VERSION "HNNBNNNYNNNNNNNNNNNNNNNNNNNNNNNNNNNNNNNNNN/4/%%%/4/'%**4NNN///"

NS_ :

BS_:

BU_: AEM BAP_Tester E_Sound FBK FLA Gateway Gateway_PAG ISE MRR_HL MRR_HR NightVision RDK SAK SAK2 SCR STH_MLBevo TopView

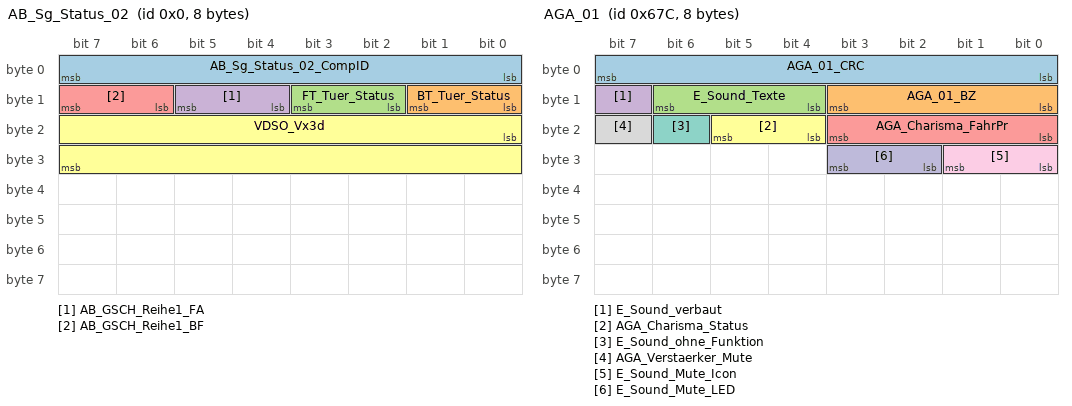
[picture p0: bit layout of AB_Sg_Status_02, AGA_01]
BO_ 0 AB_Sg_Status_02: 8 Gateway
 SG_ AB_Sg_Status_02_CompID : 0|8@1+ (1.0,0.0) [0.0|255] ""  Vector__XXX
 SG_ BT_Tuer_Status : 8|2@1+ (1.0,0.0) [0.0|3] ""  Vector__XXX
 SG_ FT_Tuer_Status : 10|2@1+ (1.0,0.0) [0.0|3] ""  Vector__XXX
 SG_ AB_GSCH_Reihe1_FA : 12|2@1+ (1.0,0.0) [0.0|3] ""  Vector__XXX
 SG_ AB_GSCH_Reihe1_BF : 14|2@1+ (1.0,0.0) [0.0|3] ""  Vector__XXX
 SG_ VDSO_Vx3d : 16|16@1+ (0.0039,-127.7874) [-127.7874|127.7913] "Unit_MeterPerSecon"  FBK

BO_ 1469 AEM_01: 8 AEM
 SG_ AEM_Temp_Abschaltung : 58|2@1+ (1.0,0.0) [0.0|3] ""  Gateway,Gateway_PAG
 SG_ AEM_Status_Regelung : 60|3@1+ (1.0,0.0) [0.0|7] ""  Gateway,Gateway_PAG

BO_ 1660 AGA_01: 8 E_Sound
 SG_ AGA_01_CRC : 0|8@1+ (1,0) [0|255] ""  Gateway,Gateway_PAG
 SG_ AGA_01_BZ : 8|4@1+ (1,0) [0|15] ""  Gateway,Gateway_PAG
 SG_ E_Sound_Texte : 12|3@1+ (1.0,0.0) [0.0|7] ""  Gateway,Gateway_PAG,ISE
 SG_ E_Sound_verbaut : 15|1@1+ (1.0,0.0) [0.0|1] ""  Gateway,Gateway_PAG
 SG_ AGA_Charisma_FahrPr : 16|4@1+ (1.0,0.0) [0.0|15] ""  Gateway,Gateway_PAG
 SG_ AGA_Charisma_Status : 20|2@1+ (1.0,0.0) [0.0|3] ""  Gateway,Gateway_PAG
 SG_ E_Sound_ohne_Funktion : 22|1@1+ (1.0,0.0) [0.0|1] ""  Gateway,Gateway_PAG
 SG_ AGA_Verstaerker_Mute : 23|1@1+ (1.0,0.0) [0.0|1] ""  Gateway,Gateway_PAG
 SG_ E_Sound_Mute_Icon : 24|2@1+ (1.0,0.0) [0.0|3] ""  Gateway,Gateway_PAG
 SG_ E_Sound_Mute_LED : 26|2@1+ (1.0,0.0) [0.0|3] ""  Gateway,Gateway_PAG

BO_ 64 Airbag_01: 8 Gateway
 SG_ Airbag_01_CRC : 0|8@1+ (1,0) [0|255] ""  Vector__XXX
 SG_ Airbag_01_BZ : 8|4@1+ (1,0) [0|15] ""  Vector__XXX
 SG_ AB_RGS_Anst : 12|4@1+ (1.0,0.0) [0.0|15] ""  Vector__XXX
 SG_ AB_Front_Crash : 16|1@1+ (1.0,0.0) [0.0|1] ""  Vector__XXX
 SG_ AB_Heck_Crash : 17|1@1+ (1.0,0.0) [0.0|1] ""  Vector__XXX
 SG_ AB_SF_Crash : 18|1@1+ (1.0,0.0) [0.0|1] ""  Vector__XXX
 SG_ AB_SB_Crash : 19|1@1+ (1.0,0.0) [0.0|1] ""  Vector__XXX
 SG_ AB_Rollover_Crash : 20|1@1+ (1.0,0.0) [0.0|1] ""  Vector__XXX
 SG_ AB_Crash_Int : 21|3@1+ (1.0,0.0) [0.0|7] ""  E_Sound,ISE,STH_MLBevo
 SG_ AB_Lampe : 24|1@1+ (1.0,0.0) [0.0|1] ""  Vector__XXX
 SG_ AB_Deaktiviert : 25|1@1+ (1.0,0.0) [0.0|1] ""  Vector__XXX
 SG_ AB_VB_deaktiviert : 26|1@1+ (1.0,0.0) [0.0|1] ""  Vector__XXX
 SG_ AB_Systemfehler : 27|1@1+ (1.0,0.0) [0.0|1] ""  Vector__XXX
 SG_ AB_Diagnose : 28|1@1+ (1.0,0.0) [0.0|1] ""  Vector__XXX
 SG_ AB_Stellgliedtest : 29|1@1+ (1.0,0.0) [0.0|1] ""  STH_MLBevo
 SG_ AB_Erh_Auf_VB : 30|2@1+ (1.0,0.0) [0.0|3] ""  Vector__XXX
 SG_ AB_Gurtwarn_VF : 32|1@1+ (1.0,0.0) [0.0|1] ""  Vector__XXX
 SG_ AB_Gurtwarn_VB : 33|1@1+ (1.0,0.0) [0.0|1] ""  Vector__XXX
 SG_ AB_Anzeige_Fussg : 34|2@1+ (1.0,0.0) [0.0|3] ""  Vector__XXX
 SG_ AB_Texte_AKS : 36|2@1+ (1.0,0.0) [0.0|3] ""  Vector__XXX
 SG_ AB_MKB_gueltig : 39|1@1+ (1.0,0.0) [0.0|1] ""  Vector__XXX
 SG_ AB_MKB_Anforderung : 40|1@1+ (1.0,0.0) [0.0|1] ""  Vector__XXX
 SG_ AB_Versorgungsspannung : 41|1@1+ (1.0,0.0) [0.0|1] ""  Vector__XXX
 SG_ AB_Deaktivierung_HV : 42|3@1+ (1.0,0.0) [0.0|7] ""  Vector__XXX
 SG_ AB_EDR_Trigger : 45|2@1+ (1.0,0.0) [0.0|3] ""  Vector__XXX
 SG_ AB_Belegung_VF : 47|2@1+ (1.0,0.0) [0.0|3] ""  FBK
 SG_ SC_Masterzeit_Offset : 53|2@1+ (5.08,0) [0.00|15.24] "Unit_Secon"  Vector__XXX
 SG_ SC_LowSpeedCrashErkannt : 55|2@1+ (1.0,0.0) [0.0|3] ""  Vector__XXX
 SG_ SC_Masterzeit : 57|7@1+ (0.04,0) [0.00|5.04] "Unit_Secon"  NightVision

BO_ 1312 Airbag_02: 8 Gateway
 SG_ Airbag_02_CRC : 0|8@1+ (1,0) [0|255] ""  Vector__XXX
 SG_ Airbag_02_BZ : 8|4@1+ (1,0) [0|15] ""  Vector__XXX
 SG_ LoGeWa_Event_Kombiwarnung : 12|4@1+ (1.0,0.0) [0.0|15] ""  Vector__XXX
 SG_ AB_Anforderung_eCall : 16|1@1+ (1.0,0.0) [0.0|1] ""  Vector__XXX
 SG_ AB_Anprall_Seite_Beifahrer : 17|1@1+ (1.0,0.0) [0.0|1] ""  Vector__XXX
 SG_ AB_Anprall_Rollover : 18|1@1+ (1.0,0.0) [0.0|1] ""  Vector__XXX
 SG_ AB_Anprall_FGS : 19|1@1+ (1.0,0.0) [0.0|1] ""  Vector__XXX
 SG_ AB_Anprall_Front_Beifahrer : 20|1@1+ (1.0,0.0) [0.0|1] ""  Vector__XXX
 SG_ AB_Anprall_Front_Fahrer : 21|1@1+ (1.0,0.0) [0.0|1] ""  Vector__XXX
 SG_ AB_Anprall_Heck_Beifahrer : 22|1@1+ (1.0,0.0) [0.0|1] ""  Vector__XXX
 SG_ AB_Anprall_Heck_Fahrer : 23|1@1+ (1.0,0.0) [0.0|1] ""  Vector__XXX
 SG_ AB_Wickelklappung_Reihe2_MI : 24|2@1+ (1.0,0.0) [0.0|3] ""  Vector__XXX
 SG_ AB_Belegung_VB : 26|2@1+ (1.0,0.0) [0.0|3] ""  FBK
 SG_ AB_Abschaltanf_SIH_BF : 28|1@1+ (1.0,0.0) [0.0|1] ""  Vector__XXX
 SG_ AB_Anprall_Seite_Fahrer : 29|1@1+ (1.0,0.0) [0.0|1] ""  Vector__XXX
 SG_ SC_PAO_Schriftzug_Anf : 30|2@1+ (1.0,0.0) [0.0|3] ""  Vector__XXX
 SG_ SC_PAO_ON_Anf : 32|2@1+ (1.0,0.0) [0.0|3] ""  Vector__XXX
 SG_ SC_PAO_OFF_Anf : 34|2@1+ (1.0,0.0) [0.0|3] ""  Vector__XXX
 SG_ AB_Crashschwere : 36|3@1+ (1.0,0.0) [0.0|7] ""  Vector__XXX
 SG_ AB_Anforderung_USM : 39|1@1+ (1.0,0.0) [0.0|1] ""  Vector__XXX
 SG_ AB_Gurtschloss_FA : 40|2@1+ (1.0,0.0) [0.0|3] ""  FBK
 SG_ AB_Gurtschloss_BF : 42|2@1+ (1.0,0.0) [0.0|3] ""  FBK
 SG_ AB_Gurtschloss_Reihe2_FA : 44|2@1+ (1.0,0.0) [0.0|3] ""  FBK
 SG_ AB_Gurtschloss_Reihe2_MI : 46|2@1+ (1.0,0.0) [0.0|3] ""  FBK
 SG_ AB_Gurtschloss_Reihe2_BF : 48|2@1+ (1.0,0.0) [0.0|3] ""  FBK
 SG_ AB_Gurtschloss_Reihe3_FA : 50|2@1+ (1.0,0.0) [0.0|3] ""  FBK
 SG_ AB_Gurtschloss_Reihe3_MI : 52|2@1+ (1.0,0.0) [0.0|3] ""  FBK
 SG_ AB_Gurtschloss_Reihe3_BF : 54|2@1+ (1.0,0.0) [0.0|3] ""  FBK
 SG_ AB_Sitzpos_Sens_FA : 56|2@1+ (1.0,0.0) [0.0|3] ""  Vector__XXX
 SG_ AB_Sitzpos_Sens_BF : 58|2@1+ (1.0,0.0) [0.0|3] ""  Vector__XXX
 SG_ AB_Wickelklappung_Reihe2_BF : 60|2@1+ (1.0,0.0) [0.0|3] ""  Vector__XXX
 SG_ AB_Wickelklappung_Reihe2_FA : 62|2@1+ (1.0,0.0) [0.0|3] ""  Vector__XXX

BO_ 1349 Airbag_04: 8 Gateway
 SG_ AB_Gurtwarn_Reihe2_FA : 20|2@1+ (1.0,0.0) [0.0|3] ""  Vector__XXX
 SG_ AB_Gurtwarn_Reihe2_BF : 22|2@1+ (1.0,0.0) [0.0|3] ""  Vector__XXX
 SG_ AbstWarn_MV_FAS_Fkt_Status : 24|2@1+ (1.0,0.0) [0.0|3] ""  Vector__XXX
 SG_ WarnBrems_Charisma_Status : 26|2@1+ (1.0,0.0) [0.0|3] ""  Vector__XXX
 SG_ WarnBrems_Charisma_FahrPr : 28|4@1+ (1.0,0.0) [0.0|15] ""  Vector__XXX
 SG_ AB_Gurtwarn_Reihe2_MI : 32|2@1+ (1.0,0.0) [0.0|3] ""  Vector__XXX
 SG_ AB_Gurtwarn_Reihe3_FA : 34|2@1+ (1.0,0.0) [0.0|3] ""  Vector__XXX
 SG_ AB_Gurtwarn_Reihe3_MI : 36|2@1+ (1.0,0.0) [0.0|3] ""  Vector__XXX
 SG_ AB_Gurtwarn_Reihe3_BF : 38|2@1+ (1.0,0.0) [0.0|3] ""  Vector__XXX
 SG_ LGI_FAS_Fkt_Status : 40|2@1+ (1.0,0.0) [0.0|3] ""  Vector__XXX
 SG_ PreCrash_FAS_Fkt_Status : 42|3@1+ (1.0,0.0) [0.0|7] ""  Vector__XXX
 SG_ AB_SBR_hinten_verbau : 48|2@1+ (1.0,0.0) [0.0|3] ""  Vector__XXX
 SG_ AWV_Einstellung_System_ASG : 51|1@1+ (1.0,0.0) [0.0|1] ""  Vector__XXX
 SG_ AWV_Einstellung_Warnung_ASG : 52|3@1+ (1.0,0.0) [0.0|7] ""  Vector__XXX
 SG_ SC_PreSense_Modus_Warnung_NV : 55|3@1+ (1.0,0.0) [0.0|7] ""  NightVision
 SG_ SC_PreSense_Modus_Warnung_MV : 58|3@1+ (1.0,0.0) [0.0|7] ""  Vector__XXX
 SG_ SC_PreSense_Modus_System_MV : 61|1@1+ (1.0,0.0) [0.0|1] ""  Vector__XXX
 SG_ SC_PreSense_Modus_System_NV : 62|1@1+ (1.0,0.0) [0.0|1] ""  NightVision
 SG_ SC_PreSense_Modus_System_KAS : 63|1@1+ (1.0,0.0) [0.0|1] ""  Vector__XXX

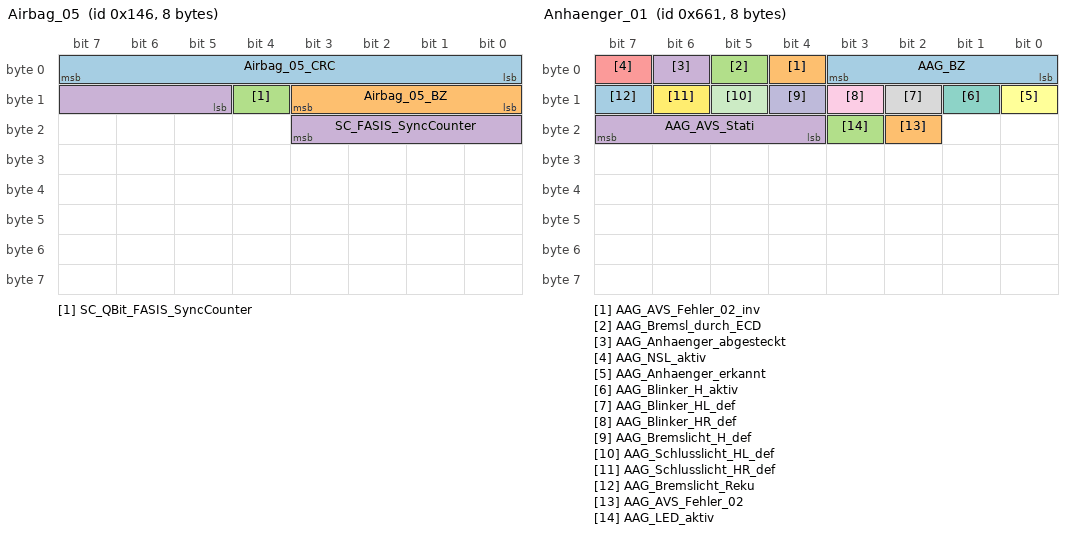
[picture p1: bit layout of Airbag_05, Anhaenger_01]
BO_ 326 Airbag_05: 8 Gateway
 SG_ Airbag_05_CRC : 0|8@1+ (1,0) [0|255] ""  NightVision
 SG_ Airbag_05_BZ : 8|4@1+ (1,0) [0|15] ""  NightVision
 SG_ SC_QBit_FASIS_SyncCounter : 12|1@1+ (1.0,0.0) [0.0|1] ""  NightVision
 SG_ SC_FASIS_SyncCounter : 13|7@1+ (1,0) [0|127] "Unit_None"  NightVision

BO_ 1633 Anhaenger_01: 8 Gateway
 SG_ AAG_BZ : 0|4@1+ (1,0) [0|15] ""  Vector__XXX
 SG_ AAG_AVS_Fehler_02_inv : 4|1@1+ (1.0,0.0) [0.0|1] ""  Vector__XXX
 SG_ AAG_Bremsl_durch_ECD : 5|1@1+ (1.0,0.0) [0.0|1] ""  Vector__XXX
 SG_ AAG_Anhaenger_abgesteckt : 6|1@1+ (1.0,0.0) [0.0|1] ""  Vector__XXX
 SG_ AAG_NSL_aktiv : 7|1@1+ (1.0,0.0) [0.0|1] ""  Vector__XXX
 SG_ AAG_Anhaenger_erkannt : 8|1@1+ (1.0,0.0) [0.0|1] ""  MRR_HL,MRR_HR,TopView
 SG_ AAG_Blinker_H_aktiv : 9|1@1+ (1.0,0.0) [0.0|1] ""  Vector__XXX
 SG_ AAG_Blinker_HL_def : 10|1@1+ (1.0,0.0) [0.0|1] ""  Vector__XXX
 SG_ AAG_Blinker_HR_def : 11|1@1+ (1.0,0.0) [0.0|1] ""  Vector__XXX
 SG_ AAG_Bremslicht_H_def : 12|1@1+ (1.0,0.0) [0.0|1] ""  Vector__XXX
 SG_ AAG_Schlusslicht_HL_def : 13|1@1+ (1.0,0.0) [0.0|1] ""  Vector__XXX
 SG_ AAG_Schlusslicht_HR_def : 14|1@1+ (1.0,0.0) [0.0|1] ""  Vector__XXX
 SG_ AAG_Bremslicht_Reku : 15|1@1+ (1.0,0.0) [0.0|1] ""  Vector__XXX
 SG_ AAG_AVS_Fehler_02 : 18|1@1+ (1.0,0.0) [0.0|1] ""  Vector__XXX
 SG_ AAG_LED_aktiv : 19|1@1+ (1.0,0.0) [0.0|1] ""  Vector__XXX
 SG_ AAG_AVS_Stati : 20|4@1+ (1.0,0.0) [0.0|15] ""  Vector__XXX

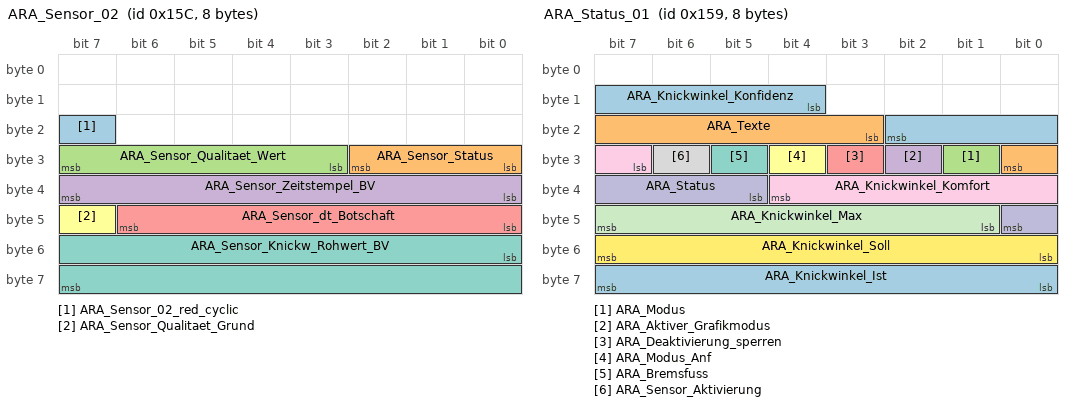
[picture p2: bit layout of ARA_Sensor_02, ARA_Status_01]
BO_ 348 ARA_Sensor_02: 8 TopView
 SG_ ARA_Sensor_02_red_cyclic : 23|1@1+ (1.0,0.0) [0.0|1] ""  Gateway,Gateway_PAG
 SG_ ARA_Sensor_Status : 24|3@1+ (1.0,0.0) [0.0|7] ""  Gateway,Gateway_PAG
 SG_ ARA_Sensor_Qualitaet_Wert : 27|5@1+ (0.04,0) [0.00|1.24] "Unit_None"  Gateway,Gateway_PAG
 SG_ ARA_Sensor_Zeitstempel_BV : 32|8@1+ (0.01,0) [0.00|2.55] "Unit_Secon"  Gateway,Gateway_PAG
 SG_ ARA_Sensor_dt_Botschaft : 40|7@1+ (0.01,0) [0.00|1.27] "Unit_Secon"  Gateway,Gateway_PAG
 SG_ ARA_Sensor_Qualitaet_Grund : 47|1@1+ (1.0,0.0) [0.0|1] ""  Gateway,Gateway_PAG
 SG_ ARA_Sensor_Knickw_Rohwert_BV : 48|16@1+ (0.0055,-180) [-180.0000|179.9970] "Unit_DegreOfArc"  Gateway,Gateway_PAG

BO_ 345 ARA_Status_01: 8 Gateway
 SG_ ARA_Knickwinkel_Konfidenz : 12|7@1+ (1,0) [0|120] "Unit_DegreOfArc"  TopView
 SG_ ARA_Texte : 19|6@1+ (1.0,0.0) [0.0|63] ""  Vector__XXX
 SG_ ARA_Modus : 25|1@1+ (1.0,0.0) [0.0|1] ""  Vector__XXX
 SG_ ARA_Aktiver_Grafikmodus : 26|1@1+ (1.0,0.0) [0.0|1] ""  Vector__XXX
 SG_ ARA_Deaktivierung_sperren : 27|1@1+ (1.0,0.0) [0.0|1] ""  TopView
 SG_ ARA_Modus_Anf : 28|1@1+ (1.0,0.0) [0.0|1] ""  Vector__XXX
 SG_ ARA_Bremsfuss : 29|1@1+ (1.0,0.0) [0.0|1] ""  Vector__XXX
 SG_ ARA_Sensor_Aktivierung : 30|1@1+ (1.0,0.0) [0.0|1] ""  TopView
 SG_ ARA_Knickwinkel_Komfort : 31|6@1+ (1,0) [0|60] "Unit_DegreOfArc"  TopView
 SG_ ARA_Status : 37|4@1+ (1.0,0.0) [0.0|15] ""  TopView
 SG_ ARA_Knickwinkel_Max : 41|7@1+ (1,0) [0|120] "Unit_DegreOfArc"  TopView
 SG_ ARA_Knickwinkel_Soll : 48|8@1+ (1,-125) [-125|126] "Unit_DegreOfArc"  TopView
 SG_ ARA_Knickwinkel_Ist : 56|8@1+ (1,-125) [-125|126] "Unit_DegreOfArc"  TopView

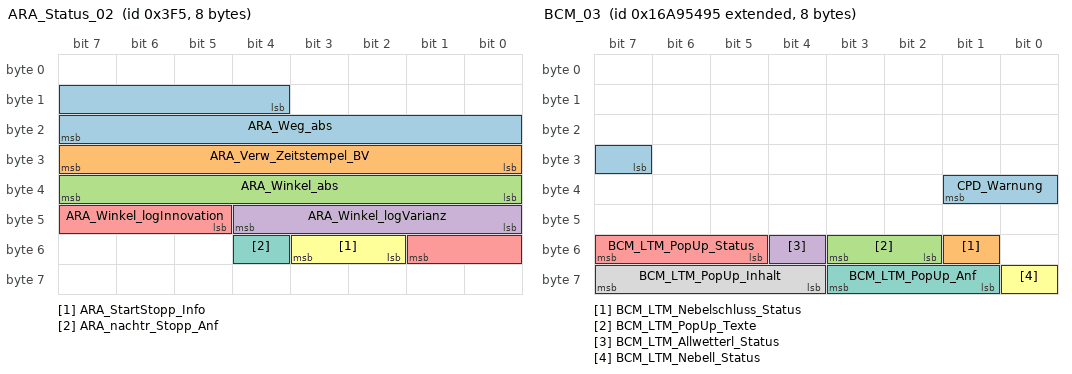
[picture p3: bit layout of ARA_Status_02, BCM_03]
BO_ 1013 ARA_Status_02: 8 Gateway
 SG_ ARA_Weg_abs : 12|12@1+ (1,0) [0|4095] "Unit_MilliMeter"  TopView
 SG_ ARA_Verw_Zeitstempel_BV : 24|8@1+ (0.01,0) [0.00|2.55] "Unit_Secon"  TopView
 SG_ ARA_Winkel_abs : 32|8@1+ (0.01,-1.2) [-1.20|1.20] "Unit_Radia"  TopView
 SG_ ARA_Winkel_logVarianz : 40|5@1+ (1,0) [0|31] "Unit_SquarRadia"  TopView
 SG_ ARA_Winkel_logInnovation : 45|5@1+ (1,0) [0|31] "Unit_SquarRadia"  TopView
 SG_ ARA_StartStopp_Info : 50|2@1+ (1.0,0.0) [0.0|3] ""  Vector__XXX
 SG_ ARA_nachtr_Stopp_Anf : 52|1@1+ (1.0,0.0) [0.0|1] ""  Vector__XXX

BO_ 2536767264 BAP_Debug_Cmd: 8 BAP_Tester
 SG_ BAP_Debug_Cmd : 0|16@1+ (1.0,0.0) [0.0|65535] ""  E_Sound,Gateway,Gateway_PAG,MRR_HR,NightVision,RDK,TopView

BO_ 2536767280 BAP_Debug_Data: 8 E_Sound
 SG_ BAP_Debug_Data : 0|64@1+ (1.0,0.0) [0.0|18446744073709551615] ""  BAP_Tester

BO_ 2536708096 BAP_Nightvision_ASG_01: 8 Gateway
 SG_ BAP_Nightvision_ASG_01_Header : 0|8@1+ (1.0,0.0) [0.0|255] ""  NightVision

BO_ 2536708097 BAP_Nightvision_ASG_02: 8 Gateway
 SG_ BAP_Nightvision_ASG_02_Header : 0|8@1+ (1.0,0.0) [0.0|255] ""  NightVision

BO_ 2536708112 BAP_Nightvision_FSG_01: 8 NightVision
 SG_ BAP_Nightvision_FSG_01_Header : 0|8@1+ (1.0,0.0) [0.0|255] ""  Gateway,Gateway_PAG

BO_ 2536704513 BAP_OPS_ASG_02: 8 TopView
 SG_ BAP_OPS_ASG_02_Header : 0|8@1+ (1.0,0.0) [0.0|255] ""  Gateway,Gateway_PAG

BO_ 2536704528 BAP_OPS_FSG_01: 8 Gateway
 SG_ BAP_OPS_FSG_01_Header : 0|8@1+ (1.0,0.0) [0.0|255] ""  TopView

BO_ 2536704529 BAP_OPS_FSG_02: 8 Gateway
 SG_ BAP_OPS_FSG_02_Header : 0|8@1+ (1.0,0.0) [0.0|255] ""  TopView

BO_ 2536703744 BAP_RDK_ASG_01: 8 Gateway
 SG_ BAP_RDK_ASG_01_Header : 0|8@1+ (1.0,0.0) [0.0|255] ""  RDK

BO_ 2536703745 BAP_RDK_ASG_02: 8 Gateway
 SG_ BAP_RDK_ASG_02_Header : 0|8@1+ (1.0,0.0) [0.0|255] ""  RDK

BO_ 2536703746 BAP_RDK_ASG_03: 8 Gateway
 SG_ BAP_RDK_ASG_03_Header : 0|8@1+ (1.0,0.0) [0.0|255] ""  RDK

BO_ 2536703760 BAP_RDK_FSG_01: 8 RDK
 SG_ BAP_RDK_FSG_01_Header : 0|8@1+ (1.0,0.0) [0.0|255] ""  Gateway,Gateway_PAG

BO_ 2536704768 BAP_RVC_ASG_01: 8 Gateway
 SG_ BAP_RVC_ASG_01_Header : 0|64@1+ (1.0,0.0) [0.0|18446744073709551615] ""  TopView

BO_ 2536704784 BAP_RVC_FSG_01: 8 TopView
 SG_ BAP_RVC_FSG_01_Header : 0|8@1+ (1.0,0.0) [0.0|255] ""  Gateway,Gateway_PAG

BO_ 2536728064 BAP_SoundControl2_ASG_01: 8 Gateway
 SG_ BAP_SoundControl2_ASG_01_Header : 0|64@1+ (1.0,0.0) [0.0|18446744073709551615] ""  ISE

BO_ 2536728080 BAP_SoundControl2_FSG_01: 8 ISE
 SG_ BAP_SoundControl2_FSG_01_Header : 0|64@1+ (1.0,0.0) [0.0|18446744073709551615] ""  Gateway,Gateway_PAG

BO_ 2536719360 BAP_SoundControl_ASG_01: 8 Gateway
 SG_ BAP_SoundControl_ASG_01_Header : 0|8@1+ (1,0) [0|255] "Unit_None"  E_Sound

BO_ 2536719376 BAP_SoundControl_FSG_01: 8 E_Sound
 SG_ BAP_SoundControl_FSG_01_Header : 0|8@1+ (1,0) [0|255] "Unit_None"  Gateway,Gateway_PAG

BO_ 2536708608 BAP_SWA_ASG_01: 8 Gateway
 SG_ BAP_SWA_ASG_01_Header : 0|8@1+ (1.0,0.0) [0.0|255] ""  MRR_HR

BO_ 2536708609 BAP_SWA_ASG_02: 8 Gateway
 SG_ BAP_SWA_ASG_02_Header : 0|8@1+ (1.0,0.0) [0.0|255] ""  MRR_HR

BO_ 2536708624 BAP_SWA_FSG_01: 8 MRR_HR
 SG_ BAP_SWA_FSG_01_Header : 0|8@1+ (1.0,0.0) [0.0|255] ""  Gateway,Gateway_PAG

BO_ 1626 BCM_01: 8 Gateway
 SG_ BCM_Bremsbelag_Sensor : 12|1@1+ (1.0,0.0) [0.0|1] ""  Vector__XXX
 SG_ BCM_Bremsfluessigkeit_Sensor : 13|1@1+ (1.0,0.0) [0.0|1] ""  Vector__XXX
 SG_ BCM1_Licht_Warn : 14|1@1+ (1.0,0.0) [0.0|1] ""  Vector__XXX
 SG_ BCM_Waschwasser_Sensor : 15|1@1+ (1.0,0.0) [0.0|1] ""  TopView
 SG_ BCM_Kuehlmittel_Sensor : 16|1@1+ (1.0,0.0) [0.0|1] ""  Vector__XXX
 SG_ BCM1_Kl_15_HW_erkannt : 17|1@1+ (1.0,0.0) [0.0|1] ""  Vector__XXX
 SG_ BCM1_Kl_15_Sig_HW_erkannt : 18|1@1+ (1.0,0.0) [0.0|1] ""  Vector__XXX
 SG_ BCM_Kuehlmittel_Sensor_02 : 19|1@1+ (1.0,0.0) [0.0|1] ""  Vector__XXX
 SG_ BCM1_Hinweis_Lichtnachlauf : 20|1@1+ (1.0,0.0) [0.0|1] ""  Vector__XXX
 SG_ BCM_Offroad_Taste : 21|1@1+ (1.0,0.0) [0.0|1] ""  Vector__XXX
 SG_ BCM_Hybrid_StSt_Taste_Fehler : 23|1@1+ (1.0,0.0) [0.0|1] ""  Vector__XXX
 SG_ BCM_Hybrid_StartStopp_Taste : 24|1@1+ (1.0,0.0) [0.0|1] ""  Vector__XXX
 SG_ BCM1_Warnblink_Taster : 25|1@1+ (1.0,0.0) [0.0|1] ""  Vector__XXX
 SG_ BCM1_Valet_Parking_Taster : 26|1@1+ (1.0,0.0) [0.0|1] ""  Vector__XXX
 SG_ BCM1_LDS_Stellung : 27|3@1+ (1.0,0.0) [0.0|7] ""  NightVision
 SG_ BCM1_Rueckfahrlicht_Schalter : 30|1@1+ (1.0,0.0) [0.0|1] ""  Vector__XXX
 SG_ BCM1_MH_Schalter : 31|1@1+ (1.0,0.0) [0.0|1] ""  TopView
 SG_ BCM1_MH_WIV_Schalter : 32|1@1+ (1.0,0.0) [0.0|1] ""  Vector__XXX
 SG_ BCM_Eco_Charisma_Taste : 33|1@1+ (1.0,0.0) [0.0|1] ""  Vector__XXX
 SG_ BCM1_NV_Taster : 34|1@1+ (1.0,0.0) [0.0|1] ""  NightVision
 SG_ BCM1_AFS_Lampe : 35|1@1+ (1.0,0.0) [0.0|1] ""  Vector__XXX
 SG_ BCM1_Reisemodus_Texte : 36|2@1+ (1.0,0.0) [0.0|3] ""  Vector__XXX
 SG_ BCM1_Lichtwarn_Texte : 38|2@1+ (1.0,0.0) [0.0|3] ""  Vector__XXX
 SG_ Gong_TFL_Umschaltung : 40|1@1+ (1.0,0.0) [0.0|1] ""  Vector__XXX
 SG_ UGDO_Function_01 : 41|3@1+ (1.0,0.0) [0.0|7] ""  Vector__XXX
 SG_ APS_Tongeber_defekt : 44|1@1+ (1.0,0.0) [0.0|1] ""  Vector__XXX
 SG_ BCM1_EasyEntry_Status : 45|1@1+ (1.0,0.0) [0.0|1] ""  Vector__XXX
 SG_ BCM1_Lenksaeule_aktiv : 46|1@1+ (1.0,0.0) [0.0|1] ""  FBK
 SG_ BCM1_St_SW_Diebstahl_links : 47|1@1+ (1.0,0.0) [0.0|1] ""  Vector__XXX
 SG_ BCM1_St_SW_Diebstahl_rechts : 48|1@1+ (1.0,0.0) [0.0|1] ""  Vector__XXX
 SG_ ISP_Dimmung_ASP_02 : 49|6@1+ (0.0226,0) [0.0000|1.4012] "Unit_Volt"  Vector__XXX
 SG_ BCM1_Schluesselsuche_Anf : 55|1@1+ (1.0,0.0) [0.0|1] ""  Vector__XXX
 SG_ BCM1_Fahrlicht_Hinweis : 62|1@1+ (1.0,0.0) [0.0|1] ""  Vector__XXX
 SG_ BCM_HDF_betaetigt : 63|1@1+ (1.0,0.0) [0.0|1] ""  Vector__XXX

BO_ 2527679637 BCM_03: 8 Gateway
 SG_ CPD_Warnung : 31|3@1+ (1.0,0.0) [0.0|7] ""  Vector__XXX
 SG_ BCM_LTM_Nebelschluss_Status : 49|1@1+ (1.0,0.0) [0.0|1] ""  Vector__XXX
 SG_ BCM_LTM_PopUp_Texte : 50|2@1+ (1.0,0.0) [0.0|3] ""  Vector__XXX
 SG_ BCM_LTM_Allwetterl_Status : 52|1@1+ (1.0,0.0) [0.0|1] ""  Vector__XXX
 SG_ BCM_LTM_PopUp_Status : 53|3@1+ (1.0,0.0) [0.0|7] ""  NightVision
 SG_ BCM_LTM_Nebell_Status : 56|1@1+ (1.0,0.0) [0.0|1] ""  Vector__XXX
 SG_ BCM_LTM_PopUp_Anf : 57|3@1+ (1.0,0.0) [0.0|7] ""  NightVision
 SG_ BCM_LTM_PopUp_Inhalt : 60|4@1+ (1.0,0.0) [0.0|15] ""  Vector__XXX

BO_ 961 BCM_Taster_01: 8 Gateway
 SG_ Heckrollo_2_Taster : 10|2@1+ (1.0,0.0) [0.0|3] ""  Vector__XXX
 SG_ APS_Taster : 12|2@1+ (1.0,0.0) [0.0|3] ""  Vector__XXX
 SG_ PLA_Taster : 14|2@1+ (1.0,0.0) [0.0|3] ""  Vector__XXX
 SG_ ESP_Off_Taster : 16|2@1+ (1.0,0.0) [0.0|3] ""  Vector__XXX
 SG_ HDC_Taster : 18|2@1+ (1.0,0.0) [0.0|3] ""  Vector__XXX
 SG_ AVH_Taster : 20|2@1+ (1.0,0.0) [0.0|3] ""  Vector__XXX
 SG_ Display_Taster : 22|2@1+ (1.0,0.0) [0.0|3] ""  Vector__XXX
 SG_ Heckrollo_Taster : 24|2@1+ (1.0,0.0) [0.0|3] ""  Vector__XXX
 SG_ Spoiler_Taster : 26|2@1+ (1.0,0.0) [0.0|3] ""  Vector__XXX
 SG_ Drivesel_1_Taster : 28|2@1+ (1.0,0.0) [0.0|3] ""  Vector__XXX
 SG_ Drivesel_2_Taster : 30|2@1+ (1.0,0.0) [0.0|3] ""  Vector__XXX
 SG_ Sideview_Taster : 32|2@1+ (1.0,0.0) [0.0|3] ""  TopView
 SG_ LIM_PAO_Alivesignal : 34|4@1+ (1,0) [0|15] ""  Vector__XXX
 SG_ LKS_Taster : 38|2@1+ (1.0,0.0) [0.0|3] ""  Vector__XXX
 SG_ SWA_Taster : 40|2@1+ (1.0,0.0) [0.0|3] ""  MRR_HR
 SG_ LIM_bCall_Taster : 42|1@1+ (1.0,0.0) [0.0|1] ""  Vector__XXX
 SG_ eCall_Taste : 43|2@1+ (1.0,0.0) [0.0|3] ""  Vector__XXX
 SG_ PLA_Taster_Fehler_Roh : 45|1@1+ (1.0,0.0) [0.0|1] ""  Vector__XXX
 SG_ LIM_PAO_ON_Status : 46|2@1+ (1.0,0.0) [0.0|3] ""  Vector__XXX
 SG_ LIM_PAO_OFF_Status : 48|2@1+ (1.0,0.0) [0.0|3] ""  Vector__XXX
 SG_ LIM_PAO_Schriftzug_Status : 50|2@1+ (1.0,0.0) [0.0|3] ""  Vector__XXX
 SG_ Spoiler_LED_Status : 52|2@1+ (1.0,0.0) [0.0|3] ""  Vector__XXX
 SG_ AVH_LED_Status : 54|2@1+ (1.0,0.0) [0.0|3] ""  Vector__XXX
 SG_ HDC_LED_Status : 56|2@1+ (1.0,0.0) [0.0|3] ""  Vector__XXX
 SG_ PLA_LED_Status : 60|2@1+ (1.0,0.0) [0.0|3] ""  Vector__XXX
 SG_ APS_LED_Status : 62|2@1+ (1.0,0.0) [0.0|3] ""  Vector__XXX

BO_ 1432 BCM_Taster_02: 8 Gateway
 SG_ BCM_BFS_Fernsteuerung_aktiv : 28|1@1+ (1.0,0.0) [0.0|1] ""  Vector__XXX
 SG_ BCM_Soundklappe_Taster : 29|1@1+ (1.0,0.0) [0.0|1] ""  ISE
 SG_ E_Sound_LED_Status : 30|2@1+ (1.0,0.0) [0.0|3] ""  E_Sound,ISE
 SG_ Pilot_Taster : 32|2@1+ (1.0,0.0) [0.0|3] ""  Vector__XXX
 SG_ BCM1_eSound_Taster : 34|2@1+ (1.0,0.0) [0.0|3] ""  E_Sound,ISE
 SG_ BCM_FS_Programmwippe : 37|1@1+ (1.0,0.0) [0.0|1] ""  Vector__XXX
 SG_ BCM_BFS_Programmwippe : 38|1@1+ (1.0,0.0) [0.0|1] ""  Vector__XXX
 SG_ BCM_FS_Multif_Taster : 39|1@1+ (1.0,0.0) [0.0|1] ""  Vector__XXX
 SG_ BCM_BFS_Multif_Taster : 40|1@1+ (1.0,0.0) [0.0|1] ""  Vector__XXX
 SG_ BCM_FS_Massage_Taster : 41|1@1+ (1.0,0.0) [0.0|1] ""  Vector__XXX
 SG_ BCM_BFS_Massage_Taster : 42|1@1+ (1.0,0.0) [0.0|1] ""  Vector__XXX
 SG_ BCM_FS_Pneumatik_Verstellung : 43|1@1+ (1.0,0.0) [0.0|1] ""  Vector__XXX
 SG_ BCM_BFS_Pneumatik_Verstellung : 44|1@1+ (1.0,0.0) [0.0|1] ""  Vector__XXX
 SG_ LIM_Rear_Mode : 45|1@1+ (1.0,0.0) [0.0|1] ""  Vector__XXX
 SG_ BCM1_NR_Ride_Height_Up_Taster : 46|2@1+ (1.0,0.0) [0.0|3] ""  Vector__XXX
 SG_ BCM1_NR_Ride_Height_Down_Taster : 48|2@1+ (1.0,0.0) [0.0|3] ""  Vector__XXX
 SG_ LIM_S_Rollo_vo : 50|3@1+ (1.0,0.0) [0.0|7] ""  Vector__XXX
 SG_ LIM_S_Rollo_hi : 53|3@1+ (1.0,0.0) [0.0|7] ""  Vector__XXX
 SG_ LIM_S_SAD_Vo : 56|4@1+ (1.0,0.0) [0.0|15] ""  Vector__XXX
 SG_ LIM_S_SAD_hi : 60|4@1+ (1.0,0.0) [0.0|15] ""  Vector__XXX

BO_ 2617189888 CCP_AGA_CRO_01: 8 Vector__XXX
 SG_ CCP_AGA_CRO_01_Data : 0|64@1+ (1,0) [0|1] ""  E_Sound,SAK2

BO_ 2617189889 CCP_AGA_DTO_01: 8 E_Sound
 SG_ CCP_AGA_DTO_01_Data : 0|64@1+ (1,0) [0|1] ""  Vector__XXX

BO_ 2617042432 CCP_Soundaktor_CRO_01: 8 Vector__XXX
 SG_ CCP_Soundaktor_CRO_01_Data : 0|64@1+ (1.0,0.0) [0.0|18446744073709551615] ""  ISE,SAK

BO_ 2617042433 CCP_Soundaktor_DTO_01: 8 ISE
 SG_ CCP_Soundaktor_DTO_01_Data : 0|64@1+ (1.0,0.0) [0.0|18446744073709551615] ""  Vector__XXX

BO_ 901 Charisma_01: 8 Gateway
 SG_ CHA_Ziel_FahrPr_AGA : 0|4@1+ (1.0,0.0) [0.0|15] ""  E_Sound,ISE,SAK2
 SG_ CHA_Ziel_FahrPr_ESP : 4|4@1+ (1.0,0.0) [0.0|15] ""  Vector__XXX
 SG_ CHA_Ziel_FahrPr_Freilauf : 8|4@1+ (1.0,0.0) [0.0|15] ""  Vector__XXX
 SG_ CHA_Fahrer_Umschaltung : 14|1@1+ (1.0,0.0) [0.0|1] ""  E_Sound,ISE,SAK,SAK2
 SG_ CHA_Fahrer_Umschaltung_BMA : 15|1@1+ (1.0,0.0) [0.0|1] ""  Vector__XXX
 SG_ CHA_Ziel_FahrPr_MO : 16|4@1+ (1.0,0.0) [0.0|15] ""  Vector__XXX
 SG_ CHA_Ziel_FahrPr_GE : 20|4@1+ (1.0,0.0) [0.0|15] ""  Vector__XXX
 SG_ CHA_Ziel_FahrPr_ALR : 24|4@1+ (1.0,0.0) [0.0|15] ""  Vector__XXX
 SG_ CHA_Ziel_FahrPr_MO_BZS : 28|4@1+ (1.0,0.0) [0.0|15] ""  Vector__XXX
 SG_ CHA_Ziel_FahrPr_DR : 32|4@1+ (1.0,0.0) [0.0|15] ""  Vector__XXX
 SG_ CHA_Ziel_FahrPr_VAQ : 36|4@1+ (1.0,0.0) [0.0|15] ""  Vector__XXX
 SG_ CHA_Ziel_FahrPr_AFS : 40|4@1+ (1.0,0.0) [0.0|15] ""  Vector__XXX
 SG_ CHA_Ziel_FahrPr_PreCrash : 44|4@1+ (1.0,0.0) [0.0|15] ""  Vector__XXX
 SG_ CHA_Ziel_FahrPr_EPS : 48|4@1+ (1.0,0.0) [0.0|15] ""  Vector__XXX
 SG_ CHA_Ziel_FahrPr_ACC : 52|4@1+ (1.0,0.0) [0.0|15] ""  Vector__XXX
 SG_ CHA_Ziel_FahrPr_SAK : 56|4@1+ (1.0,0.0) [0.0|15] ""  ISE,SAK
 SG_ CHA_Ziel_FahrPr_MO_StSt : 60|4@1+ (1.0,0.0) [0.0|15] ""  Vector__XXX

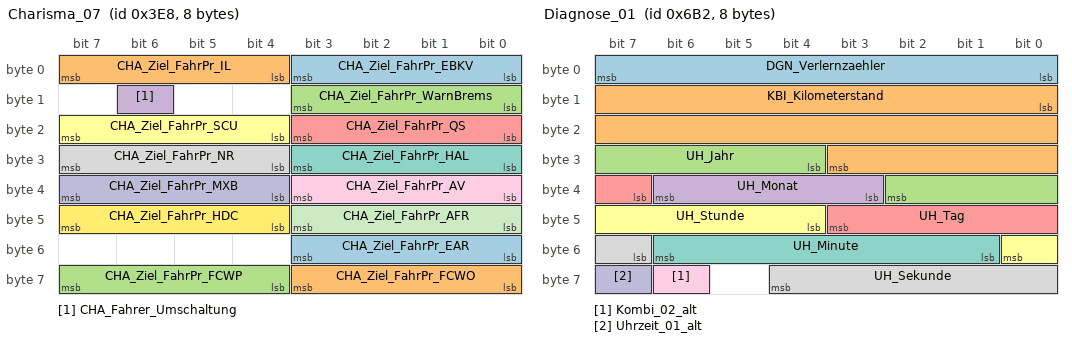
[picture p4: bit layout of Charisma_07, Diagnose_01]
BO_ 1000 Charisma_07: 8 Gateway
 SG_ CHA_Ziel_FahrPr_EBKV : 0|4@1+ (1.0,0.0) [0.0|15] ""  Vector__XXX
 SG_ CHA_Ziel_FahrPr_IL : 4|4@1+ (1.0,0.0) [0.0|15] ""  Vector__XXX
 SG_ CHA_Ziel_FahrPr_WarnBrems : 8|4@1+ (1.0,0.0) [0.0|15] ""  Vector__XXX
 SG_ CHA_Fahrer_Umschaltung : 14|1@1+ (1.0,0.0) [0.0|1] ""  Vector__XXX
 SG_ CHA_Ziel_FahrPr_QS : 16|4@1+ (1.0,0.0) [0.0|15] ""  Vector__XXX
 SG_ CHA_Ziel_FahrPr_SCU : 20|4@1+ (1.0,0.0) [0.0|15] ""  Vector__XXX
 SG_ CHA_Ziel_FahrPr_HAL : 24|4@1+ (1.0,0.0) [0.0|15] ""  Vector__XXX
 SG_ CHA_Ziel_FahrPr_NR : 28|4@1+ (1.0,0.0) [0.0|15] ""  Vector__XXX
 SG_ CHA_Ziel_FahrPr_AV : 32|4@1+ (1.0,0.0) [0.0|15] ""  TopView
 SG_ CHA_Ziel_FahrPr_MXB : 36|4@1+ (1.0,0.0) [0.0|15] ""  Vector__XXX
 SG_ CHA_Ziel_FahrPr_AFR : 40|4@1+ (1.0,0.0) [0.0|15] ""  Vector__XXX
 SG_ CHA_Ziel_FahrPr_HDC : 44|4@1+ (1.0,0.0) [0.0|15] ""  Vector__XXX
 SG_ CHA_Ziel_FahrPr_EAR : 48|4@1+ (1.0,0.0) [0.0|15] ""  Vector__XXX
 SG_ CHA_Ziel_FahrPr_FCWO : 56|4@1+ (1.0,0.0) [0.0|15] ""  Vector__XXX
 SG_ CHA_Ziel_FahrPr_FCWP : 60|4@1+ (1.0,0.0) [0.0|15] ""  Vector__XXX

BO_ 2617078272 DEV_AEM_Resp_00: 8 AEM
 SG_ DEV_AEM_Resp_00_Data : 0|64@1+ (1.0,0.0) [0.0|18446744073709551615] ""  Vector__XXX

BO_ 2617078527 DEV_AEM_Resp_FF: 8 AEM
 SG_ DEV_AEM_Resp_FF_Data : 0|64@1+ (1.0,0.0) [0.0|18446744073709551615] ""  Vector__XXX

BO_ 2617188864 DEV_AGA_Resp_00: 8 E_Sound
 SG_ DEV_AGA_Resp_00_Data : 0|64@1+ (1.0,0.0) [0.0|18446744073709551615] ""  Vector__XXX

BO_ 2617189119 DEV_AGA_Resp_FF: 8 E_Sound
 SG_ DEV_AGA_Resp_FF_Data : 0|64@1+ (1.0,0.0) [0.0|18446744073709551615] ""  Vector__XXX

BO_ 2617082368 DEV_FLA_Resp_00: 8 FLA
 SG_ DEV_FLA_Resp_00_Data : 0|64@1+ (1.0,0.0) [0.0|18446744073709551615] ""  Vector__XXX

BO_ 2617082623 DEV_FLA_Resp_FF: 8 FLA
 SG_ DEV_FLA_Resp_FF_Data : 0|64@1+ (1.0,0.0) [0.0|18446744073709551615] ""  Vector__XXX

BO_ 2617063936 DEV_Nightvision_Resp_00: 8 NightVision
 SG_ DEV_Nightvision_Resp_00_Data : 0|64@1+ (1.0,0.0) [0.0|18446744073709551615] ""  Vector__XXX

BO_ 2617064191 DEV_Nightvision_Resp_FF: 8 NightVision
 SG_ DEV_Nightvision_Resp_FF_Data : 0|64@1+ (1.0,0.0) [0.0|18446744073709551615] ""  Vector__XXX

BO_ 2617006592 DEV_RDK_Resp_00: 8 RDK
 SG_ DEV_RDK_Resp_00_Data : 0|64@1+ (1.0,0.0) [0.0|18446744073709551615] ""  Vector__XXX

BO_ 2617006847 DEV_RDK_Resp_FF: 8 RDK
 SG_ DEV_RDK_Resp_FF_Data : 0|64@1+ (1.0,0.0) [0.0|18446744073709551615] ""  Vector__XXX

BO_ 2617199104 DEV_RearView_Resp_00: 8 TopView
 SG_ DEV_RearView_Resp_00_Data : 0|64@1+ (1.0,0.0) [0.0|18446744073709551615] ""  Vector__XXX

BO_ 2617199359 DEV_RearView_Resp_FF: 8 TopView
 SG_ DEV_RearView_Resp_FF_Data : 0|64@1+ (1.0,0.0) [0.0|18446744073709551615] ""  Vector__XXX

BO_ 2617070080 DEV_SCR_Resp_00: 8 SCR
 SG_ DEV_SCR_Resp_00_Data : 0|64@1+ (1.0,0.0) [0.0|18446744073709551615] ""  Vector__XXX

BO_ 2617070335 DEV_SCR_Resp_FF: 8 SCR
 SG_ DEV_SCR_Resp_FF_Data : 0|64@1+ (1.0,0.0) [0.0|18446744073709551615] ""  Vector__XXX

BO_ 2617041408 DEV_Soundaktor_Resp_00: 8 ISE
 SG_ DEV_Soundaktor_Resp_00_Data : 0|64@1+ (1.0,0.0) [0.0|18446744073709551615] ""  Vector__XXX

BO_ 2617041663 DEV_Soundaktor_Resp_FF: 8 ISE
 SG_ DEV_Soundaktor_Resp_FF_Data : 0|64@1+ (1.0,0.0) [0.0|18446744073709551615] ""  Vector__XXX

BO_ 2617201152 DEV_STH_Resp_00: 8 STH_MLBevo
 SG_ DEV_STH_Resp_00_Data : 0|64@1+ (1.0,0.0) [0.0|18446744073709551615] ""  Vector__XXX

BO_ 2617201407 DEV_STH_Resp_FF: 8 STH_MLBevo
 SG_ DEV_STH_Resp_FF_Data : 0|64@1+ (1.0,0.0) [0.0|18446744073709551615] ""  Vector__XXX

BO_ 2617004800 DEV_SWA_2_Resp_00: 8 MRR_HL
 SG_ DEV_SWA_2_Resp_00_Data : 0|64@1+ (1.0,0.0) [0.0|18446744073709551615] ""  Vector__XXX

BO_ 2617005055 DEV_SWA_2_Resp_FF: 8 MRR_HL
 SG_ DEV_SWA_2_Resp_FF_Data : 0|64@1+ (1.0,0.0) [0.0|18446744073709551615] ""  Vector__XXX

BO_ 2617143808 DEV_SWA_Resp_00: 8 MRR_HR
 SG_ DEV_SWA_Resp_00_Data : 0|64@1+ (1.0,0.0) [0.0|18446744073709551615] ""  Vector__XXX

BO_ 2617144063 DEV_SWA_Resp_FF: 8 MRR_HR
 SG_ DEV_SWA_Resp_FF_Data : 0|64@1+ (1.0,0.0) [0.0|18446744073709551615] ""  Vector__XXX

BO_ 1714 Diagnose_01: 8 Gateway
 SG_ DGN_Verlernzaehler : 0|8@1+ (1,0) [0|254] ""  AEM,E_Sound,FLA,ISE,MRR_HL,MRR_HR,NightVision,RDK,SAK,SAK2,SCR,STH_MLBevo,TopView
 SG_ KBI_Kilometerstand : 8|20@1+ (1,0) [0|1048573] "Unit_KiloMeter"  AEM,E_Sound,FBK,FLA,ISE,MRR_HL,MRR_HR,NightVision,RDK,SAK,SAK2,SCR,STH_MLBevo,TopView
 SG_ UH_Jahr : 28|7@1+ (1,2000) [2000|2127] "Unit_Year"  AEM,E_Sound,FBK,FLA,ISE,MRR_HL,MRR_HR,NightVision,RDK,SAK,SAK2,SCR,STH_MLBevo,TopView
 SG_ UH_Monat : 35|4@1+ (1,0) [1|12] "Unit_Month"  AEM,E_Sound,FBK,FLA,ISE,MRR_HL,MRR_HR,NightVision,RDK,SAK,SAK2,SCR,STH_MLBevo,TopView
 SG_ UH_Tag : 39|5@1+ (1,0) [1|31] "Unit_Day"  AEM,E_Sound,FBK,FLA,ISE,MRR_HL,MRR_HR,NightVision,RDK,SAK,SAK2,SCR,STH_MLBevo,TopView
 SG_ UH_Stunde : 44|5@1+ (1,0) [0|23] "Unit_Hours"  AEM,E_Sound,FBK,FLA,ISE,MRR_HL,MRR_HR,NightVision,RDK,SAK,SAK2,SCR,STH_MLBevo,TopView
 SG_ UH_Minute : 49|6@1+ (1,0) [0|59] "Unit_Minut"  AEM,E_Sound,FBK,FLA,ISE,MRR_HL,MRR_HR,NightVision,RDK,SAK,SAK2,SCR,STH_MLBevo,TopView
 SG_ UH_Sekunde : 55|6@1+ (1,0) [0|59] "Unit_Secon"  AEM,E_Sound,FBK,FLA,ISE,MRR_HL,MRR_HR,NightVision,RDK,SAK,SAK2,SCR,STH_MLBevo,TopView
 SG_ Kombi_02_alt : 62|1@1+ (1.0,0.0) [0.0|1] ""  Vector__XXX
 SG_ Uhrzeit_01_alt : 63|1@1+ (1.0,0.0) [0.0|1] ""  Vector__XXX

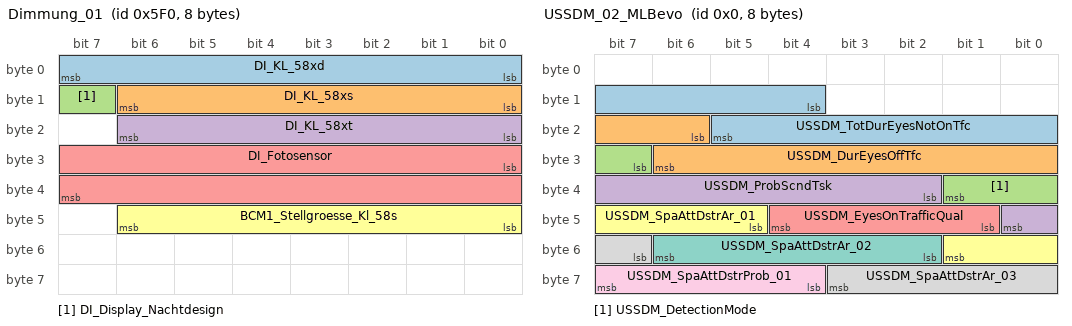
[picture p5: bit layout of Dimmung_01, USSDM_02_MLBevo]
BO_ 1520 Dimmung_01: 8 Gateway
 SG_ DI_KL_58xd : 0|8@1+ (1,0) [0|253] ""  FLA,TopView
 SG_ DI_KL_58xs : 8|7@1+ (1,0) [0|100] "Unit_PerCent"  Vector__XXX
 SG_ DI_Display_Nachtdesign : 15|1@1+ (1.0,0.0) [0.0|1] ""  Vector__XXX
 SG_ DI_KL_58xt : 16|7@1+ (1,0) [0|100] "Unit_PerCent"  Vector__XXX
 SG_ DI_Fotosensor : 24|16@1+ (1,0) [0|65535] ""  Vector__XXX
 SG_ BCM1_Stellgroesse_Kl_58s : 40|7@1+ (1,0) [0|100] ""  Vector__XXX

BO_ 0 USSDM_01_MLBevo: 8 FBK
 SG_ USSDM_FakeDetected : 12|1@1+ (1.0,0.0) [0.0|1] ""  Vector__XXX
 SG_ USSDM_EyesClosed : 13|2@1+ (1.0,0.0) [0.0|3] ""  Vector__XXX
 SG_ USSDM_EyesFound : 15|1@1+ (1.0,0.0) [0.0|1] ""  Vector__XXX
 SG_ USSDM_EyesOnRoad : 16|3@1+ (1.0,0.0) [0.0|7] ""  Vector__XXX
 SG_ USSDM_Microsleep : 19|3@1+ (1.0,0.0) [0.0|7] ""  Vector__XXX
 SG_ USSDM_MicrosleepQual : 22|4@1+ (10,0) [0|100] "Unit_PerCent"  Vector__XXX
 SG_ USSDM_HeadFound : 26|1@1+ (1.0,0.0) [0.0|1] ""  Vector__XXX
 SG_ USSDM_HeadBasedMirrorSelection : 27|2@1+ (1.0,0.0) [0.0|3] ""  Vector__XXX
 SG_ USSDM_EyesOffRoadTime : 29|9@1+ (0.1,0) [0.0|50.8] "Unit_Secon"  Vector__XXX
 SG_ USSDM_EyesOnRoadQual : 38|4@1+ (10,0) [0|100] "Unit_PerCent"  Vector__XXX
 SG_ USSDM_CalibrationStatus : 42|3@1+ (1.0,0.0) [0.0|7] ""  Vector__XXX
 SG_ USSDM_DriverPresence : 45|3@1+ (1.0,0.0) [0.0|7] ""  Vector__XXX
 SG_ USSDM_Status : 48|3@1+ (1.0,0.0) [0.0|7] ""  Vector__XXX
 SG_ USSDM_EyesOpen : 51|2@1+ (1.0,0.0) [0.0|3] ""  Vector__XXX
 SG_ USSDM_VisualDistractionQual : 53|4@1+ (10,0) [0|100] "Unit_PerCent"  Vector__XXX
 SG_ USSDM_VisualDistractionLevel : 57|3@1+ (1.0,0.0) [0.0|7] ""  Vector__XXX
 SG_ USSDM_Blindness : 60|3@1+ (1.0,0.0) [0.0|7] ""  Vector__XXX

BO_ 0 USSDM_02_MLBevo: 8 FBK
 SG_ USSDM_TotDurEyesNotOnTfc : 12|10@1+ (0.1,0) [0.0|102.0] "Unit_Secon"  Vector__XXX
 SG_ USSDM_DurEyesOffTfc : 22|9@1+ (0.1,0) [0.0|50.7] "Unit_Secon"  Vector__XXX
 SG_ USSDM_DetectionMode : 31|3@1+ (1.0,0.0) [0.0|7] ""  Vector__XXX
 SG_ USSDM_ProbScndTsk : 34|7@1+ (1,0) [0|100] "Unit_PerCent"  Vector__XXX
 SG_ USSDM_EyesOnTrafficQual : 41|4@1+ (10,0) [0|100] "Unit_PerCent"  Vector__XXX
 SG_ USSDM_SpaAttDstrAr_01 : 45|5@1+ (1.0,0.0) [0.0|31] ""  Vector__XXX
 SG_ USSDM_SpaAttDstrAr_02 : 50|5@1+ (1.0,0.0) [0.0|31] ""  Vector__XXX
 SG_ USSDM_SpaAttDstrAr_03 : 55|5@1+ (1.0,0.0) [0.0|31] ""  Vector__XXX
 SG_ USSDM_SpaAttDstrProb_01 : 60|4@1+ (10,0) [0|100] "Unit_PerCent"  Vector__XXX

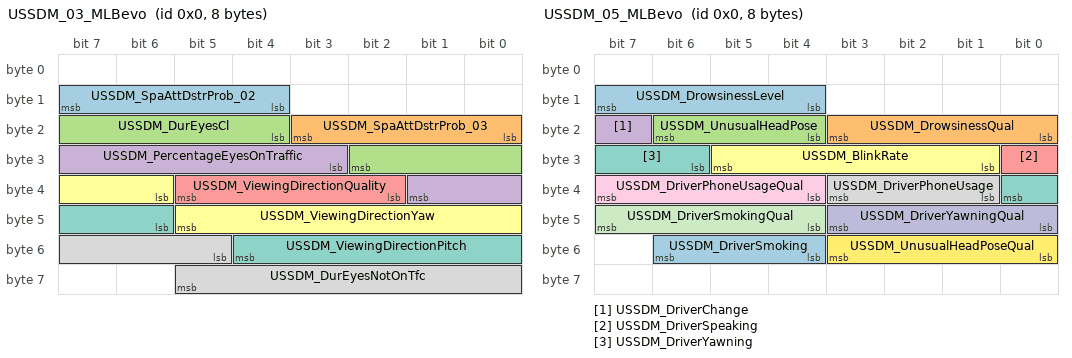
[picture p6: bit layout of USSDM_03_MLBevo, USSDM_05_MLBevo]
BO_ 0 USSDM_03_MLBevo: 8 FBK
 SG_ USSDM_SpaAttDstrProb_02 : 12|4@1+ (10,0) [0|100] "Unit_PerCent"  Vector__XXX
 SG_ USSDM_SpaAttDstrProb_03 : 16|4@1+ (10,0) [0|100] "Unit_PerCent"  Vector__XXX
 SG_ USSDM_DurEyesCl : 20|7@1+ (0.1,0) [0.0|12.3] "Unit_Secon"  Vector__XXX
 SG_ USSDM_PercentageEyesOnTraffic : 27|7@1+ (1,0) [0|100] "Unit_PerCent"  Vector__XXX
 SG_ USSDM_ViewingDirectionQuality : 34|4@1+ (10,0) [0|100] "Unit_PerCent"  Vector__XXX
 SG_ USSDM_ViewingDirectionYaw : 38|8@1+ (1,-120) [-120|120] "Unit_DegreOfArc"  Vector__XXX
 SG_ USSDM_ViewingDirectionPitch : 46|7@1+ (1,-60) [-60|60] "Unit_DegreOfArc"  Vector__XXX
 SG_ USSDM_DurEyesNotOnTfc : 53|9@1+ (0.1,0) [0.0|50.7] "Unit_Secon"  Vector__XXX

BO_ 0 USSDM_05_MLBevo: 8 FBK
 SG_ USSDM_DrowsinessLevel : 12|4@1+ (1.0,0.0) [0.0|15] ""  Vector__XXX
 SG_ USSDM_DrowsinessQual : 16|4@1+ (10,0) [0|100] "Unit_PerCent"  Vector__XXX
 SG_ USSDM_UnusualHeadPose : 20|3@1+ (1.0,0.0) [0.0|7] ""  Vector__XXX
 SG_ USSDM_DriverChange : 23|1@1+ (1.0,0.0) [0.0|1] ""  Vector__XXX
 SG_ USSDM_DriverSpeaking : 24|1@1+ (1.0,0.0) [0.0|1] ""  Vector__XXX
 SG_ USSDM_BlinkRate : 25|5@1+ (1,0) [0|27] "Unit_None"  Vector__XXX
 SG_ USSDM_DriverYawning : 30|3@1+ (1.0,0.0) [0.0|7] ""  Vector__XXX
 SG_ USSDM_DriverPhoneUsage : 33|3@1+ (1.0,0.0) [0.0|7] ""  Vector__XXX
 SG_ USSDM_DriverPhoneUsageQual : 36|4@1+ (10,0) [0|100] "Unit_PerCent"  Vector__XXX
 SG_ USSDM_DriverYawningQual : 40|4@1+ (10,0) [0|100] "Unit_PerCent"  Vector__XXX
 SG_ USSDM_DriverSmokingQual : 44|4@1+ (10,0) [0|100] "Unit_PerCent"  Vector__XXX
 SG_ USSDM_UnusualHeadPoseQual : 48|4@1+ (10,0) [0|100] "Unit_PerCent"  Vector__XXX
 SG_ USSDM_DriverSmoking : 52|3@1+ (1.0,0.0) [0.0|7] ""  Vector__XXX

BO_TX_BU_ 0 :Gateway,Gateway_PAG;
BO_TX_BU_ 1660 :E_Sound,SAK2;
BO_TX_BU_ 64 :Gateway,Gateway_PAG;
BO_TX_BU_ 1312 :Gateway,Gateway_PAG;
BO_TX_BU_ 1349 :Gateway,Gateway_PAG;
BO_TX_BU_ 326 :Gateway,Gateway_PAG;
BO_TX_BU_ 1633 :Gateway,Gateway_PAG;
BO_TX_BU_ 345 :Gateway,Gateway_PAG;
BO_TX_BU_ 1013 :Gateway,Gateway_PAG;
BO_TX_BU_ 2536767280 :E_Sound,Gateway,Gateway_PAG,MRR_HR,NightVision,RDK,TopView;
BO_TX_BU_ 2536708096 :Gateway,Gateway_PAG;
BO_TX_BU_ 2536708097 :Gateway,Gateway_PAG;
BO_TX_BU_ 2536704528 :Gateway,Gateway_PAG;
BO_TX_BU_ 2536704529 :Gateway,Gateway_PAG;
BO_TX_BU_ 2536703744 :Gateway,Gateway_PAG;
BO_TX_BU_ 2536703745 :Gateway,Gateway_PAG;
BO_TX_BU_ 2536703746 :Gateway,Gateway_PAG;
BO_TX_BU_ 2536704768 :Gateway,Gateway_PAG;
BO_TX_BU_ 2536728064 :Gateway,Gateway_PAG;
BO_TX_BU_ 2536719360 :Gateway,Gateway_PAG;
BO_TX_BU_ 2536708608 :Gateway,Gateway_PAG;
BO_TX_BU_ 2536708609 :Gateway,Gateway_PAG;
BO_TX_BU_ 1626 :Gateway,Gateway_PAG;
BO_TX_BU_ 2527679637 :Gateway,Gateway_PAG;
BO_TX_BU_ 961 :Gateway,Gateway_PAG;
BO_TX_BU_ 1432 :Gateway,Gateway_PAG;
BO_TX_BU_ 2617189889 :E_Sound,SAK2;
BO_TX_BU_ 2617042433 :ISE,SAK;
BO_TX_BU_ 901 :Gateway,Gateway_PAG;
BO_TX_BU_ 1000 :Gateway,Gateway_PAG;
BO_TX_BU_ 2617188864 :E_Sound,SAK2;
BO_TX_BU_ 2617189119 :E_Sound,SAK2;
BO_TX_BU_ 2617041408 :ISE,SAK;
BO_TX_BU_ 2617041663 :ISE,SAK;
BO_TX_BU_ 1714 :Gateway,Gateway_PAG;
BO_TX_BU_ 1520 :Gateway,Gateway_PAG;

CM_ "MLBevo_ECAN_V8.24.00F Generated by BusNet_NG_Produktiv 9.24.4";
CM_ BU_ AEM "Activ Engine Mount (aktive Motorenlagerung) im MLBevo

Lietz, Thomas (I/AEV-1, extern)	+49-8458-39730071";
CM_ BU_ E_Sound "AktiveSoundAbgasanlage";
CM_ BU_ FLA "MLBEvo";
CM_ BU_ Gateway "MLBevo Diagnoseinterface für Datenbus

connected Gateway Version 2.0, Zulieferer Conti Markdorf
- e & e4

connected Gateway Version 3.1, Zulieferer ESR/Lear
- e, e2, e5, e6";
CM_ BU_ Gateway_PAG "Gateway-Variante für PAG - Absprungbasis Gateway 3.x";
CM_ BU_ ISE "ISE - Innen Sound Elektrisch";
CM_ BU_ MRR_HL "Mid Range Radar hinten links Slave";
CM_ BU_ MRR_HR "Mid Range Radar hinten rechts Master";
CM_ BU_ NightVision "MLBevo
Rosenow, Andrej (I/EE-32) +49-841-89-42281";
CM_ BU_ RDK "MLBevo";
CM_ BU_ SAK "Soundaktor (Innensound)";
CM_ BU_ SAK2 "AktiveSoundAbgasanlage (Aussensound)";
CM_ BU_ SCR "Reduktionsmittel Dosiersystem (Harnstoff) MLBevo
SelectivCatalyticReduction

Bock Dietrich I/EF-61 40838 ";
CM_ BU_ STH_MLBevo "Standheizung im MLBevo";
CM_ BU_ TopView "MLBevo";

CM_ BO_ 1660 "MLBevo";
CM_ BO_ 1633 "ab MQB 7.2";
CM_ BO_ 901 "ab MQB ohne CHK und mit geänderter Sendeart";
CM_ BO_ 1520 "ab MQB nach abgestimmten FLH Dimmung";

CM_ SG_ null AB_GSCH_Reihe1_BF "Gurtschlossstatus Reihe 1 Beifahrer";
CM_ SG_ null AB_GSCH_Reihe1_FA "Gurtschlossstatus Reihe 1 Fahrer";
CM_ SG_ null AB_Sg_Status_02_CompID "Komplement-ID";
CM_ SG_ null BT_Tuer_Status "Türstatus mit Fehler und Initwert";
CM_ SG_ null FT_Tuer_Status "Tür geöffnet oder Tür geschlossen";
CM_ SG_ null VDSO_Vx3d "Geschwindigkeitssignal vom ABS/ASR oder ESP. Mittelwert der angetriebenen Räder.
Bei MSR oder ABS Eingriffen wird die ABS-Referenzgeschwindigkeit für >= 200ms eingespiegelt (Zeit wird mit Aktiv-Flanke der Funktionsbits getriggert)

MQB: Bei Frontantrie";

CM_ SG_ 1469 AEM_Status_Regelung "Betriebsstatus des Regler";

CM_ SG_ 1660 AGA_01_CRC "Für MLB:
'Berechnung siehe Lastenheft 'Kommunikationsabsicherung für FlexRay und CAN''

Ab MQB und MLBevo:
'Berechnung siehe Lastenheft 'End-to-End Kommunikationsabsicherung''

Endwerte siehe Begleitdokument 'S-PDU Kennungsfolgen'";
CM_ SG_ 1660 AGA_Charisma_FahrPr "MLBevo: Aktuelles Fahrprogramm des Charisma-Teilnehmers (siehe Systemlastenheft Drive Select)
MQB: Istwert der Kennlinie (siehe Systemlastenheft MQB FPA)";
CM_ SG_ 1660 AGA_Charisma_Status "Rückmeldung an den Charisma-Master

Wert 0x3 ist nur für Fahrzeuge ab MQB relevant";
CM_ SG_ 1660 AGA_Verstaerker_Mute "Freischaltung Verstaerkerkanal";
CM_ SG_ 1660 E_Sound_Mute_Icon "Abbildung der E-Sound Mute Funktion im Kombi als Icon";
CM_ SG_ 1660 E_Sound_Mute_LED "LED zur Anzeige, ob E-Sound stumm geschaltet ist.";
CM_ SG_ 1660 E_Sound_ohne_Funktion "Zeigt den Ausfall e_sound SG an";
CM_ SG_ 1660 E_Sound_Texte "Auswahl der Fehleranzeigetexte in Kombi";
CM_ SG_ 1660 E_Sound_verbaut "Signal dient zur Unterscheidung der beiden SGs 'aktive AGA' und 'e-sound' durch das Kombii. Beide SGs nutzen identische Signale und gleiche Diagnoseadresse.";

CM_ SG_ 64 AB_Anzeige_Fussg "Anzeige für ausgelöste Fussgängerschutz-Aktuatorik";
CM_ SG_ 64 AB_Belegung_VF "Belegungserkennung vorne Fahrer.";
CM_ SG_ 64 AB_Crash_Int "Crash_Intensität_1 = fahrzeugabhängige Reaktionen im Crash
Crash_Intensität_2 = fahrzeugabhängige Reaktionen im Crash
Crash_Intensität_3 = fahrzeugabhängige Reaktionen im Crash

Die jeweiligen fahrzeugabhängigen Reaktionen im Crash sind in einem separ";
CM_ SG_ 64 AB_Deaktiviert "Airbag oder Gurtstraffer wurden per Anpassung deaktiviert: Aktualisierung erst nach Selbsttest";
CM_ SG_ 64 AB_Deaktivierung_HV "Deaktivierung des HV-Systems und der HV-Teilnehmer im Crash (u.a. Hybrid- und Elektrofahrzeuge)";
CM_ SG_ 64 AB_Diagnose "Airbag in Diagnose";
CM_ SG_ 64 AB_EDR_Trigger "Triggerbedingung zur dezentralen Aufzeichnung unfallrelevanter Daten im Event Data Recorder";
CM_ SG_ 64 AB_Erh_Auf_VB "Der Fahrer soll bei einem Statuswechsel des Beifahrerairbags (ausgelöst durch die Beifahrerinsassenerkennung oder den Schlüsselschloßschalter) aufmerksam gemacht werden durch eine Anzeige im Kombi. Nur Audi: gültig für: AB2 (4-Türer AU352), B7, C6, D3";
CM_ SG_ 64 AB_Front_Crash "Bit wird bei Überschreitung der Gurtstraffer-, US- und RdW-Schwelle gesetzt";
CM_ SG_ 64 AB_Gurtwarn_VB "Beifahrer hat Gurt nicht gesteckt, Anzeige im Kombi";
CM_ SG_ 64 AB_Gurtwarn_VF "Fahrer hat Gurt nicht gesteckt, Anzeige im Kombi";
CM_ SG_ 64 AB_Heck_Crash "Wird für alle neu anlaufenden Projekte umgesetzt: AB8.4, Audi8/VW8";
CM_ SG_ 64 AB_Lampe "Sicherheitswarnlampe im Kombi wird vom Airbag-SG angesteuert; Zustand der Lampe wird auf dem CAN-Bus ausgegeben (auch Blinkinformation).";
CM_ SG_ 64 AB_MKB_Anforderung "Anforderung Multi-Kollisions-Bremsung";
CM_ SG_ 64 AB_MKB_gueltig "Multi-Kollisions-Bremsung im Airbag freigeschaltet";
CM_ SG_ 64 AB_RGS_Anst "PreCrash-Ansteuerung reversibler Gurtstraffer (Aktivierung und Kraftniveau)

10xx = deaktiviert";
CM_ SG_ 64 AB_Rollover_Crash "Wird im B6/B7 Cabrio und New Beetle Cabrio bedient. ";
CM_ SG_ 64 AB_SB_Crash "Z.Zt. nur in Verbindung mit Crash-Intensität >= 100b (Kraftstoffpumpenabschaltung) verwendet.
";
CM_ SG_ 64 AB_SF_Crash "Z.Zt. nur in Verbindung mit Crash-Intensität >= 100b (Kraftstoffpumpenabschaltung) verwendet.";
CM_ SG_ 64 AB_Stellgliedtest "Information, ob Airbag im Stellgliedtest ist, um eine Notrufauflösung beim Stellgliedtest zu verhindern";
CM_ SG_ 64 AB_Systemfehler "Systemfehler Ggf. wird Warnlampe dauernd eingeschaltet.";
CM_ SG_ 64 AB_Texte_AKS "Textanzeige für pyrotechnische Auslösung der aktiven Kopfstütze (AKS)";
CM_ SG_ 64 AB_VB_deaktiviert "Als Option vorgehalten, Beifahrerairbag wurden per Schlüsselschalter oder Insassenerkennung deaktiviert";
CM_ SG_ 64 AB_Versorgungsspannung "Übertragung der Plausibilitätsinformation Kl.15-Last vs. Kl.15-CAN.
Bedienung im Fall Kl.15-Last 'EIN' und Kl.15-CAN 'AUS' mit Ausgabe Warnung/Akustik im Kombi.";
CM_ SG_ 64 Airbag_01_CRC "Für MLB:
'Berechnung siehe Lastenheft 'Kommunikationsabsicherung für FlexRay und CAN''

Ab MQB und MLBevo:
'Berechnung siehe Lastenheft 'End-to-End Kommunikationsabsicherung''

Endwerte siehe Begleitdokument 'S-PDU Kennungsfolgen'";
CM_ SG_ 64 SC_LowSpeedCrashErkannt "Crash erkannt bei niedriger Geschwindigkeit";
CM_ SG_ 64 SC_Masterzeit "Masterzeit für alle Objektlisten";
CM_ SG_ 64 SC_Masterzeit_Offset "Erweiterung des Signals SC_Masterzeit um zwei höherwertige Bits, so dass ein Zeitbereich von ~20s (statt 5s) abgedeckt werden kann. Der aus SC_Masterzeit_Offset und SC_Masterzeit zu bildende Zeitstempel wird für die Synchronisation von Ereignissen der Fun";

CM_ SG_ 1312 AB_Abschaltanf_SIH_BF "Die Insassenerkennung auf der Beifahrerseite fordert bei Übertemperatur eine Abschaltung der Sitzheizung an. Die Übertemperatur kann bei niederohmigen Nebenschlüssen der Sitzheizungsmatte als Folge von zu hohem resultierenden Strom auftreten.";
CM_ SG_ 1312 AB_Anforderung_eCall "Trigger für Car2X Steuergerät das ein eCall Ereignis erkannt wurde.";
CM_ SG_ 1312 AB_Anforderung_USM "Trigger für Gateway (OBDC) und MIB/MMI, dass ein USM-Ereignis erkannt wurde.";
CM_ SG_ 1312 AB_Anprall_FGS "Uebermittlung der Lage einer Kollision, Fussgaengerschutz-Aktorik";
CM_ SG_ 1312 AB_Anprall_Front_Beifahrer "Uebermittlung der Lage einer Kollision, Anprallzone Front Beifahrerseite";
CM_ SG_ 1312 AB_Anprall_Front_Fahrer "Uebermittlung der Lage einer Kollision, Anprallzone Front Fahrerseite";
CM_ SG_ 1312 AB_Anprall_Heck_Beifahrer "Uebermittlung der Lage einer Kollision, Anprallzone Beifahrerseite hinten";
CM_ SG_ 1312 AB_Anprall_Heck_Fahrer "Uebermittlung der Lage einer Kollision, Anprallzone Fahrerseite hinten";
CM_ SG_ 1312 AB_Anprall_Rollover "Uebermittlung der Lage einer Kollision, Rollover erkannt";
CM_ SG_ 1312 AB_Anprall_Seite_Beifahrer "Uebermittlung der Lage einer Kollision, Anprallzone Beifahrerseite Seite";
CM_ SG_ 1312 AB_Anprall_Seite_Fahrer "Uebermittlung der Lage einer Kollision, Anprallzone Fahrerseite Seite";
CM_ SG_ 1312 AB_Belegung_VB "Belegungserkennung vorne Beifahrer. Wird in US-Steuergeräten über Bladder-Matte bedient, optional bei RdW, falls SBE_EuroNCAP entschieden wird.";
CM_ SG_ 1312 AB_Crashschwere "Übermittlung der Crashschwere an das Gateway (OBDC)";
CM_ SG_ 1312 AB_Gurtschloss_BF "Gurtschlossstatus Beifahrerseite";
CM_ SG_ 1312 AB_Gurtschloss_FA "Gurtschlosstatatus Fahrerseite";
CM_ SG_ 1312 AB_Gurtschloss_Reihe2_BF "Gurtschlossstatus 2. Reihe Beifahrerseite,  Mehrausstattung";
CM_ SG_ 1312 AB_Gurtschloss_Reihe2_FA "Gurtschlossstatus 2. Reihe Fahrerseite, Mehrausstattung";
CM_ SG_ 1312 AB_Gurtschloss_Reihe2_MI "Gurtschlossstatus 2. Reihe Mitte,  Mehrausstattung";
CM_ SG_ 1312 AB_Gurtschloss_Reihe3_BF "Gurtschlossstatus 3. Reihe Beifahrerseite,  Mehrausstattung";
CM_ SG_ 1312 AB_Gurtschloss_Reihe3_FA "Gurtschlossstatus 3. Reihe Fahrerseite,  Mehrausstattung";
CM_ SG_ 1312 AB_Gurtschloss_Reihe3_MI "Gurtschlossstatus 3. Reihe Mitte,  Mehrausstattung";
CM_ SG_ 1312 AB_Sitzpos_Sens_BF "Ausgabe Sitzposition Beifahrer";
CM_ SG_ 1312 AB_Sitzpos_Sens_FA "Ausgabe Sitzposition Fahrer";
CM_ SG_ 1312 AB_Wickelklappung_Reihe2_BF "Status Wickelklappung 2. Reihe Beifahrerseite, Mehrausstattung";
CM_ SG_ 1312 AB_Wickelklappung_Reihe2_FA "Status Wickelklappung 2. Reihe Fahrerseite, Mehrausstattung";
CM_ SG_ 1312 AB_Wickelklappung_Reihe2_MI "Status Wickelklappung 2. Reihe Mitte, Mehrausstattung";
CM_ SG_ 1312 Airbag_02_CRC "Für MLB:
'Berechnung siehe Lastenheft 'Kommunikationsabsicherung für FlexRay und CAN''

Ab MQB und MLBevo:
'Berechnung siehe Lastenheft 'End-to-End Kommunikationsabsicherung''

Endwerte siehe Begleitdokument 'S-PDU Kennungsfolgen'";
CM_ SG_ 1312 LoGeWa_Event_Kombiwarnung "Event für Kombiwarnung";
CM_ SG_ 1312 SC_PAO_OFF_Anf "Sollwert für LED 'OFF' in Anzeige Passenger Airbag On/Off";
CM_ SG_ 1312 SC_PAO_ON_Anf "Sollwert für LED 'ON' in Anzeige Passenger Airbag On/Off";
CM_ SG_ 1312 SC_PAO_Schriftzug_Anf "Sollwert für LED 'PASSENGER AIRBAG' in Anzeige Passenger Airbag On/Off";

CM_ SG_ 1349 AB_Gurtwarn_Reihe2_BF "Status Gurtwarnung 2. Sitzreihe Beifahrerseite";
CM_ SG_ 1349 AB_Gurtwarn_Reihe2_FA "Status Gurtwarnung 2. Sitzreihe Fahrerseite";
CM_ SG_ 1349 AB_Gurtwarn_Reihe2_MI "Status Gurtwarnung 2. Sitzreihe Mitte";
CM_ SG_ 1349 AB_Gurtwarn_Reihe3_BF "Status Gurtwarnung 3. Sitzreihe Beifahrerseite";
CM_ SG_ 1349 AB_Gurtwarn_Reihe3_FA "Status Gurtwarnung 3. Sitzreihe Fahrerseite";
CM_ SG_ 1349 AB_Gurtwarn_Reihe3_MI "Status Gurtwarnung 3. Sitzreihe Mitte";
CM_ SG_ 1349 AB_SBR_hinten_verbau "Verbauinformation Sitzbelegungssensor hinten (2. und 3. Sitzreihe)";
CM_ SG_ 1349 AbstWarn_MV_FAS_Fkt_Status "FAS-ProfileMaster Iststatus der Kundenfunktion";
CM_ SG_ 1349 AWV_Einstellung_System_ASG "Signal zur Realisierung des BAP-Koordinators";
CM_ SG_ 1349 AWV_Einstellung_Warnung_ASG "Signal zur Realisierung des BAP-Koordinators";
CM_ SG_ 1349 LGI_FAS_Fkt_Status "FAS-ProfileMaster Iststatus der Kundenfunktion (LGI: Lokale Gefahreninformation)";
CM_ SG_ 1349 PreCrash_FAS_Fkt_Status "FAS-ProfileMaster Iststatus der Kundenfunktion";
CM_ SG_ 1349 SC_PreSense_Modus_System_KAS "BAP-Kommunikation zum Kreuzungsassistent";
CM_ SG_ 1349 SC_PreSense_Modus_System_MV "Signal zur Realisierung der BAP-Kommunikation für PreSense";
CM_ SG_ 1349 SC_PreSense_Modus_System_NV "Signal zur Realisierung der BAP-Kommunikation für PreSense";
CM_ SG_ 1349 SC_PreSense_Modus_Warnung_MV "Signal zur Realisierung der BAP-Kommunikation für PreSense";
CM_ SG_ 1349 SC_PreSense_Modus_Warnung_NV "Signal zur Realisierung der BAP-Kommunikation für PreSense";
CM_ SG_ 1349 WarnBrems_Charisma_FahrPr "Aktuell eingestelltes Fahrprogramm der Funktion Warn- und/oder Notbremsfunktion";
CM_ SG_ 1349 WarnBrems_Charisma_Status "Verfügbarkeit der Funktion Warn- und/oder Notbremsfunktion für die Ansteuerung durch den Charisma-Koordinator.";

CM_ SG_ 326 Airbag_05_BZ "4bit Botschaftszähler, wird mit jeder Sendebotschaft inkrementiert";
CM_ SG_ 326 Airbag_05_CRC "Für MLB:
Berechnung siehe Lastenheft 'Kommunikationsabsicherung für FlexRay und CAN'
Ab MQB und MLBevo:
Berechnung siehe Lastenheft 'End-to-End Kommunikationsabsicherung'

Endwerte siehe Begleitdokument 'S-PDU Kennungsfolgen'";
CM_ SG_ 326 SC_FASIS_SyncCounter "Masterzeit für alle Objektlisten";
CM_ SG_ 326 SC_QBit_FASIS_SyncCounter "QBit für SC_FASIS_SyncCounter";

CM_ SG_ 1633 AAG_Anhaenger_abgesteckt "Anhaenger wurde bei Kl. 15 aus abgesteckt";
CM_ SG_ 1633 AAG_Anhaenger_erkannt "Erkennung Anhaenger ";
CM_ SG_ 1633 AAG_AVS_Fehler_02 "Fehler AVS";
CM_ SG_ 1633 AAG_AVS_Fehler_02_inv "Fehler AVS (inverses Signal)";
CM_ SG_ 1633 AAG_AVS_Stati "Status AVS (bei abnehmbarer oder mech.schwenkbarer Anhängerkupplung ist der Status immer 0)";
CM_ SG_ 1633 AAG_Blinker_H_aktiv "Status: Anhaenger Blinker aktiv";
CM_ SG_ 1633 AAG_Blinker_HL_def "Anhaenger Blinker links defekt";
CM_ SG_ 1633 AAG_Blinker_HR_def "Anhaenger Blinker rechts defekt";
CM_ SG_ 1633 AAG_Bremsl_durch_ECD "Bremslicht durch ECD aktiv";
CM_ SG_ 1633 AAG_Bremslicht_H_def "Anhaenger Bremslicht defekt";
CM_ SG_ 1633 AAG_Bremslicht_Reku "AAG_Bremslicht_Reku meldet zyklisch den empfangenen Zustand des CAN-Signals MO_Bremslicht_Reku zurück.";
CM_ SG_ 1633 AAG_BZ "4bit-Botschaftszaehler, wird in jeder Sendebotschaft inkrementiert

";
CM_ SG_ 1633 AAG_LED_aktiv "Dieses Signal sendet der Beleuchtungsart des Anhängers (LED oder Lampe)
Bei LED aktiv erfolgt kein Kaltüberwachung";
CM_ SG_ 1633 AAG_NSL_aktiv "Anhaenger Nebelschlusslicht aktiv";
CM_ SG_ 1633 AAG_Schlusslicht_HL_def "Anhaenger Schlußlicht links defekt";
CM_ SG_ 1633 AAG_Schlusslicht_HR_def "Anhaenger Schlußlicht rechts defekt";

CM_ SG_ 348 ARA_Sensor_02_red_cyclic "Zeigt die reduzierte Zykluszeit der CAN-Botschaft 'ARA_Sensor_02' von 100ms gegenüber 20ms an.";
CM_ SG_ 348 ARA_Sensor_dt_Botschaft "time span between actual image and signal sending time";
CM_ SG_ 348 ARA_Sensor_Knickw_Rohwert_BV "Rohwert Anhängerknickwinkel am Kugelkopf";
CM_ SG_ 348 ARA_Sensor_Qualitaet_Grund "cause of bad quality value";
CM_ SG_ 348 ARA_Sensor_Qualitaet_Wert "comparative quality value of image and trailer angle detection";
CM_ SG_ 348 ARA_Sensor_Status "ARA_Sensor status";
CM_ SG_ 348 ARA_Sensor_Zeitstempel_BV "timestamp of actual image processing";

CM_ SG_ 345 ARA_Aktiver_Grafikmodus "Zeigt an  das eine Grafik für ARA aktiviert werden soll";
CM_ SG_ 345 ARA_Bremsfuss "Anforderung des Bremsfusssymbols im Kombi";
CM_ SG_ 345 ARA_Deaktivierung_sperren "Unterdrückt die Deaktivierung der ARA- Visualisierung";
CM_ SG_ 345 ARA_Knickwinkel_Ist "Gibt den aktuellen Knickwinkel zwischen Anhänger und Fahrzeug wieder";
CM_ SG_ 345 ARA_Knickwinkel_Komfort "Knickwinkelgrenze bis zu der, bei maximalem Lenkeinschlag, eine sofortige gerade Rückwärtsfahrt möglich ist.";
CM_ SG_ 345 ARA_Knickwinkel_Konfidenz "irregular trailer angle area value for HMI display";
CM_ SG_ 345 ARA_Knickwinkel_Max "Gibt den maximalen ausregelbaren Knickwinkel zwischen Anhänger und Fahrzeug wieder.";
CM_ SG_ 345 ARA_Knickwinkel_Soll "Vom Fahrer vorgegebener Knickwinkel.";
CM_ SG_ 345 ARA_Modus "Regelmodus ARA für Kombidarstellung";
CM_ SG_ 345 ARA_Modus_Anf "Anforderung des ARA-Modus im Türsteuergerät";
CM_ SG_ 345 ARA_Sensor_Aktivierung "activation  of ARA IP (image processing)";
CM_ SG_ 345 ARA_Status "Status of ARA Controller";
CM_ SG_ 345 ARA_Texte "Anforderung für Kombianzeigetexte und Akustik";

CM_ SG_ 1013 ARA_nachtr_Stopp_Anf "Dieses Signal dient dem Motor als Trigger, dass ein nachträglicher Motorstopp eingeleitet werden kann, wenn es die Bedingungen des StSt Koordinators zulassen.";
CM_ SG_ 1013 ARA_StartStopp_Info "Stopp-Freigabe und Start-Anforderung an den Start-Stopp-Koordinator";
CM_ SG_ 1013 ARA_Verw_Zeitstempel_BV "used timestamp";
CM_ SG_ 1013 ARA_Weg_abs "Zurückgelegte absolute Wegstrecke des Zugfahrzeugs. Läuft von 4095 auf 0 vorwärts bzw 0 auf 4095 rückwärts über. ";
CM_ SG_ 1013 ARA_Winkel_abs "Vom Regler gefilterter Absolutwinkel im Bogenmaß";
CM_ SG_ 1013 ARA_Winkel_logInnovation "Logarithmus der gefilterten, normalisierten Innovation (NIS) der Winkelschätzung";
CM_ SG_ 1013 ARA_Winkel_logVarianz "trailer angle variation";

CM_ SG_ 2536704768 BAP_RVC_ASG_01_Header "Datenkanal für BAP-Katalog RVC";

CM_ SG_ 2536728064 BAP_SoundControl2_ASG_01_Header "Anzeigesteuergerät für Soundcontrol (z.B. Ansteuerung Abgasklappe über Taster)";

CM_ SG_ 2536728080 BAP_SoundControl2_FSG_01_Header "Funktionssteuergerät für Soundcontrol (z.B. Ansteuerung Abgasklappen über Taster)";

CM_ SG_ 2536719360 BAP_SoundControl_ASG_01_Header "Anzeigesteuergerät für Soundcontrol (z.B. Ansteuerung Abgasklappe über Taster)";

CM_ SG_ 2536719376 BAP_SoundControl_FSG_01_Header "Funktionssteuergerät für Soundcontrol (z.B. Ansteuerung Abgasklappen über Taster)";

CM_ SG_ 1626 APS_Tongeber_defekt "Status APS-Tongeber zur HMI-Ansteuerng der RCTA-Funktion";
CM_ SG_ 1626 BCM1_AFS_Lampe "Ansteuerung der AFS-Fehlermeldung im Kombi";
CM_ SG_ 1626 BCM1_EasyEntry_Status "Status EasyEntry für Lenksäule (wird auch von IVB verwendet)";
CM_ SG_ 1626 BCM1_Fahrlicht_Hinweis "Signal zum Kombi um den Hinweis 'Bitte Fahrlicht einschalten' anzufordern";
CM_ SG_ 1626 BCM1_Hinweis_Lichtnachlauf "Signal dient der Anzeige eines aktiven Lichtnachlaufes beim automatischen Abschalten der Klemme S und Klemme 15. Der Lichtnachlauf wird gestartet, wenn die Klemme 15 bei aktivem Fahrlicht deaktiviert wird.";
CM_ SG_ 1626 BCM1_Kl_15_HW_erkannt "Erkennung Klemme 15 (Hardware) vom BCM1
";
CM_ SG_ 1626 BCM1_Kl_15_Sig_HW_erkannt "Erkennung Klemme 15 Signal (Hardware) vom BCM1";
CM_ SG_ 1626 BCM1_LDS_Stellung "Das Signal wird vom AFS / LWR Steuergerät empfangen und dient der Verifizierung der Lichtdrehschalterstellung. Intelligente Lichtfunktionen wie dyn. KL und gleitende Leuchtweite (GLW) nur bei LDS = 'AUTO'.";
CM_ SG_ 1626 BCM1_Lenksaeule_aktiv "Lenksaeulenverstellung aktiv";
CM_ SG_ 1626 BCM1_Licht_Warn "Lichtwarnung";
CM_ SG_ 1626 BCM1_Lichtwarn_Texte "Anforderung von Lichtwarnungen vom BCM1 zum Kombi
MLB: nur Werte 0..2";
CM_ SG_ 1626 BCM1_MH_Schalter "Motorhaubenkontakt";
CM_ SG_ 1626 BCM1_MH_WIV_Schalter "Bewerteter Motorhaubenkontakt fuer WIV";
CM_ SG_ 1626 BCM1_NV_Taster "BCM1_NV_Taster gibt an, ob der NightVision-Taster im Lichtdrehschalter-Modul aktuell betaetigt wird.";
CM_ SG_ 1626 BCM1_Reisemodus_Texte "Ansteuerung der Reisemodus-Texte im Kombi";
CM_ SG_ 1626 BCM1_Rueckfahrlicht_Schalter "Rückfahrlichtschalter
ab MQB/ MLBevo: Die Ganginformation wird unentprellt übertragen, im AT-Getriebe wird evtl. kurzzeitig der R-Gang angezeigt. Eine Entprellung muß im Empfänger erfolgen (typisch 400ms).";
CM_ SG_ 1626 BCM1_Schluesselsuche_Anf "Anforderung von BCM1 an BCM2:
Schlüsselpolling aktivieren

Nötig bei z.B. aktiviertem Annäherungslicht";
CM_ SG_ 1626 BCM1_St_SW_Diebstahl_links "Signal zur Anzeige, dass der linke Scheinwerfer gestohlen wurde";
CM_ SG_ 1626 BCM1_St_SW_Diebstahl_rechts "Signal zur Anzeige, dass der rechte Scheinwerfer gestohlen wurde";
CM_ SG_ 1626 BCM1_Valet_Parking_Taster "Valet Parking Taster ";
CM_ SG_ 1626 BCM1_Warnblink_Taster "Warnblinktaster";
CM_ SG_ 1626 BCM_Bremsbelag_Sensor "Sensorsignal der Stromschleife  für Bremsbelagverschleiß aktuell, entstört, unbewertet";
CM_ SG_ 1626 BCM_Bremsfluessigkeit_Sensor "Kontaktsignal des Sensorschalters für die Bremsflüssigkeitsreserve aktuell, entstört, unbewertet";
CM_ SG_ 1626 BCM_Eco_Charisma_Taste "Betätigung Taster ECO alias BlueKey oder Charisma";
CM_ SG_ 1626 BCM_HDF_betaetigt "Betätigung Taster für Heckdeckelfernentriegelung in Mittelkonsole";
CM_ SG_ 1626 BCM_Hybrid_StartStopp_Taste "Betaetigung Taster 'Hybrid' oder alternativ Taster 'Start/Stopp Deaktivierung', je nach Verbau";
CM_ SG_ 1626 BCM_Hybrid_StSt_Taste_Fehler "Fehlerflag, wenn Tasterdiagnose im BCM für den StSt-Taster anschlägt.";
CM_ SG_ 1626 BCM_Kuehlmittel_Sensor "Signal der Sensorelektroden für die Kühlmittelreserve aktuell, entstört, bewertet (OK/Mangel)";
CM_ SG_ 1626 BCM_Kuehlmittel_Sensor_02 "Signal der zweiten Sensorelektroden für die Kühlmittelreserve aktuell, entstört, bewertet (OK/Mangel)";
CM_ SG_ 1626 BCM_Offroad_Taste "Betätigung der Offroad-Taste";
CM_ SG_ 1626 BCM_Waschwasser_Sensor "Signal der Sensorelektroden für die Waschwasserreserve aktuell, entstört, bewertet (OK/Mangel)";
CM_ SG_ 1626 Gong_TFL_Umschaltung "Aktivierung / Deaktivierung des TFL per Affengriff wird mit einem Gong im Kombi quittiert.";
CM_ SG_ 1626 ISP_Dimmung_ASP_02 "Dimmwertvorgabe für Aussenspiegel
Es wird 1:1 die Spannung am Innenspiegel nach außen übertragen.";
CM_ SG_ 1626 UGDO_Function_01 "UGDO_Sender = LIN-Slave BCM1
bei Kl.15 AUS wird für 4s noch der letzte Wert gesendet, danach wird der Wert 7 (= Fehler gesendet)";

CM_ SG_ 2527679637 BCM_LTM_Allwetterl_Status "Allwetterlicht Status zur Anzeige im Allwetterlicht-PopUp";
CM_ SG_ 2527679637 BCM_LTM_Nebell_Status "Nebellicht Status zur Anzeige im Nebellicht-PopUp";
CM_ SG_ 2527679637 BCM_LTM_Nebelschluss_Status "Nebelschlusslicht Status zur Anzeige im Nebelschlusslicht-PopUp";
CM_ SG_ 2527679637 BCM_LTM_PopUp_Anf "Anforderung der entsprechenden Anzeige im Kombi bei Aussenlichtsteuerung über LTM (LichtTastenModul)";
CM_ SG_ 2527679637 BCM_LTM_PopUp_Inhalt "Definition Inhalt des PopUps zur Aussenlichtbedienung";
CM_ SG_ 2527679637 BCM_LTM_PopUp_Status "Auswahl der aktiven Aussenlichtfunktion im LTM PopUp";
CM_ SG_ 2527679637 BCM_LTM_PopUp_Texte "Anforderung Kombi-Texte bei Bedienung Aussenlicht über LTM (LichtTastenModul)";
CM_ SG_ 2527679637 CPD_Warnung "Ansteuerung einer Warnung im Kombi/ iID mit Ton oder ohne Ton durch die Fkt. ChildPresenceDetection";

CM_ SG_ 961 APS_LED_Status "Das Signal beschreibt den Zustand der APS LED für die Einparkhilfe, die im MLBevo vom BCM1 oder LIN Schalterleiste (BCM1 Slave) angesteuert wird.";
CM_ SG_ 961 APS_Taster "Das Signal beschreibt den Zustand der Taste, die im MLBevo vom BCM1 eingelesen wird.";
CM_ SG_ 961 AVH_LED_Status "Das Signal beschreibt den Zustand der AVH LED, die im MLBevo vom BCM1 oder LIN Schalterleiste (BCM1 Slave) angesteuert wird.
";
CM_ SG_ 961 AVH_Taster "Das Signal beschreibt den Zustand der AVH Taste, die im MLBevo vom BCM1 eingelesen wird.
";
CM_ SG_ 961 Display_Taster "Taster für Display Klappung";
CM_ SG_ 961 Drivesel_1_Taster "Taster 1 für Drive Select Betätigung";
CM_ SG_ 961 Drivesel_2_Taster "Taster 2 für Drive Select Betätigung";
CM_ SG_ 961 eCall_Taste "Status der eCall-Taste. 
(Emergency Call / SOS Hilferuf)";
CM_ SG_ 961 ESP_Off_Taster "Das Signal beschreibt den Zustand der ESP Taste, die im MLBevo vom BCM1 eingelesen wird.
";
CM_ SG_ 961 HDC_LED_Status "Das Signal beschreibt den Zustand der HDC LED, die im MLBevo vom BCM1 oder LIN Schalterleiste (BCM1 Slave) angesteuert wird.	";
CM_ SG_ 961 HDC_Taster "Das Signal beschreibt den Zustand der HDC Taste, die im MLBevo vom BCM1 eingelesen wird
0 = Taste nicht betätigt
1 = Taste entprellt betätigt
2 = Init oder Taste nicht verbaut
3 = Fehler";
CM_ SG_ 961 Heckrollo_2_Taster "Taster 2 für Heckrollo Betätigung";
CM_ SG_ 961 Heckrollo_Taster "Taster für Heckrollo Betätigung";
CM_ SG_ 961 LIM_bCall_Taster "Statusinformation des Service Call Tasters im Dachmodul";
CM_ SG_ 961 LIM_PAO_Alivesignal "Alive-Information zur Absicherung von Timeouterkennung bei Routing über mehrere Bussegmente";
CM_ SG_ 961 LIM_PAO_OFF_Status "Istwert für LED 'OFF' in Anzeige Passenger Airbag On/Off";
CM_ SG_ 961 LIM_PAO_ON_Status "Istwert für LED 'ON' in Anzeige Passenger Airbag On/Off";
CM_ SG_ 961 LIM_PAO_Schriftzug_Status "Istwert für LED 'PASSENGER AIRBAG' in Anzeige Passenger Airbag On/Off";
CM_ SG_ 961 LKS_Taster "Taste zum de-/aktivieren der Funktion LKS (Lane Keeping System)

0 - Taste nicht betätigt
1 - Taste betätigt
2 - INIT oder Taste nicht verbaut
3 - Fehler (Timeout, hängender Taster)";
CM_ SG_ 961 PLA_LED_Status "Das Signal beschreibt den Zustand der PLA LED, die im MLBevo vom BCM1 oder LIN Schalterleiste (BCM1 Slave) angesteuert wird.";
CM_ SG_ 961 PLA_Taster "Das Signal beschreibt den Zustand der PLA (Parklenkassisten) Taste, die im MLBevo vom BCM1 eingelesen wird.";
CM_ SG_ 961 PLA_Taster_Fehler_Roh "PLA Taster Fehlerstatus als ungefiltertes Signal für eine schnelle Fehlererkennung und Verarbeitung im IPA";
CM_ SG_ 961 Sideview_Taster "Taster für SIDEVIEW Betätigung";
CM_ SG_ 961 Spoiler_LED_Status "Status der Funktions LED SPOILER Ein/Ausfahren.";
CM_ SG_ 961 Spoiler_Taster "Taster für SPOILER Betätigung";
CM_ SG_ 961 SWA_Taster "SWA Taster vom BCM1 (quelle LDS)";

CM_ SG_ 1432 BCM1_eSound_Taster "Das Signal beschreibt den Zustand der eSound Taste, die im MLBevo vom BCM1 eingelesen wird
0 = Taste nicht betätigt
1 = Taste entprellt betätigt
2 = Init oder Taste nicht verbaut
3 = Fehler";
CM_ SG_ 1432 BCM1_NR_Ride_Height_Down_Taster "Tastersignal zum Absenken des Fahrzeugs bei höhenverstellbaren Fahrzeugen (Taster/Bedieneinheit an Schalterleiste 2  BCM1)
";
CM_ SG_ 1432 BCM1_NR_Ride_Height_Up_Taster "Tastersignal zum Anheben des Fahrzeugs bei höhenverstellbaren Fahrzeugen (Taster/Bedieneinheit an Schalterleiste 2  BCM1";
CM_ SG_ 1432 BCM_BFS_Fernsteuerung_aktiv "Fernsteuerung BFS aktiv";
CM_ SG_ 1432 BCM_BFS_Massage_Taster "Ansteuerungs-Signalisierung der Pneumatik-Funktionen";
CM_ SG_ 1432 BCM_BFS_Multif_Taster "Ansteuerungs-Signalisierung der Pneumatik-Funktionen";
CM_ SG_ 1432 BCM_BFS_Pneumatik_Verstellung "Ansteuerungs-Signalisierung der Pneumatik-Funktionen";
CM_ SG_ 1432 BCM_BFS_Programmwippe "Ansteuerungs-Signalisierung der Pneumatik-Funktionen";
CM_ SG_ 1432 BCM_FS_Massage_Taster "Ansteuerungs-Signalisierung der Pneumatik-Funktionen";
CM_ SG_ 1432 BCM_FS_Multif_Taster "Ansteuerungs-Signalisierung der Pneumatik-Funktionen";
CM_ SG_ 1432 BCM_FS_Pneumatik_Verstellung "Ansteuerungs-Signalisierung der Pneumatik-Funktionen";
CM_ SG_ 1432 BCM_FS_Programmwippe "Ansteuerungs-Signalisierung der Pneumatik-Funktionen";
CM_ SG_ 1432 BCM_Soundklappe_Taster "Status Soundklappe Taste";
CM_ SG_ 1432 E_Sound_LED_Status "Das Signal beschreibt den Zustand der eSound LED, die im MLBevo vom BCM1 oder LIN Schalterleiste (BCM1 Slave) angesteuert wird.";
CM_ SG_ 1432 LIM_S_Rollo_hi "Schalterfeld LIM für Sonnenrolle Schiebedach hinten";
CM_ SG_ 1432 LIM_S_Rollo_vo "Schalterfeld LIM für Sonnenrolle Schiebedach vorne";
CM_ SG_ 1432 LIM_S_SAD_hi "Schalterfeld LIM für SAD hinten";
CM_ SG_ 1432 LIM_S_SAD_Vo "Schalterfeld LIM für SAD vorne";
CM_ SG_ 1432 Pilot_Taster "Das Signal beschreibt den Zustand der Pilot Taste, die im MLBevo vom BCM1 eingelesen wird
0 = Taste nicht betätigt
1 = Taste entprellt betätigt
2 = Init oder Taste nicht verbaut
3 = Fehler";

CM_ SG_ 901 CHA_Fahrer_Umschaltung "Die manuelle Umschaltung durch den Fahrer soll signalisiert werden, um zu automatischen Umschaltungen (z.B. Retries) differenzieren zu können.";
CM_ SG_ 901 CHA_Fahrer_Umschaltung_BMA "Die manuelle Umschaltung der Betriebsmodusauswahl durch den Fahrer soll signalisiert werden, um zu automatischen Umschaltungen (z.B. Retries) differenzieren zu können.";
CM_ SG_ 901 CHA_Ziel_FahrPr_ACC "MQB
Anforderung Ziel-Fahrprogramm ACC";
CM_ SG_ 901 CHA_Ziel_FahrPr_AFS "Anforderung Ziel-Fahrprogramm AFS";
CM_ SG_ 901 CHA_Ziel_FahrPr_AGA "Anforderung Ziel-Fahrprogramm AGA/SAK2 (Aussensound)";
CM_ SG_ 901 CHA_Ziel_FahrPr_ALR "Anforderung Ziel-Fahrprogramm Allrad";
CM_ SG_ 901 CHA_Ziel_FahrPr_DR "Anforderung Ziel-Fahrprogramm Dämpfer";
CM_ SG_ 901 CHA_Ziel_FahrPr_EPS "Anforderung Ziel-Fahrprogramm Elektrische Lenkhilfe";
CM_ SG_ 901 CHA_Ziel_FahrPr_ESP "Anforderung Ziel-Fahrprogramm ESP";
CM_ SG_ 901 CHA_Ziel_FahrPr_Freilauf "Anforderung Ziel-Fahrprogramm Funktion Freilauf";
CM_ SG_ 901 CHA_Ziel_FahrPr_GE "Anforderung Ziel-Fahrprogramm Getriebe";
CM_ SG_ 901 CHA_Ziel_FahrPr_MO "Anforderung Ziel-Fahrprogramm Motor";
CM_ SG_ 901 CHA_Ziel_FahrPr_MO_BZS "Anforderung Zielfahrprogramm Motor-Betriebszusände";
CM_ SG_ 901 CHA_Ziel_FahrPr_MO_StSt "Anforderung Ziel-Fahrprogramm Funktion Motor Start-Stopp";
CM_ SG_ 901 CHA_Ziel_FahrPr_PreCrash "Anforderung Ziel-Fahrprogramm PreCrash";
CM_ SG_ 901 CHA_Ziel_FahrPr_SAK "Anforderung Ziel-Fahrprogramm Soundaktuator";
CM_ SG_ 901 CHA_Ziel_FahrPr_VAQ "Anforderung Ziel-Fahrprogramm VAQ";

CM_ SG_ 1000 CHA_Fahrer_Umschaltung "Die manuelle Umschaltung durch den Fahrer soll signalisiert werden, um zu automatischen Umschaltungen (z.B. Retries) differenzieren zu können.";
CM_ SG_ 1000 CHA_Ziel_FahrPr_AFR "Anforderung Ziel-Fahrprogramm Aktive Fahrwerk Regelung (eAWS und eABC)";
CM_ SG_ 1000 CHA_Ziel_FahrPr_AV "Anforderung Ziel-Fahrprogramm AreaView2";
CM_ SG_ 1000 CHA_Ziel_FahrPr_EAR "Anforderung Zielfahrprogramm EAR (EFP Allrad Regelsysteme)";
CM_ SG_ 1000 CHA_Ziel_FahrPr_EBKV "Signal zur Ansteuerung des EBKV durch den Charisma-Koordinator";
CM_ SG_ 1000 CHA_Ziel_FahrPr_FCWO "Anforderung Ziel-Fahrprogramm FCWO (Objektwarnung)";
CM_ SG_ 1000 CHA_Ziel_FahrPr_FCWP "Anforderung Ziel-Fahrprogramm FCWP (Personenwarnung)";
CM_ SG_ 1000 CHA_Ziel_FahrPr_HAL "Anforderung Zielfahrprogramm Hinterachslenkung (HAL)";
CM_ SG_ 1000 CHA_Ziel_FahrPr_HDC "Anforderung Ziel-Fahrprogramm Hill Descent Control";
CM_ SG_ 1000 CHA_Ziel_FahrPr_IL "Anforderung Ziel-Fahrprogramm Integrallenkung";
CM_ SG_ 1000 CHA_Ziel_FahrPr_MXB "Anforderung Ziel-Fahrprogramm MXB";
CM_ SG_ 1000 CHA_Ziel_FahrPr_NR "Anforderung Ziel-Fahrprogramm Niveaureglierung";
CM_ SG_ 1000 CHA_Ziel_FahrPr_QS "Anforderung Ziel-Fahrprogramm geregelte Hinterachsquersperre";
CM_ SG_ 1000 CHA_Ziel_FahrPr_SCU "Anforderung Ziel-Fahrprogramm SCU";
CM_ SG_ 1000 CHA_Ziel_FahrPr_WarnBrems "Anforderung Ziel-Fahrprogramm für Funktion Warn- und/oder Notbremsfunktion";

CM_ SG_ 1714 DGN_Verlernzaehler "wrap around 254 --> 0";
CM_ SG_ 1714 KBI_Kilometerstand "Fehler wird ausgegeben, falls Kilometerstand nicht restaurierbar
";
CM_ SG_ 1714 UH_Minute "0x3C- 0x3f = Werte ungültig";
CM_ SG_ 1714 UH_Monat "0x0D, 0xF =  Werte ungültig
0x0E = Relatives Datum (nur VW)";
CM_ SG_ 1714 UH_Sekunde "0x3C- 0x3f = Werte ungültig";
CM_ SG_ 1714 UH_Stunde "0x18 - 0x1F = Werte ungültig";
CM_ SG_ 1714 UH_Tag "0x0: reserviert bei VW";
CM_ SG_ 1714 Uhrzeit_01_alt "
";

CM_ SG_ 1520 BCM1_Stellgroesse_Kl_58s "Rohwert Dimmpoti";
CM_ SG_ 1520 DI_Display_Nachtdesign "Für Displays sind oft  automatische Umschaltungen von Tag-/Nachtdesign vorgesehen.
Es gibt jedoch Zustände, an denen auch tagsüber das Abblendlicht eingeschaltet ist.
z.B. Dauerfahrlicht, Geschwindigkeitsabhängiges 'Licht-An-Bei-Autobahn', 'Regenlicht',";
CM_ SG_ 1520 DI_Fotosensor "Helligkeitswert Fotosensor
Für die Dimmung relevanter Wert zur Sensierung der Umgebungshelligkeit
Im Detail beschrieben im 'Funktionslastenheft Dimmung MQB'.";
CM_ SG_ 1520 DI_KL_58xd "Klemme 58xd Display- und Funktionsbeleuchtung
Mit der Klemme 58xd wird die Helligkeit der Display- und der Funktionsbeleuchtungen der Schalter gesteuert.
Im Detail beschrieben im 'Funktionslastenheft Dimmung MQB'.";
CM_ SG_ 1520 DI_KL_58xs "Suchbeleuchtung Schalter
EIN-AUS-Schaltalgorithmus der allgemeinen Schaltersuchbeleuchtung. 
Im Detail beschrieben im 'Funktionslastenheft Dimmung MQB'.
";
CM_ SG_ 1520 DI_KL_58xt "Timergesteuerte Suchbeleuchtung
Der EIN-AUS-Schaltalgorithmus für die vor- und nachlaufende Schaltersuchbeleuchtungen beim Ein- & Aussteigen; z.B.: Start/Stop-Taster.
Im Detail beschrieben im 'Funktionslastenheft Dimmung MQB'.";

CM_ SG_ null USSDM_Blindness "Indicates whether or not the driver monitoring system is blind.";
CM_ SG_ null USSDM_CalibrationStatus "Calibration status of the driver monitoring system.";
CM_ SG_ null USSDM_DriverPresence "Determines whether a driver has been detected on the driver seat and whether the driver is buckled up.";
CM_ SG_ null USSDM_EyesClosed "Indicates whether the driver's eyes are closed. Parametrized such that false positives are minimized.";
CM_ SG_ null USSDM_EyesFound "Indicates whether eyes are found by the driver monitoring system.";
CM_ SG_ null USSDM_EyesOffRoadTime "Time the driver has not paid attention to traffic.";
CM_ SG_ null USSDM_EyesOnRoad "Indicates whether or not the driver is paying attention to traffic.";
CM_ SG_ null USSDM_EyesOnRoadQual "Confidence factor of signal USSDM_EyesOnRoad.";
CM_ SG_ null USSDM_EyesOpen "Indicates whether the driver's eyes are open. Parametrized such that false positives are minimized.";
CM_ SG_ null USSDM_FakeDetected "Indicates whether or not the driver monitoring system has detected an attempt at deception (e.g. masks).";
CM_ SG_ null USSDM_HeadBasedMirrorSelection "Outer mirror selection based on the driver's viewing direction.";
CM_ SG_ null USSDM_HeadFound "Indicates whether a head is found by the driver monitoring system.";
CM_ SG_ null USSDM_Microsleep "Camera-based microsleep detection. Only to used along with USSDM_MicrosleepQual.";
CM_ SG_ null USSDM_MicrosleepQual "Confidence factor of signal USSDM_Microsleep.";
CM_ SG_ null USSDM_Status "General status of the driver monitoring system";
CM_ SG_ null USSDM_VisualDistractionLevel "Camera-based visual distraction of the driver. Only to be used along with USSDM_VisualDistractionQual.";
CM_ SG_ null USSDM_VisualDistractionQual "Confidence factor of signal USSDM_VisualDistractionLevel.";

CM_ SG_ null USSDM_DetectionMode "Indicates whether head pose, gaze, or a comination of head pose and gaze is used for visual perception estimation.";
CM_ SG_ null USSDM_DurEyesOffTfc "Duration the driver has continuously not paid attention to traffic.";
CM_ SG_ null USSDM_EyesOnTrafficQual "Confidence factor of signal USSDM_EyesOnTraffic.";
CM_ SG_ null USSDM_ProbScndTsk "Probability Secondary Task: Probability that the driver is performing a secondary task.";
CM_ SG_ null USSDM_SpaAttDstrAr_01 "Spatial Attention Distribution Area 1: Most likely Area of Interest the driver is currently looking at.";
CM_ SG_ null USSDM_SpaAttDstrAr_02 "Spatial Attention Distribution Area 2: Second most likely Area of Interest the driver is currently looking at.";
CM_ SG_ null USSDM_SpaAttDstrAr_03 "Spatial Attention Distribution Area 3: Third most likely Area of Interest the driver is currently looking at.";
CM_ SG_ null USSDM_SpaAttDstrProb_01 "Spatial Attention Distribution Probability 1: Probability the driver is currently looking at the Area of Interest given in signal 'USSDM_SpaAttDstrAr_01'.";
CM_ SG_ null USSDM_TotDurEyesNotOnTfc "Total Duration the driver has not paid attention to traffic within a fixed time window including both continous glances and short glances.";

CM_ SG_ null USSDM_DurEyesCl "Duration the driver's eyes have been continuously closed.";
CM_ SG_ null USSDM_DurEyesNotOnTfc "Duration the driver has continuously not paid attention to traffic.";
CM_ SG_ null USSDM_PercentageEyesOnTraffic "Relative duration the driver has monitored the traffic within a fixed time window.";
CM_ SG_ null USSDM_SpaAttDstrProb_02 "Spatial Attention Distribution Probability 2: Probability the driver is currently looking at the Area of Interest given in signal 'USSDM_SpaAttDstrAr_02'.";
CM_ SG_ null USSDM_SpaAttDstrProb_03 "Spatial Attention Distribution Probability 3: Probability the driver is currently looking at the Area of Interest given in signal 'USSDM_SpaAttDstrAr_03'.";
CM_ SG_ null USSDM_ViewingDirectionPitch "Pitch value of the driver's viewing direction.";
CM_ SG_ null USSDM_ViewingDirectionQuality "Confidence factor of the driver's viewing direction.";
CM_ SG_ null USSDM_ViewingDirectionYaw "Yaw value of the driver's viewing direction.";

CM_ SG_ null USSDM_BlinkRate "Number of blinks detected within a fixed time window.";
CM_ SG_ null USSDM_DriverChange "Determines whether a driver change has been detected.";
CM_ SG_ null USSDM_DriverPhoneUsage "Indicates whether or not driver phone usage is detected.";
CM_ SG_ null USSDM_DriverPhoneUsageQual "Quality signal for signal USSDM_DriverPhoneUsage.";
CM_ SG_ null USSDM_DriverSmoking "Indicates whether or not driver skmoking is detected.";
CM_ SG_ null USSDM_DriverSmokingQual "Quality signal for signal USSDM_DriverSmoking.";
CM_ SG_ null USSDM_DriverSpeaking "Determines whether the driver is speaking.";
CM_ SG_ null USSDM_DriverYawning "Indicates whether or not driver yawning is detected based on a width to height ratio of the driver's mouth opening";
CM_ SG_ null USSDM_DriverYawningQual "Quality signal for signal USSDM_DriverYawning.";
CM_ SG_ null USSDM_DrowsinessLevel "Camera-based drowsiness level of the driver. Only to be used along with USSDM_DrowsinessQual.";
CM_ SG_ null USSDM_DrowsinessQual "Confidence factor of signal USSDM_DrowsinessLevel.";
CM_ SG_ null USSDM_UnusualHeadPose "Determines whether the driver's head is detected to be in an unusual pose.";
CM_ SG_ null USSDM_UnusualHeadPoseQual "Quality signal for signal USSDM_UnusualHeadPose.";

BA_DEF_  "DBName" STRING;
BA_DEF_  "GenNWMApBusSleep" STRING;
BA_DEF_  "GenNWMApCanNormal" STRING;
BA_DEF_  "GenNWMApCanOff" STRING;
BA_DEF_  "GenNWMApCanOn" STRING;
BA_DEF_  "GenNWMApCanSleep" STRING;
BA_DEF_  "GenNWMApCanWakeUp" STRING;
BA_DEF_  "GenNWMGotoMode_Awake" STRING;
BA_DEF_  "GenNWMGotoMode_BusSleep" STRING;
BA_DEF_  "GenNWMSleepTime" INT 0 1000000;
BA_DEF_  "GenNWMTalkNM" STRING;
BA_DEF_  "Manufacturer" STRING;
BA_DEF_  "NmhBaseAddress" HEX 0 536870911;
BA_DEF_  "NmhMessageCount" INT 0 1024;
BA_DEF_  "NmType" STRING;
BA_DEF_  "VAGTP20_SetupMessageCount" INT 0 255;
BA_DEF_  "VAGTP20_SetupStartAddress" HEX 0 2047;
BA_DEF_  "VersionDay" INT 1 31;
BA_DEF_  "VersionMonth" INT 1 12;
BA_DEF_  "VersionWeek" INT 1 52;
BA_DEF_  "VersionYear" INT 0 99;
BA_DEF_  "VersionNumber" INT 0 65535;
BA_DEF_  "BusType" STRING;
BA_DEF_  "Baudrate" INT 1 1000000;
BA_DEF_  "SamplePointMin" INT 1 100;
BA_DEF_  "SamplePointMax" INT 1 100;
BA_DEF_  "SyncJumpWidthMin" INT 1 4;
BA_DEF_  "SyncJumpWidthMax" INT 1 4;
BA_DEF_  "NBTMin" INT 1 30;
BA_DEF_  "NBTMax" INT 1 30;
BA_DEF_  "NmhTimeoutTimer" INT 0 65535;
BA_DEF_  "NmhWaitBusSleepTimer" INT 0 65535;
BA_DEF_  "NmhPrepareBusSleepTimer" INT 0 65535;
BA_DEF_  "NmhLongTimer" INT 0 65535;
BA_DEF_  "NmhNStart" INT 0 255;
BA_DEF_ BU_  "GenNodAutoGenDsp" ENUM "No", "Yes";
BA_DEF_ BU_  "GenNodAutoGenSnd" ENUM "No", "Yes";
BA_DEF_ BU_  "GenNodSleepTime" INT 0 1000000;
BA_DEF_ BU_  "ILUsed" ENUM "No", "Yes";
BA_DEF_ BU_  "ECUVariantDefault" ENUM "No", "Yes";
BA_DEF_ BU_  "ECUVariantGroup" STRING;
BA_DEF_ BU_  "NodeLayerModules" STRING;
BA_DEF_ BU_  "NmhNode" ENUM "No", "Yes";
BA_DEF_ BU_  "NmNode" ENUM "No", "Yes";
BA_DEF_REL_ BU_SG_REL_  "GenSigTimeoutTime" INT 0 65535;
BA_DEF_ BO_  "DiagRequest" ENUM "No", "Yes";
BA_DEF_ BO_  "DiagResponse" ENUM "No", "Yes";
BA_DEF_ BO_  "DiagState" ENUM "No", "Yes";
BA_DEF_ BO_  "GenMsgChkConstant" HEX 0 4095;
BA_DEF_ BO_  "GenMsgCycleTime" INT 0 65535;
BA_DEF_ BO_  "GenMsgCycleTimeFast" INT 0 65535;
BA_DEF_ BO_  "GenMsgDelayTime" INT 0 100000;
BA_DEF_ BO_  "GenMsgILSupport" ENUM "No", "Yes";
BA_DEF_ BO_  "GenMsgNrOfRepetition" INT 0 100;
BA_DEF_ BO_  "GenMsgPDUConstants" STRING;
BA_DEF_ BO_  "GenMsgSendType" ENUM "Cyclic", "not_used", "not_used", "not_used", "not_used", "not_used", "not_used", "IfActive", "NoMsgSendType";
BA_DEF_ BO_  "GenMsgStartDelayTime" INT 0 100000;
BA_DEF_ BO_  "NmMessage" ENUM "No", "Yes";
BA_DEF_ BO_  "NmhMessage" ENUM "No", "Yes";
BA_DEF_ BO_  "MsgType" ENUM "Application", "NM ", "NMH", "TP2.0", "ISO-TP ", "BAP", "EID", "KS", "XCP_PRE_CONFIGURED", "XCP_RUNTIME_CONFIGURED";
BA_DEF_ BO_  "VAGTP20_API" HEX 0 255;
BA_DEF_ BO_  "VAGTP20_DynConnection" ENUM "No", "Yes";
BA_DEF_ BO_  "VAGTP20_DynSetup" ENUM "No", "Yes";
BA_DEF_ BO_  "VAGTP20_StatConnection" ENUM "No", "Yes";
BA_DEF_ SG_  "GenSigActiveRepetitions" INT -2147483648 2147483647;
BA_DEF_ SG_  "GenSigInactiveValue" INT -2147483648 2147483647;
BA_DEF_ SG_  "GenSigSendType" ENUM "Cyclic", "OnWrite", "OnWriteWithRepetition", "OnChange", "OnChangeWithRepetition", "IfActive", "IfActiveWithRepetition", "NoSigSendType", "OnChangeAndIfActive", "OnChangeAndIfActiveWithRepetition";
BA_DEF_ SG_  "GenSigStartValue" INT -2147483648 2147483647;
BA_DEF_ SG_  "NWM-WakeupAllowed" ENUM "No", "Yes";
BA_DEF_ SG_  "GenSigFuncType" ENUM "NoFunction", "MsgCounter", "CRC-8", "XOR", "XOR-2", "DatedBit", "SW-Kl15", "CHK", "Constant", "Protocol", "CRC-8-SAE_J1850", "CRC-32", "DataLength", "DataID", "MsgCounter16", "SOK-Signatur", "Cluster";
BA_DEF_ SG_  "GenSigSwitchedByIgnition" ENUM "No", "Yes";
BA_DEF_ SG_  "Fehlerwert" HEX 0 2147483647;
BA_DEF_ SG_  "GenSigMissingSourceValue" HEX 0 2147483647;
BA_DEF_DEF_  "DBName" "";
BA_DEF_DEF_  "GenNWMApBusSleep" "";
BA_DEF_DEF_  "GenNWMApCanNormal" "";
BA_DEF_DEF_  "GenNWMApCanOff" "";
BA_DEF_DEF_  "GenNWMApCanOn" "";
BA_DEF_DEF_  "GenNWMApCanSleep" "";
BA_DEF_DEF_  "GenNWMApCanWakeUp" "";
BA_DEF_DEF_  "GenNWMGotoMode_Awake" "";
BA_DEF_DEF_  "GenNWMGotoMode_BusSleep" "";
BA_DEF_DEF_  "GenNWMSleepTime" 0;
BA_DEF_DEF_  "GenNWMTalkNM" "";
BA_DEF_DEF_  "Manufacturer" "";
BA_DEF_DEF_  "NmhBaseAddress" 0;
BA_DEF_DEF_  "NmhMessageCount" 1;
BA_DEF_DEF_  "NmType" "None";
BA_DEF_DEF_  "VAGTP20_SetupMessageCount" 0;
BA_DEF_DEF_  "VAGTP20_SetupStartAddress" 0;
BA_DEF_DEF_  "VersionDay" 2;
BA_DEF_DEF_  "VersionMonth" 6;
BA_DEF_DEF_  "VersionWeek" 23;
BA_DEF_DEF_  "VersionYear" 22;
BA_DEF_DEF_  "VersionNumber" 0;
BA_DEF_DEF_  "BusType" "";
BA_DEF_DEF_  "Baudrate" 1;
BA_DEF_DEF_  "SamplePointMin" 1;
BA_DEF_DEF_  "SamplePointMax" 1;
BA_DEF_DEF_  "SyncJumpWidthMin" 1;
BA_DEF_DEF_  "SyncJumpWidthMax" 1;
BA_DEF_DEF_  "NBTMin" 10;
BA_DEF_DEF_  "NBTMax" 20;
BA_DEF_DEF_  "NmhTimeoutTimer" 0;
BA_DEF_DEF_  "NmhWaitBusSleepTimer" 0;
BA_DEF_DEF_  "NmhPrepareBusSleepTimer" 0;
BA_DEF_DEF_  "NmhLongTimer" 0;
BA_DEF_DEF_  "NmhNStart" 0;
BA_DEF_DEF_  "GenNodAutoGenDsp" "Yes";
BA_DEF_DEF_  "GenNodAutoGenSnd" "Yes";
BA_DEF_DEF_  "GenNodSleepTime" 0;
BA_DEF_DEF_  "ILUsed" "Yes";
BA_DEF_DEF_  "ECUVariantDefault" "Yes";
BA_DEF_DEF_  "ECUVariantGroup" "";
BA_DEF_DEF_  "NodeLayerModules" "";
BA_DEF_DEF_  "NmhNode" "Yes";
BA_DEF_DEF_  "NmNode" "No";
BA_DEF_DEF_REL_  "GenSigTimeoutTime" 0;
BA_DEF_DEF_  "DiagRequest" "No";
BA_DEF_DEF_  "DiagResponse" "No";
BA_DEF_DEF_  "DiagState" "No";
BA_DEF_DEF_  "GenMsgChkConstant" 0;
BA_DEF_DEF_  "GenMsgCycleTime" 0;
BA_DEF_DEF_  "GenMsgCycleTimeFast" 0;
BA_DEF_DEF_  "GenMsgDelayTime" 0;
BA_DEF_DEF_  "GenMsgILSupport" "No";
BA_DEF_DEF_  "GenMsgNrOfRepetition" 0;
BA_DEF_DEF_  "GenMsgPDUConstants" "";
BA_DEF_DEF_  "GenMsgSendType" "NoMsgSendType";
BA_DEF_DEF_  "GenMsgStartDelayTime" 0;
BA_DEF_DEF_  "NmMessage" "No";
BA_DEF_DEF_  "NmhMessage" "No";
BA_DEF_DEF_  "MsgType" "Application";
BA_DEF_DEF_  "VAGTP20_API" 0;
BA_DEF_DEF_  "VAGTP20_DynConnection" "No";
BA_DEF_DEF_  "VAGTP20_DynSetup" "No";
BA_DEF_DEF_  "VAGTP20_StatConnection" "No";
BA_DEF_DEF_  "GenSigActiveRepetitions" 0;
BA_DEF_DEF_  "GenSigInactiveValue" 0;
BA_DEF_DEF_  "GenSigSendType" "NoSigSendType";
BA_DEF_DEF_  "GenSigStartValue" 0;
BA_DEF_DEF_  "NWM-WakeupAllowed" "No";
BA_DEF_DEF_  "GenSigFuncType" "NoFunction";
BA_DEF_DEF_  "GenSigSwitchedByIgnition" "Yes";
BA_DEF_DEF_  "Fehlerwert" 0;
BA_DEF_DEF_  "GenSigMissingSourceValue" 0;
BA_  "DBName" "MLBevo_ECAN";
BA_  "GenNWMApBusSleep" "NMIndNetSDN()";
BA_  "GenNWMApCanNormal" "apCanNormal()";
BA_  "GenNWMApCanOff" "NMIndnetOff()";
BA_  "GenNWMApCanOn" "NMIndnetOn()";
BA_  "GenNWMApCanSleep" "apCanSleep()";
BA_  "GenNWMApCanWakeUp" "apCanWakeUp()";
BA_  "GenNWMGotoMode_Awake" "Nmh_ReqNetOn()";
BA_  "GenNWMGotoMode_BusSleep" "Nmh_ReqNetOff()";
BA_  "GenNWMSleepTime" 4000;
BA_  "GenNWMTalkNM" "Nmh_ReqNetOn()";
BA_  "Manufacturer" "VAG";
BA_  "NmhBaseAddress" 452984832;
BA_  "NmhMessageCount" 256;
BA_  "NmType" "NM-High";
BA_  "VAGTP20_SetupMessageCount" 128;
BA_  "VAGTP20_SetupStartAddress" 512;
BA_  "VersionNumber" 2400;
BA_  "BusType" "CAN";
BA_  "Baudrate" 500000;
BA_  "SamplePointMin" 80;
BA_  "SamplePointMax" 84;
BA_  "SyncJumpWidthMin" 2;
BA_  "SyncJumpWidthMax" 4;
BA_  "NmhTimeoutTimer" 1000;
BA_  "NmhWaitBusSleepTimer" 750;
BA_  "NmhPrepareBusSleepTimer" 500;
BA_  "NmhLongTimer" 200;
BA_  "NmhNStart" 20;
BA_ "GenNodSleepTime" BU_ AEM 4000;
BA_ "ECUVariantGroup" BU_ AEM "AEM";
BA_ "NmhNode" BU_ AEM 0;
BA_ "GenNodSleepTime" BU_ BAP_Tester 4000;
BA_ "ECUVariantGroup" BU_ BAP_Tester "BAP";
BA_ "NmhNode" BU_ BAP_Tester 0;
BA_ "GenNodSleepTime" BU_ E_Sound 4000;
BA_ "ECUVariantDefault" BU_ E_Sound 0;
BA_ "ECUVariantGroup" BU_ E_Sound "AGA";
BA_ "GenNodSleepTime" BU_ FBK 4000;
BA_ "NmhNode" BU_ FBK 0;
BA_ "GenNodSleepTime" BU_ FLA 4000;
BA_ "ECUVariantDefault" BU_ FLA 0;
BA_ "ECUVariantGroup" BU_ FLA "Frontsensorik";
BA_ "NmhNode" BU_ FLA 0;
BA_ "GenNodSleepTime" BU_ Gateway 4000;
BA_ "ECUVariantGroup" BU_ Gateway "Gateway";
BA_ "NodeLayerModules" BU_ Gateway "NMHigh.DLL";
BA_ "GenNodSleepTime" BU_ Gateway_PAG 4000;
BA_ "ECUVariantDefault" BU_ Gateway_PAG 0;
BA_ "ECUVariantGroup" BU_ Gateway_PAG "Gateway";
BA_ "NodeLayerModules" BU_ Gateway_PAG "NMHigh.DLL";
BA_ "GenNodSleepTime" BU_ ISE 4000;
BA_ "ECUVariantDefault" BU_ ISE 0;
BA_ "ECUVariantGroup" BU_ ISE "SAK";
BA_ "GenNodSleepTime" BU_ MRR_HL 4000;
BA_ "ECUVariantDefault" BU_ MRR_HL 0;
BA_ "ECUVariantGroup" BU_ MRR_HL "SWA_Slave";
BA_ "NodeLayerModules" BU_ MRR_HL "NMHigh.DLL";
BA_ "GenNodSleepTime" BU_ MRR_HR 4000;
BA_ "ECUVariantDefault" BU_ MRR_HR 0;
BA_ "ECUVariantGroup" BU_ MRR_HR "SWA_Master";
BA_ "NodeLayerModules" BU_ MRR_HR "NMHigh.DLL";
BA_ "GenNodSleepTime" BU_ NightVision 4000;
BA_ "ECUVariantGroup" BU_ NightVision "Nightvision";
BA_ "NodeLayerModules" BU_ NightVision "NMHigh.DLL";
BA_ "GenNodSleepTime" BU_ RDK 4000;
BA_ "ECUVariantGroup" BU_ RDK "RDK";
BA_ "NodeLayerModules" BU_ RDK "NMHigh.DLL";
BA_ "GenNodSleepTime" BU_ SAK 4000;
BA_ "ECUVariantGroup" BU_ SAK "SAK";
BA_ "NmhNode" BU_ SAK 0;
BA_ "GenNodSleepTime" BU_ SAK2 4000;
BA_ "ECUVariantGroup" BU_ SAK2 "AGA";
BA_ "NmhNode" BU_ SAK2 0;
BA_ "GenNodSleepTime" BU_ SCR 4000;
BA_ "ECUVariantGroup" BU_ SCR "SCR";
BA_ "NodeLayerModules" BU_ SCR "NMHigh.DLL";
BA_ "GenNodSleepTime" BU_ STH_MLBevo 4000;
BA_ "ECUVariantGroup" BU_ STH_MLBevo "STH";
BA_ "NodeLayerModules" BU_ STH_MLBevo "NMHigh.DLL";
BA_ "GenNodSleepTime" BU_ TopView 4000;
BA_ "ECUVariantGroup" BU_ TopView "RearView";
BA_ "NodeLayerModules" BU_ TopView "NMHigh.DLL";
BA_ "GenMsgCycleTime" BO_ null 80;
BA_ "GenMsgILSupport" BO_ null 1;
BA_ "GenMsgSendType" BO_ null 0;
BA_ "GenMsgCycleTime" BO_ 1469 500;
BA_ "GenMsgILSupport" BO_ 1469 1;
BA_ "GenMsgSendType" BO_ 1469 0;
BA_ "GenMsgChkConstant" BO_ 1660 223;
BA_ "GenMsgCycleTime" BO_ 1660 1000;
BA_ "GenMsgDelayTime" BO_ 1660 100;
BA_ "GenMsgILSupport" BO_ 1660 1;
BA_ "GenMsgPDUConstants" BO_ 1660 "0xdf,0xdf,0xdf,0xdf,0xdf,0xdf,0xdf,0xdf,0xdf,0xdf,0xdf,0xdf,0xdf,0xdf,0xdf,0xdf";
BA_ "GenMsgSendType" BO_ 1660 0;
BA_ "GenMsgChkConstant" BO_ 64 64;
BA_ "GenMsgCycleTime" BO_ 64 40;
BA_ "GenMsgCycleTimeFast" BO_ 64 10;
BA_ "GenMsgDelayTime" BO_ 64 10;
BA_ "GenMsgILSupport" BO_ 64 1;
BA_ "GenMsgNrOfRepetition" BO_ 64 5;
BA_ "GenMsgPDUConstants" BO_ 64 "0x40,0x40,0x40,0x40,0x40,0x40,0x40,0x40,0x40,0x40,0x40,0x40,0x40,0x40,0x40,0x40";
BA_ "GenMsgSendType" BO_ 64 0;
BA_ "GenMsgChkConstant" BO_ 1312 68;
BA_ "GenMsgCycleTime" BO_ 1312 200;
BA_ "GenMsgDelayTime" BO_ 1312 20;
BA_ "GenMsgILSupport" BO_ 1312 1;
BA_ "GenMsgPDUConstants" BO_ 1312 "0x44,0x44,0x44,0x44,0x44,0x44,0x44,0x44,0x44,0x44,0x44,0x44,0x44,0x44,0x44,0x44";
BA_ "GenMsgSendType" BO_ 1312 0;
BA_ "GenMsgCycleTime" BO_ 1349 200;
BA_ "GenMsgDelayTime" BO_ 1349 40;
BA_ "GenMsgILSupport" BO_ 1349 1;
BA_ "GenMsgPDUConstants" BO_ 1349 "0x95,0x19,0xd1,0x36,0x89,0xd4,0x02,0x1e,0xb9,0x80,0xd0,0x22,0x8a,0xf4,0x15,0xb8";
BA_ "GenMsgSendType" BO_ 1349 0;
BA_ "GenMsgCycleTime" BO_ 326 40;
BA_ "GenMsgILSupport" BO_ 326 1;
BA_ "GenMsgPDUConstants" BO_ 326 "0x97,0x42,0xb2,0x9d,0x19,0x16,0x75,0x86,0x3c,0x7c,0xa9,0x10,0xc9,0x5a,0xea,0xf9";
BA_ "GenMsgSendType" BO_ 326 0;
BA_ "GenMsgCycleTime" BO_ 1633 100;
BA_ "GenMsgILSupport" BO_ 1633 1;
BA_ "GenMsgSendType" BO_ 1633 0;
BA_ "GenMsgCycleTime" BO_ 348 100;
BA_ "GenMsgCycleTimeFast" BO_ 348 20;
BA_ "GenMsgILSupport" BO_ 348 1;
BA_ "GenMsgNrOfRepetition" BO_ 348 5;
BA_ "GenMsgSendType" BO_ 348 0;
BA_ "GenMsgCycleTime" BO_ 345 100;
BA_ "GenMsgDelayTime" BO_ 345 20;
BA_ "GenMsgILSupport" BO_ 345 1;
BA_ "GenMsgSendType" BO_ 345 0;
BA_ "GenMsgCycleTime" BO_ 1013 100;
BA_ "GenMsgILSupport" BO_ 1013 1;
BA_ "GenMsgSendType" BO_ 1013 0;
BA_ "MsgType" BO_ 2536767264 5;
BA_ "MsgType" BO_ 2536767280 5;
BA_ "MsgType" BO_ 2536708096 5;
BA_ "MsgType" BO_ 2536708097 5;
BA_ "MsgType" BO_ 2536708112 5;
BA_ "MsgType" BO_ 2536704513 5;
BA_ "MsgType" BO_ 2536704528 5;
BA_ "MsgType" BO_ 2536704529 5;
BA_ "MsgType" BO_ 2536703744 5;
BA_ "MsgType" BO_ 2536703745 5;
BA_ "MsgType" BO_ 2536703746 5;
BA_ "MsgType" BO_ 2536703760 5;
BA_ "MsgType" BO_ 2536704768 5;
BA_ "MsgType" BO_ 2536704784 5;
BA_ "MsgType" BO_ 2536728064 5;
BA_ "MsgType" BO_ 2536728080 5;
BA_ "MsgType" BO_ 2536719360 5;
BA_ "MsgType" BO_ 2536719376 5;
BA_ "MsgType" BO_ 2536708608 5;
BA_ "MsgType" BO_ 2536708609 5;
BA_ "MsgType" BO_ 2536708624 5;
BA_ "GenMsgCycleTime" BO_ 1626 1000;
BA_ "GenMsgCycleTimeFast" BO_ 1626 100;
BA_ "GenMsgDelayTime" BO_ 1626 50;
BA_ "GenMsgILSupport" BO_ 1626 1;
BA_ "GenMsgNrOfRepetition" BO_ 1626 10;
BA_ "GenMsgSendType" BO_ 1626 0;
BA_ "GenMsgCycleTime" BO_ 2527679637 1000;
BA_ "GenMsgDelayTime" BO_ 2527679637 50;
BA_ "GenMsgILSupport" BO_ 2527679637 1;
BA_ "GenMsgSendType" BO_ 2527679637 0;
BA_ "GenMsgCycleTime" BO_ 961 200;
BA_ "GenMsgCycleTimeFast" BO_ 961 20;
BA_ "GenMsgDelayTime" BO_ 961 20;
BA_ "GenMsgILSupport" BO_ 961 1;
BA_ "GenMsgNrOfRepetition" BO_ 961 5;
BA_ "GenMsgSendType" BO_ 961 0;
BA_ "GenMsgCycleTime" BO_ 1432 1000;
BA_ "GenMsgCycleTimeFast" BO_ 1432 100;
BA_ "GenMsgDelayTime" BO_ 1432 50;
BA_ "GenMsgILSupport" BO_ 1432 1;
BA_ "GenMsgNrOfRepetition" BO_ 1432 5;
BA_ "GenMsgSendType" BO_ 1432 0;
BA_ "MsgType" BO_ 2617189888 6;
BA_ "MsgType" BO_ 2617189889 6;
BA_ "MsgType" BO_ 2617042432 6;
BA_ "MsgType" BO_ 2617042433 6;
BA_ "GenMsgCycleTime" BO_ 901 1000;
BA_ "GenMsgDelayTime" BO_ 901 50;
BA_ "GenMsgILSupport" BO_ 901 1;
BA_ "GenMsgSendType" BO_ 901 0;
BA_ "GenMsgStartDelayTime" BO_ 901 50;
BA_ "GenMsgCycleTime" BO_ 1000 1000;
BA_ "GenMsgDelayTime" BO_ 1000 50;
BA_ "GenMsgILSupport" BO_ 1000 1;
BA_ "GenMsgSendType" BO_ 1000 0;
BA_ "GenMsgStartDelayTime" BO_ 1000 55;
BA_ "MsgType" BO_ 2617078272 6;
BA_ "MsgType" BO_ 2617078527 6;
BA_ "MsgType" BO_ 2617188864 6;
BA_ "MsgType" BO_ 2617189119 6;
BA_ "MsgType" BO_ 2617082368 6;
BA_ "MsgType" BO_ 2617082623 6;
BA_ "MsgType" BO_ 2617063936 6;
BA_ "MsgType" BO_ 2617064191 6;
BA_ "MsgType" BO_ 2617006592 6;
BA_ "MsgType" BO_ 2617006847 6;
BA_ "MsgType" BO_ 2617199104 6;
BA_ "MsgType" BO_ 2617199359 6;
BA_ "MsgType" BO_ 2617070080 6;
BA_ "MsgType" BO_ 2617070335 6;
BA_ "MsgType" BO_ 2617041408 6;
BA_ "MsgType" BO_ 2617041663 6;
BA_ "MsgType" BO_ 2617201152 6;
BA_ "MsgType" BO_ 2617201407 6;
BA_ "MsgType" BO_ 2617004800 6;
BA_ "MsgType" BO_ 2617005055 6;
BA_ "MsgType" BO_ 2617143808 6;
BA_ "MsgType" BO_ 2617144063 6;
BA_ "GenMsgCycleTime" BO_ 1714 1000;
BA_ "GenMsgILSupport" BO_ 1714 1;
BA_ "GenMsgSendType" BO_ 1714 0;
BA_ "GenMsgStartDelayTime" BO_ 1714 55;
BA_ "GenMsgCycleTime" BO_ 1520 200;
BA_ "GenMsgDelayTime" BO_ 1520 50;
BA_ "GenMsgILSupport" BO_ 1520 1;
BA_ "GenMsgSendType" BO_ 1520 0;
BA_ "GenMsgCycleTime" BO_ null 20;
BA_ "GenMsgILSupport" BO_ null 1;
BA_ "GenMsgSendType" BO_ null 0;
BA_ "GenMsgCycleTime" BO_ null 20;
BA_ "GenMsgILSupport" BO_ null 1;
BA_ "GenMsgSendType" BO_ null 0;
BA_ "GenMsgCycleTime" BO_ null 20;
BA_ "GenMsgILSupport" BO_ null 1;
BA_ "GenMsgSendType" BO_ null 0;
BA_ "GenMsgCycleTime" BO_ null 100;
BA_ "GenMsgILSupport" BO_ null 1;
BA_ "GenMsgSendType" BO_ null 0;
BA_ "GenSigSendType" SG_ null AB_GSCH_Reihe1_BF 0;
BA_ "GenSigSwitchedByIgnition" SG_ null AB_GSCH_Reihe1_BF 0;
BA_ "GenSigSendType" SG_ null AB_GSCH_Reihe1_FA 0;
BA_ "GenSigSwitchedByIgnition" SG_ null AB_GSCH_Reihe1_FA 0;
BA_ "GenSigSendType" SG_ null AB_Sg_Status_02_CompID 0;
BA_ "GenSigSendType" SG_ null BT_Tuer_Status 0;
BA_ "GenSigSwitchedByIgnition" SG_ null BT_Tuer_Status 0;
BA_ "Fehlerwert" SG_ null BT_Tuer_Status 3;
BA_ "GenSigSendType" SG_ null FT_Tuer_Status 0;
BA_ "GenSigSwitchedByIgnition" SG_ null FT_Tuer_Status 0;
BA_ "Fehlerwert" SG_ null FT_Tuer_Status 3;
BA_ "GenSigSendType" SG_ null VDSO_Vx3d 0;
BA_ "GenSigStartValue" SG_ null VDSO_Vx3d 65534;
BA_ "GenSigSwitchedByIgnition" SG_ null VDSO_Vx3d 0;
BA_ "Fehlerwert" SG_ null VDSO_Vx3d 65535;
BA_ "GenSigSendType" SG_ 1469 AEM_Status_Regelung 0;
BA_ "Fehlerwert" SG_ 1469 AEM_Status_Regelung 7;
BA_ "GenSigSendType" SG_ 1469 AEM_Temp_Abschaltung 0;
BA_ "GenSigSendType" SG_ 1660 AGA_01_BZ 0;
BA_ "GenSigFuncType" SG_ 1660 AGA_01_BZ 1;
BA_ "GenSigSendType" SG_ 1660 AGA_01_CRC 0;
BA_ "GenSigFuncType" SG_ 1660 AGA_01_CRC 2;
BA_ "GenSigSendType" SG_ 1660 AGA_Charisma_FahrPr 3;
BA_ "GenSigSendType" SG_ 1660 AGA_Charisma_Status 3;
BA_ "GenSigSendType" SG_ 1660 AGA_Verstaerker_Mute 0;
BA_ "GenSigSendType" SG_ 1660 E_Sound_Mute_Icon 3;
BA_ "GenSigStartValue" SG_ 1660 E_Sound_Mute_Icon 3;
BA_ "GenSigSendType" SG_ 1660 E_Sound_Mute_LED 3;
BA_ "GenSigStartValue" SG_ 1660 E_Sound_Mute_LED 3;
BA_ "GenSigSendType" SG_ 1660 E_Sound_ohne_Funktion 3;
BA_ "Fehlerwert" SG_ 1660 E_Sound_ohne_Funktion 1;
BA_ "GenSigSendType" SG_ 1660 E_Sound_Texte 3;
BA_ "Fehlerwert" SG_ 1660 E_Sound_Texte 7;
BA_ "GenSigSendType" SG_ 1660 E_Sound_verbaut 0;
BA_ "GenSigSendType" SG_ 64 AB_Anzeige_Fussg 0;
BA_ "GenSigSwitchedByIgnition" SG_ 64 AB_Anzeige_Fussg 0;
BA_ "GenSigSendType" SG_ 64 AB_Belegung_VF 0;
BA_ "GenSigSwitchedByIgnition" SG_ 64 AB_Belegung_VF 0;
BA_ "Fehlerwert" SG_ 64 AB_Belegung_VF 1;
BA_ "GenSigActiveRepetitions" SG_ 64 AB_Crash_Int 5;
BA_ "GenSigSendType" SG_ 64 AB_Crash_Int 4;
BA_ "GenSigSwitchedByIgnition" SG_ 64 AB_Crash_Int 0;
BA_ "GenSigSendType" SG_ 64 AB_Deaktiviert 0;
BA_ "GenSigSwitchedByIgnition" SG_ 64 AB_Deaktiviert 0;
BA_ "GenSigActiveRepetitions" SG_ 64 AB_Deaktivierung_HV 5;
BA_ "GenSigSendType" SG_ 64 AB_Deaktivierung_HV 4;
BA_ "GenSigSwitchedByIgnition" SG_ 64 AB_Deaktivierung_HV 0;
BA_ "Fehlerwert" SG_ 64 AB_Deaktivierung_HV 7;
BA_ "GenSigSendType" SG_ 64 AB_Diagnose 0;
BA_ "GenSigSwitchedByIgnition" SG_ 64 AB_Diagnose 0;
BA_ "GenSigSendType" SG_ 64 AB_EDR_Trigger 3;
BA_ "GenSigSwitchedByIgnition" SG_ 64 AB_EDR_Trigger 0;
BA_ "GenSigSendType" SG_ 64 AB_Erh_Auf_VB 0;
BA_ "GenSigSwitchedByIgnition" SG_ 64 AB_Erh_Auf_VB 0;
BA_ "GenSigActiveRepetitions" SG_ 64 AB_Front_Crash 5;
BA_ "GenSigSendType" SG_ 64 AB_Front_Crash 4;
BA_ "GenSigSwitchedByIgnition" SG_ 64 AB_Front_Crash 0;
BA_ "GenSigSendType" SG_ 64 AB_Gurtwarn_VB 0;
BA_ "GenSigSwitchedByIgnition" SG_ 64 AB_Gurtwarn_VB 0;
BA_ "GenSigSendType" SG_ 64 AB_Gurtwarn_VF 0;
BA_ "GenSigSwitchedByIgnition" SG_ 64 AB_Gurtwarn_VF 0;
BA_ "GenSigActiveRepetitions" SG_ 64 AB_Heck_Crash 5;
BA_ "GenSigSendType" SG_ 64 AB_Heck_Crash 4;
BA_ "GenSigSwitchedByIgnition" SG_ 64 AB_Heck_Crash 0;
BA_ "GenSigSendType" SG_ 64 AB_Lampe 0;
BA_ "GenSigStartValue" SG_ 64 AB_Lampe 1;
BA_ "GenSigSwitchedByIgnition" SG_ 64 AB_Lampe 0;
BA_ "GenSigActiveRepetitions" SG_ 64 AB_MKB_Anforderung 5;
BA_ "GenSigSendType" SG_ 64 AB_MKB_Anforderung 4;
BA_ "GenSigSwitchedByIgnition" SG_ 64 AB_MKB_Anforderung 0;
BA_ "GenSigSendType" SG_ 64 AB_MKB_gueltig 0;
BA_ "GenSigSwitchedByIgnition" SG_ 64 AB_MKB_gueltig 0;
BA_ "GenSigSendType" SG_ 64 AB_RGS_Anst 0;
BA_ "GenSigStartValue" SG_ 64 AB_RGS_Anst 8;
BA_ "GenSigSwitchedByIgnition" SG_ 64 AB_RGS_Anst 0;
BA_ "GenSigActiveRepetitions" SG_ 64 AB_Rollover_Crash 5;
BA_ "GenSigSendType" SG_ 64 AB_Rollover_Crash 4;
BA_ "GenSigSwitchedByIgnition" SG_ 64 AB_Rollover_Crash 0;
BA_ "GenSigActiveRepetitions" SG_ 64 AB_SB_Crash 5;
BA_ "GenSigSendType" SG_ 64 AB_SB_Crash 4;
BA_ "GenSigSwitchedByIgnition" SG_ 64 AB_SB_Crash 0;
BA_ "GenSigActiveRepetitions" SG_ 64 AB_SF_Crash 5;
BA_ "GenSigSendType" SG_ 64 AB_SF_Crash 4;
BA_ "GenSigSwitchedByIgnition" SG_ 64 AB_SF_Crash 0;
BA_ "GenSigSendType" SG_ 64 AB_Stellgliedtest 0;
BA_ "GenSigSwitchedByIgnition" SG_ 64 AB_Stellgliedtest 0;
BA_ "GenSigSendType" SG_ 64 AB_Systemfehler 0;
BA_ "GenSigSwitchedByIgnition" SG_ 64 AB_Systemfehler 0;
BA_ "GenSigSendType" SG_ 64 AB_Texte_AKS 0;
BA_ "GenSigSwitchedByIgnition" SG_ 64 AB_Texte_AKS 0;
BA_ "GenSigSendType" SG_ 64 AB_VB_deaktiviert 0;
BA_ "GenSigStartValue" SG_ 64 AB_VB_deaktiviert 1;
BA_ "GenSigSwitchedByIgnition" SG_ 64 AB_VB_deaktiviert 0;
BA_ "GenSigSendType" SG_ 64 AB_Versorgungsspannung 0;
BA_ "GenSigSwitchedByIgnition" SG_ 64 AB_Versorgungsspannung 0;
BA_ "GenSigSendType" SG_ 64 Airbag_01_BZ 0;
BA_ "GenSigFuncType" SG_ 64 Airbag_01_BZ 1;
BA_ "GenSigSwitchedByIgnition" SG_ 64 Airbag_01_BZ 0;
BA_ "GenSigSendType" SG_ 64 Airbag_01_CRC 0;
BA_ "GenSigFuncType" SG_ 64 Airbag_01_CRC 2;
BA_ "GenSigSwitchedByIgnition" SG_ 64 Airbag_01_CRC 0;
BA_ "GenSigSendType" SG_ 64 SC_LowSpeedCrashErkannt 0;
BA_ "GenSigSwitchedByIgnition" SG_ 64 SC_LowSpeedCrashErkannt 0;
BA_ "GenSigSendType" SG_ 64 SC_Masterzeit 0;
BA_ "GenSigStartValue" SG_ 64 SC_Masterzeit 127;
BA_ "GenSigSendType" SG_ 64 SC_Masterzeit_Offset 0;
BA_ "GenSigSendType" SG_ 1312 AB_Abschaltanf_SIH_BF 3;
BA_ "GenSigSendType" SG_ 1312 AB_Anforderung_eCall 0;
BA_ "GenSigSwitchedByIgnition" SG_ 1312 AB_Anforderung_eCall 0;
BA_ "GenSigSendType" SG_ 1312 AB_Anforderung_USM 0;
BA_ "GenSigSwitchedByIgnition" SG_ 1312 AB_Anforderung_USM 0;
BA_ "GenSigSendType" SG_ 1312 AB_Anprall_FGS 3;
BA_ "GenSigSendType" SG_ 1312 AB_Anprall_Front_Beifahrer 3;
BA_ "GenSigSendType" SG_ 1312 AB_Anprall_Front_Fahrer 3;
BA_ "GenSigSendType" SG_ 1312 AB_Anprall_Heck_Beifahrer 3;
BA_ "GenSigSendType" SG_ 1312 AB_Anprall_Heck_Fahrer 3;
BA_ "GenSigSendType" SG_ 1312 AB_Anprall_Rollover 3;
BA_ "GenSigSendType" SG_ 1312 AB_Anprall_Seite_Beifahrer 3;
BA_ "GenSigSendType" SG_ 1312 AB_Anprall_Seite_Fahrer 3;
BA_ "GenSigSendType" SG_ 1312 AB_Belegung_VB 0;
BA_ "GenSigSwitchedByIgnition" SG_ 1312 AB_Belegung_VB 0;
BA_ "Fehlerwert" SG_ 1312 AB_Belegung_VB 1;
BA_ "GenSigSendType" SG_ 1312 AB_Crashschwere 3;
BA_ "GenSigSwitchedByIgnition" SG_ 1312 AB_Crashschwere 0;
BA_ "Fehlerwert" SG_ 1312 AB_Crashschwere 7;
BA_ "GenSigSendType" SG_ 1312 AB_Gurtschloss_BF 3;
BA_ "GenSigStartValue" SG_ 1312 AB_Gurtschloss_BF 1;
BA_ "GenSigSwitchedByIgnition" SG_ 1312 AB_Gurtschloss_BF 0;
BA_ "GenSigSendType" SG_ 1312 AB_Gurtschloss_FA 3;
BA_ "GenSigStartValue" SG_ 1312 AB_Gurtschloss_FA 1;
BA_ "GenSigSwitchedByIgnition" SG_ 1312 AB_Gurtschloss_FA 0;
BA_ "GenSigSendType" SG_ 1312 AB_Gurtschloss_Reihe2_BF 3;
BA_ "GenSigStartValue" SG_ 1312 AB_Gurtschloss_Reihe2_BF 1;
BA_ "GenSigSwitchedByIgnition" SG_ 1312 AB_Gurtschloss_Reihe2_BF 0;
BA_ "GenSigSendType" SG_ 1312 AB_Gurtschloss_Reihe2_FA 3;
BA_ "GenSigStartValue" SG_ 1312 AB_Gurtschloss_Reihe2_FA 1;
BA_ "GenSigSwitchedByIgnition" SG_ 1312 AB_Gurtschloss_Reihe2_FA 0;
BA_ "GenSigSendType" SG_ 1312 AB_Gurtschloss_Reihe2_MI 3;
BA_ "GenSigStartValue" SG_ 1312 AB_Gurtschloss_Reihe2_MI 1;
BA_ "GenSigSwitchedByIgnition" SG_ 1312 AB_Gurtschloss_Reihe2_MI 0;
BA_ "GenSigSendType" SG_ 1312 AB_Gurtschloss_Reihe3_BF 3;
BA_ "GenSigStartValue" SG_ 1312 AB_Gurtschloss_Reihe3_BF 1;
BA_ "GenSigSwitchedByIgnition" SG_ 1312 AB_Gurtschloss_Reihe3_BF 0;
BA_ "GenSigSendType" SG_ 1312 AB_Gurtschloss_Reihe3_FA 3;
BA_ "GenSigStartValue" SG_ 1312 AB_Gurtschloss_Reihe3_FA 1;
BA_ "GenSigSwitchedByIgnition" SG_ 1312 AB_Gurtschloss_Reihe3_FA 0;
BA_ "GenSigSendType" SG_ 1312 AB_Gurtschloss_Reihe3_MI 3;
BA_ "GenSigStartValue" SG_ 1312 AB_Gurtschloss_Reihe3_MI 1;
BA_ "GenSigSwitchedByIgnition" SG_ 1312 AB_Gurtschloss_Reihe3_MI 0;
BA_ "GenSigSendType" SG_ 1312 AB_Sitzpos_Sens_BF 0;
BA_ "GenSigSwitchedByIgnition" SG_ 1312 AB_Sitzpos_Sens_BF 0;
BA_ "Fehlerwert" SG_ 1312 AB_Sitzpos_Sens_BF 1;
BA_ "GenSigSendType" SG_ 1312 AB_Sitzpos_Sens_FA 0;
BA_ "GenSigSwitchedByIgnition" SG_ 1312 AB_Sitzpos_Sens_FA 0;
BA_ "Fehlerwert" SG_ 1312 AB_Sitzpos_Sens_FA 1;
BA_ "GenSigSendType" SG_ 1312 AB_Wickelklappung_Reihe2_BF 3;
BA_ "GenSigStartValue" SG_ 1312 AB_Wickelklappung_Reihe2_BF 1;
BA_ "GenSigSwitchedByIgnition" SG_ 1312 AB_Wickelklappung_Reihe2_BF 0;
BA_ "GenSigSendType" SG_ 1312 AB_Wickelklappung_Reihe2_FA 3;
BA_ "GenSigStartValue" SG_ 1312 AB_Wickelklappung_Reihe2_FA 1;
BA_ "GenSigSwitchedByIgnition" SG_ 1312 AB_Wickelklappung_Reihe2_FA 0;
BA_ "GenSigSendType" SG_ 1312 AB_Wickelklappung_Reihe2_MI 3;
BA_ "GenSigStartValue" SG_ 1312 AB_Wickelklappung_Reihe2_MI 1;
BA_ "GenSigSwitchedByIgnition" SG_ 1312 AB_Wickelklappung_Reihe2_MI 0;
BA_ "GenSigSendType" SG_ 1312 Airbag_02_BZ 0;
BA_ "GenSigFuncType" SG_ 1312 Airbag_02_BZ 1;
BA_ "GenSigSwitchedByIgnition" SG_ 1312 Airbag_02_BZ 0;
BA_ "GenSigSendType" SG_ 1312 Airbag_02_CRC 0;
BA_ "GenSigFuncType" SG_ 1312 Airbag_02_CRC 2;
BA_ "GenSigSwitchedByIgnition" SG_ 1312 Airbag_02_CRC 0;
BA_ "GenSigSendType" SG_ 1312 LoGeWa_Event_Kombiwarnung 3;
BA_ "GenSigSwitchedByIgnition" SG_ 1312 LoGeWa_Event_Kombiwarnung 0;
BA_ "GenSigSendType" SG_ 1312 SC_PAO_OFF_Anf 0;
BA_ "GenSigSwitchedByIgnition" SG_ 1312 SC_PAO_OFF_Anf 0;
BA_ "GenSigSendType" SG_ 1312 SC_PAO_ON_Anf 0;
BA_ "GenSigSwitchedByIgnition" SG_ 1312 SC_PAO_ON_Anf 0;
BA_ "GenSigSendType" SG_ 1312 SC_PAO_Schriftzug_Anf 0;
BA_ "GenSigSwitchedByIgnition" SG_ 1312 SC_PAO_Schriftzug_Anf 0;
BA_ "GenSigSendType" SG_ 1349 AB_Gurtwarn_Reihe2_BF 3;
BA_ "GenSigSwitchedByIgnition" SG_ 1349 AB_Gurtwarn_Reihe2_BF 0;
BA_ "GenSigSendType" SG_ 1349 AB_Gurtwarn_Reihe2_FA 3;
BA_ "GenSigSwitchedByIgnition" SG_ 1349 AB_Gurtwarn_Reihe2_FA 0;
BA_ "GenSigSendType" SG_ 1349 AB_Gurtwarn_Reihe2_MI 3;
BA_ "GenSigSwitchedByIgnition" SG_ 1349 AB_Gurtwarn_Reihe2_MI 0;
BA_ "GenSigSendType" SG_ 1349 AB_Gurtwarn_Reihe3_BF 3;
BA_ "GenSigSwitchedByIgnition" SG_ 1349 AB_Gurtwarn_Reihe3_BF 0;
BA_ "GenSigSendType" SG_ 1349 AB_Gurtwarn_Reihe3_FA 3;
BA_ "GenSigSwitchedByIgnition" SG_ 1349 AB_Gurtwarn_Reihe3_FA 0;
BA_ "GenSigSendType" SG_ 1349 AB_Gurtwarn_Reihe3_MI 3;
BA_ "GenSigSwitchedByIgnition" SG_ 1349 AB_Gurtwarn_Reihe3_MI 0;
BA_ "GenSigSendType" SG_ 1349 AB_SBR_hinten_verbau 0;
BA_ "GenSigStartValue" SG_ 1349 AB_SBR_hinten_verbau 3;
BA_ "GenSigSwitchedByIgnition" SG_ 1349 AB_SBR_hinten_verbau 0;
BA_ "GenSigSendType" SG_ 1349 AbstWarn_MV_FAS_Fkt_Status 3;
BA_ "GenSigSwitchedByIgnition" SG_ 1349 AbstWarn_MV_FAS_Fkt_Status 0;
BA_ "Fehlerwert" SG_ 1349 AbstWarn_MV_FAS_Fkt_Status 3;
BA_ "GenSigSendType" SG_ 1349 AWV_Einstellung_System_ASG 3;
BA_ "GenSigSwitchedByIgnition" SG_ 1349 AWV_Einstellung_System_ASG 0;
BA_ "GenSigSendType" SG_ 1349 AWV_Einstellung_Warnung_ASG 3;
BA_ "GenSigSwitchedByIgnition" SG_ 1349 AWV_Einstellung_Warnung_ASG 0;
BA_ "GenSigSendType" SG_ 1349 LGI_FAS_Fkt_Status 3;
BA_ "GenSigSwitchedByIgnition" SG_ 1349 LGI_FAS_Fkt_Status 0;
BA_ "Fehlerwert" SG_ 1349 LGI_FAS_Fkt_Status 3;
BA_ "GenSigSendType" SG_ 1349 PreCrash_FAS_Fkt_Status 3;
BA_ "GenSigSwitchedByIgnition" SG_ 1349 PreCrash_FAS_Fkt_Status 0;
BA_ "Fehlerwert" SG_ 1349 PreCrash_FAS_Fkt_Status 3;
BA_ "GenSigSendType" SG_ 1349 SC_PreSense_Modus_System_KAS 3;
BA_ "GenSigSwitchedByIgnition" SG_ 1349 SC_PreSense_Modus_System_KAS 0;
BA_ "GenSigSendType" SG_ 1349 SC_PreSense_Modus_System_MV 3;
BA_ "GenSigSwitchedByIgnition" SG_ 1349 SC_PreSense_Modus_System_MV 0;
BA_ "GenSigSendType" SG_ 1349 SC_PreSense_Modus_System_NV 3;
BA_ "GenSigSwitchedByIgnition" SG_ 1349 SC_PreSense_Modus_System_NV 0;
BA_ "GenSigSendType" SG_ 1349 SC_PreSense_Modus_Warnung_MV 3;
BA_ "GenSigSwitchedByIgnition" SG_ 1349 SC_PreSense_Modus_Warnung_MV 0;
BA_ "GenSigSendType" SG_ 1349 SC_PreSense_Modus_Warnung_NV 3;
BA_ "GenSigSwitchedByIgnition" SG_ 1349 SC_PreSense_Modus_Warnung_NV 0;
BA_ "GenSigSendType" SG_ 1349 WarnBrems_Charisma_FahrPr 0;
BA_ "GenSigSendType" SG_ 1349 WarnBrems_Charisma_Status 0;
BA_ "GenSigSendType" SG_ 326 Airbag_05_BZ 0;
BA_ "GenSigFuncType" SG_ 326 Airbag_05_BZ 1;
BA_ "GenSigSwitchedByIgnition" SG_ 326 Airbag_05_BZ 0;
BA_ "GenSigSendType" SG_ 326 Airbag_05_CRC 0;
BA_ "GenSigFuncType" SG_ 326 Airbag_05_CRC 2;
BA_ "GenSigSwitchedByIgnition" SG_ 326 Airbag_05_CRC 0;
BA_ "GenSigSendType" SG_ 326 SC_FASIS_SyncCounter 0;
BA_ "GenSigStartValue" SG_ 326 SC_FASIS_SyncCounter 127;
BA_ "GenSigSwitchedByIgnition" SG_ 326 SC_FASIS_SyncCounter 0;
BA_ "GenSigSendType" SG_ 326 SC_QBit_FASIS_SyncCounter 0;
BA_ "GenSigStartValue" SG_ 326 SC_QBit_FASIS_SyncCounter 1;
BA_ "GenSigSwitchedByIgnition" SG_ 326 SC_QBit_FASIS_SyncCounter 0;
BA_ "Fehlerwert" SG_ 326 SC_QBit_FASIS_SyncCounter 1;
BA_ "GenSigSendType" SG_ 1633 AAG_Anhaenger_abgesteckt 0;
BA_ "GenSigSwitchedByIgnition" SG_ 1633 AAG_Anhaenger_abgesteckt 0;
BA_ "GenSigSendType" SG_ 1633 AAG_Anhaenger_erkannt 0;
BA_ "NWM-WakeupAllowed" SG_ 1633 AAG_Anhaenger_erkannt 1;
BA_ "GenSigSwitchedByIgnition" SG_ 1633 AAG_Anhaenger_erkannt 0;
BA_ "GenSigSendType" SG_ 1633 AAG_AVS_Fehler_02 0;
BA_ "GenSigSwitchedByIgnition" SG_ 1633 AAG_AVS_Fehler_02 0;
BA_ "Fehlerwert" SG_ 1633 AAG_AVS_Fehler_02 1;
BA_ "GenSigSendType" SG_ 1633 AAG_AVS_Fehler_02_inv 0;
BA_ "GenSigStartValue" SG_ 1633 AAG_AVS_Fehler_02_inv 1;
BA_ "GenSigSwitchedByIgnition" SG_ 1633 AAG_AVS_Fehler_02_inv 0;
BA_ "GenSigSendType" SG_ 1633 AAG_AVS_Stati 0;
BA_ "GenSigSwitchedByIgnition" SG_ 1633 AAG_AVS_Stati 0;
BA_ "GenSigSendType" SG_ 1633 AAG_Blinker_H_aktiv 0;
BA_ "GenSigSwitchedByIgnition" SG_ 1633 AAG_Blinker_H_aktiv 0;
BA_ "GenSigSendType" SG_ 1633 AAG_Blinker_HL_def 0;
BA_ "GenSigSwitchedByIgnition" SG_ 1633 AAG_Blinker_HL_def 0;
BA_ "GenSigSendType" SG_ 1633 AAG_Blinker_HR_def 0;
BA_ "GenSigSwitchedByIgnition" SG_ 1633 AAG_Blinker_HR_def 0;
BA_ "GenSigSendType" SG_ 1633 AAG_Bremsl_durch_ECD 0;
BA_ "GenSigSwitchedByIgnition" SG_ 1633 AAG_Bremsl_durch_ECD 0;
BA_ "GenSigSendType" SG_ 1633 AAG_Bremslicht_H_def 0;
BA_ "GenSigSwitchedByIgnition" SG_ 1633 AAG_Bremslicht_H_def 0;
BA_ "GenSigSendType" SG_ 1633 AAG_Bremslicht_Reku 0;
BA_ "GenSigSwitchedByIgnition" SG_ 1633 AAG_Bremslicht_Reku 0;
BA_ "GenSigSendType" SG_ 1633 AAG_BZ 0;
BA_ "GenSigFuncType" SG_ 1633 AAG_BZ 1;
BA_ "GenSigSwitchedByIgnition" SG_ 1633 AAG_BZ 0;
BA_ "GenSigSendType" SG_ 1633 AAG_LED_aktiv 0;
BA_ "GenSigSwitchedByIgnition" SG_ 1633 AAG_LED_aktiv 0;
BA_ "GenSigSendType" SG_ 1633 AAG_NSL_aktiv 0;
BA_ "GenSigSwitchedByIgnition" SG_ 1633 AAG_NSL_aktiv 0;
BA_ "GenSigSendType" SG_ 1633 AAG_Schlusslicht_HL_def 0;
BA_ "GenSigSwitchedByIgnition" SG_ 1633 AAG_Schlusslicht_HL_def 0;
BA_ "GenSigSendType" SG_ 1633 AAG_Schlusslicht_HR_def 0;
BA_ "GenSigSwitchedByIgnition" SG_ 1633 AAG_Schlusslicht_HR_def 0;
BA_ "GenSigActiveRepetitions" SG_ 348 ARA_Sensor_02_red_cyclic 5;
BA_ "GenSigSendType" SG_ 348 ARA_Sensor_02_red_cyclic 6;
BA_ "GenSigSendType" SG_ 348 ARA_Sensor_dt_Botschaft 0;
BA_ "GenSigSendType" SG_ 348 ARA_Sensor_Knickw_Rohwert_BV 0;
BA_ "GenSigStartValue" SG_ 348 ARA_Sensor_Knickw_Rohwert_BV 65534;
BA_ "Fehlerwert" SG_ 348 ARA_Sensor_Knickw_Rohwert_BV 65535;
BA_ "GenSigSendType" SG_ 348 ARA_Sensor_Qualitaet_Grund 0;
BA_ "GenSigSendType" SG_ 348 ARA_Sensor_Qualitaet_Wert 0;
BA_ "GenSigSendType" SG_ 348 ARA_Sensor_Status 0;
BA_ "GenSigSendType" SG_ 348 ARA_Sensor_Zeitstempel_BV 0;
BA_ "GenSigSendType" SG_ 345 ARA_Aktiver_Grafikmodus 3;
BA_ "GenSigSendType" SG_ 345 ARA_Bremsfuss 3;
BA_ "GenSigSendType" SG_ 345 ARA_Deaktivierung_sperren 3;
BA_ "GenSigSendType" SG_ 345 ARA_Knickwinkel_Ist 3;
BA_ "GenSigStartValue" SG_ 345 ARA_Knickwinkel_Ist 254;
BA_ "Fehlerwert" SG_ 345 ARA_Knickwinkel_Ist 255;
BA_ "GenSigSendType" SG_ 345 ARA_Knickwinkel_Komfort 3;
BA_ "GenSigStartValue" SG_ 345 ARA_Knickwinkel_Komfort 62;
BA_ "Fehlerwert" SG_ 345 ARA_Knickwinkel_Komfort 63;
BA_ "GenSigSendType" SG_ 345 ARA_Knickwinkel_Konfidenz 3;
BA_ "GenSigStartValue" SG_ 345 ARA_Knickwinkel_Konfidenz 126;
BA_ "Fehlerwert" SG_ 345 ARA_Knickwinkel_Konfidenz 127;
BA_ "GenSigSendType" SG_ 345 ARA_Knickwinkel_Max 3;
BA_ "GenSigStartValue" SG_ 345 ARA_Knickwinkel_Max 126;
BA_ "Fehlerwert" SG_ 345 ARA_Knickwinkel_Max 127;
BA_ "GenSigSendType" SG_ 345 ARA_Knickwinkel_Soll 3;
BA_ "GenSigStartValue" SG_ 345 ARA_Knickwinkel_Soll 254;
BA_ "Fehlerwert" SG_ 345 ARA_Knickwinkel_Soll 255;
BA_ "GenSigSendType" SG_ 345 ARA_Modus 3;
BA_ "GenSigSendType" SG_ 345 ARA_Modus_Anf 3;
BA_ "GenSigSendType" SG_ 345 ARA_Sensor_Aktivierung 3;
BA_ "GenSigSendType" SG_ 345 ARA_Status 3;
BA_ "GenSigStartValue" SG_ 345 ARA_Status 1;
BA_ "Fehlerwert" SG_ 345 ARA_Status 2;
BA_ "GenSigSendType" SG_ 345 ARA_Texte 3;
BA_ "Fehlerwert" SG_ 345 ARA_Texte 63;
BA_ "GenSigSendType" SG_ 1013 ARA_nachtr_Stopp_Anf 0;
BA_ "GenSigSendType" SG_ 1013 ARA_StartStopp_Info 0;
BA_ "GenSigSendType" SG_ 1013 ARA_Verw_Zeitstempel_BV 0;
BA_ "GenSigSendType" SG_ 1013 ARA_Weg_abs 0;
BA_ "GenSigSendType" SG_ 1013 ARA_Winkel_abs 0;
BA_ "GenSigSendType" SG_ 1013 ARA_Winkel_logInnovation 0;
BA_ "GenSigSendType" SG_ 1013 ARA_Winkel_logVarianz 0;
BA_ "GenSigSendType" SG_ 2536767264 BAP_Debug_Cmd 3;
BA_ "GenSigSwitchedByIgnition" SG_ 2536767264 BAP_Debug_Cmd 0;
BA_ "GenSigSendType" SG_ 2536767280 BAP_Debug_Data 3;
BA_ "GenSigSendType" SG_ 2536708096 BAP_Nightvision_ASG_01_Header 3;
BA_ "GenSigSwitchedByIgnition" SG_ 2536708096 BAP_Nightvision_ASG_01_Header 0;
BA_ "GenSigSendType" SG_ 2536708097 BAP_Nightvision_ASG_02_Header 3;
BA_ "GenSigSwitchedByIgnition" SG_ 2536708097 BAP_Nightvision_ASG_02_Header 0;
BA_ "GenSigSendType" SG_ 2536708112 BAP_Nightvision_FSG_01_Header 3;
BA_ "GenSigSendType" SG_ 2536704513 BAP_OPS_ASG_02_Header 3;
BA_ "GenSigSwitchedByIgnition" SG_ 2536704513 BAP_OPS_ASG_02_Header 0;
BA_ "GenSigSendType" SG_ 2536704528 BAP_OPS_FSG_01_Header 3;
BA_ "GenSigSwitchedByIgnition" SG_ 2536704528 BAP_OPS_FSG_01_Header 0;
BA_ "GenSigSendType" SG_ 2536704529 BAP_OPS_FSG_02_Header 3;
BA_ "GenSigSwitchedByIgnition" SG_ 2536704529 BAP_OPS_FSG_02_Header 0;
BA_ "GenSigSendType" SG_ 2536703744 BAP_RDK_ASG_01_Header 3;
BA_ "GenSigSwitchedByIgnition" SG_ 2536703744 BAP_RDK_ASG_01_Header 0;
BA_ "GenSigSendType" SG_ 2536703745 BAP_RDK_ASG_02_Header 3;
BA_ "GenSigSwitchedByIgnition" SG_ 2536703745 BAP_RDK_ASG_02_Header 0;
BA_ "GenSigSendType" SG_ 2536703746 BAP_RDK_ASG_03_Header 3;
BA_ "GenSigSwitchedByIgnition" SG_ 2536703746 BAP_RDK_ASG_03_Header 0;
BA_ "GenSigSendType" SG_ 2536703760 BAP_RDK_FSG_01_Header 3;
BA_ "GenSigSwitchedByIgnition" SG_ 2536703760 BAP_RDK_FSG_01_Header 0;
BA_ "GenSigSendType" SG_ 2536704768 BAP_RVC_ASG_01_Header 3;
BA_ "GenSigSwitchedByIgnition" SG_ 2536704768 BAP_RVC_ASG_01_Header 0;
BA_ "GenSigSendType" SG_ 2536704784 BAP_RVC_FSG_01_Header 3;
BA_ "GenSigSwitchedByIgnition" SG_ 2536704784 BAP_RVC_FSG_01_Header 0;
BA_ "GenSigSendType" SG_ 2536728064 BAP_SoundControl2_ASG_01_Header 3;
BA_ "GenSigSwitchedByIgnition" SG_ 2536728064 BAP_SoundControl2_ASG_01_Header 0;
BA_ "GenSigSendType" SG_ 2536728080 BAP_SoundControl2_FSG_01_Header 3;
BA_ "GenSigSwitchedByIgnition" SG_ 2536728080 BAP_SoundControl2_FSG_01_Header 0;
BA_ "GenSigSendType" SG_ 2536719360 BAP_SoundControl_ASG_01_Header 3;
BA_ "GenSigSwitchedByIgnition" SG_ 2536719360 BAP_SoundControl_ASG_01_Header 0;
BA_ "GenSigSendType" SG_ 2536719376 BAP_SoundControl_FSG_01_Header 3;
BA_ "GenSigSendType" SG_ 2536708608 BAP_SWA_ASG_01_Header 3;
BA_ "GenSigSwitchedByIgnition" SG_ 2536708608 BAP_SWA_ASG_01_Header 0;
BA_ "GenSigSendType" SG_ 2536708609 BAP_SWA_ASG_02_Header 3;
BA_ "GenSigSwitchedByIgnition" SG_ 2536708609 BAP_SWA_ASG_02_Header 0;
BA_ "GenSigSendType" SG_ 2536708624 BAP_SWA_FSG_01_Header 3;
BA_ "GenSigSendType" SG_ 1626 APS_Tongeber_defekt 3;
BA_ "GenSigSwitchedByIgnition" SG_ 1626 APS_Tongeber_defekt 0;
BA_ "GenSigSendType" SG_ 1626 BCM1_AFS_Lampe 3;
BA_ "GenSigSwitchedByIgnition" SG_ 1626 BCM1_AFS_Lampe 0;
BA_ "GenSigSendType" SG_ 1626 BCM1_EasyEntry_Status 3;
BA_ "GenSigSwitchedByIgnition" SG_ 1626 BCM1_EasyEntry_Status 0;
BA_ "GenSigSendType" SG_ 1626 BCM1_Fahrlicht_Hinweis 3;
BA_ "GenSigSwitchedByIgnition" SG_ 1626 BCM1_Fahrlicht_Hinweis 0;
BA_ "GenSigSendType" SG_ 1626 BCM1_Hinweis_Lichtnachlauf 3;
BA_ "GenSigSwitchedByIgnition" SG_ 1626 BCM1_Hinweis_Lichtnachlauf 0;
BA_ "GenSigSendType" SG_ 1626 BCM1_Kl_15_HW_erkannt 3;
BA_ "GenSigSwitchedByIgnition" SG_ 1626 BCM1_Kl_15_HW_erkannt 0;
BA_ "GenSigSendType" SG_ 1626 BCM1_Kl_15_Sig_HW_erkannt 3;
BA_ "GenSigSwitchedByIgnition" SG_ 1626 BCM1_Kl_15_Sig_HW_erkannt 0;
BA_ "GenSigSendType" SG_ 1626 BCM1_LDS_Stellung 3;
BA_ "GenSigSwitchedByIgnition" SG_ 1626 BCM1_LDS_Stellung 0;
BA_ "Fehlerwert" SG_ 1626 BCM1_LDS_Stellung 7;
BA_ "GenSigSendType" SG_ 1626 BCM1_Lenksaeule_aktiv 3;
BA_ "GenSigSwitchedByIgnition" SG_ 1626 BCM1_Lenksaeule_aktiv 0;
BA_ "GenSigSendType" SG_ 1626 BCM1_Licht_Warn 3;
BA_ "GenSigSwitchedByIgnition" SG_ 1626 BCM1_Licht_Warn 0;
BA_ "GenSigSendType" SG_ 1626 BCM1_Lichtwarn_Texte 3;
BA_ "GenSigSwitchedByIgnition" SG_ 1626 BCM1_Lichtwarn_Texte 0;
BA_ "GenSigSendType" SG_ 1626 BCM1_MH_Schalter 3;
BA_ "GenSigSwitchedByIgnition" SG_ 1626 BCM1_MH_Schalter 0;
BA_ "GenSigSendType" SG_ 1626 BCM1_MH_WIV_Schalter 3;
BA_ "GenSigSwitchedByIgnition" SG_ 1626 BCM1_MH_WIV_Schalter 0;
BA_ "GenSigActiveRepetitions" SG_ 1626 BCM1_NV_Taster 10;
BA_ "GenSigSendType" SG_ 1626 BCM1_NV_Taster 4;
BA_ "GenSigSwitchedByIgnition" SG_ 1626 BCM1_NV_Taster 0;
BA_ "GenSigSendType" SG_ 1626 BCM1_Reisemodus_Texte 3;
BA_ "GenSigSwitchedByIgnition" SG_ 1626 BCM1_Reisemodus_Texte 0;
BA_ "GenSigSendType" SG_ 1626 BCM1_Rueckfahrlicht_Schalter 3;
BA_ "GenSigSwitchedByIgnition" SG_ 1626 BCM1_Rueckfahrlicht_Schalter 0;
BA_ "GenSigSendType" SG_ 1626 BCM1_Schluesselsuche_Anf 0;
BA_ "GenSigSwitchedByIgnition" SG_ 1626 BCM1_Schluesselsuche_Anf 0;
BA_ "GenSigSendType" SG_ 1626 BCM1_St_SW_Diebstahl_links 3;
BA_ "GenSigSwitchedByIgnition" SG_ 1626 BCM1_St_SW_Diebstahl_links 0;
BA_ "GenSigSendType" SG_ 1626 BCM1_St_SW_Diebstahl_rechts 3;
BA_ "GenSigSwitchedByIgnition" SG_ 1626 BCM1_St_SW_Diebstahl_rechts 0;
BA_ "GenSigActiveRepetitions" SG_ 1626 BCM1_Valet_Parking_Taster 10;
BA_ "GenSigSendType" SG_ 1626 BCM1_Valet_Parking_Taster 4;
BA_ "GenSigSwitchedByIgnition" SG_ 1626 BCM1_Valet_Parking_Taster 0;
BA_ "GenSigActiveRepetitions" SG_ 1626 BCM1_Warnblink_Taster 10;
BA_ "GenSigSendType" SG_ 1626 BCM1_Warnblink_Taster 4;
BA_ "GenSigSwitchedByIgnition" SG_ 1626 BCM1_Warnblink_Taster 0;
BA_ "GenSigSendType" SG_ 1626 BCM_Bremsbelag_Sensor 3;
BA_ "GenSigSwitchedByIgnition" SG_ 1626 BCM_Bremsbelag_Sensor 0;
BA_ "GenSigSendType" SG_ 1626 BCM_Bremsfluessigkeit_Sensor 3;
BA_ "GenSigSwitchedByIgnition" SG_ 1626 BCM_Bremsfluessigkeit_Sensor 0;
BA_ "GenSigSendType" SG_ 1626 BCM_Eco_Charisma_Taste 3;
BA_ "GenSigSwitchedByIgnition" SG_ 1626 BCM_Eco_Charisma_Taste 0;
BA_ "GenSigSendType" SG_ 1626 BCM_HDF_betaetigt 3;
BA_ "GenSigSwitchedByIgnition" SG_ 1626 BCM_HDF_betaetigt 0;
BA_ "GenSigActiveRepetitions" SG_ 1626 BCM_Hybrid_StartStopp_Taste 10;
BA_ "GenSigSendType" SG_ 1626 BCM_Hybrid_StartStopp_Taste 4;
BA_ "GenSigSwitchedByIgnition" SG_ 1626 BCM_Hybrid_StartStopp_Taste 0;
BA_ "GenSigSendType" SG_ 1626 BCM_Hybrid_StSt_Taste_Fehler 0;
BA_ "GenSigSwitchedByIgnition" SG_ 1626 BCM_Hybrid_StSt_Taste_Fehler 0;
BA_ "GenSigSendType" SG_ 1626 BCM_Kuehlmittel_Sensor 3;
BA_ "GenSigSwitchedByIgnition" SG_ 1626 BCM_Kuehlmittel_Sensor 0;
BA_ "GenSigSendType" SG_ 1626 BCM_Kuehlmittel_Sensor_02 3;
BA_ "GenSigSwitchedByIgnition" SG_ 1626 BCM_Kuehlmittel_Sensor_02 0;
BA_ "GenSigSendType" SG_ 1626 BCM_Offroad_Taste 3;
BA_ "GenSigSwitchedByIgnition" SG_ 1626 BCM_Offroad_Taste 0;
BA_ "GenSigSendType" SG_ 1626 BCM_Waschwasser_Sensor 3;
BA_ "GenSigSwitchedByIgnition" SG_ 1626 BCM_Waschwasser_Sensor 0;
BA_ "GenSigSendType" SG_ 1626 Gong_TFL_Umschaltung 3;
BA_ "GenSigSwitchedByIgnition" SG_ 1626 Gong_TFL_Umschaltung 0;
BA_ "GenSigSendType" SG_ 1626 ISP_Dimmung_ASP_02 3;
BA_ "GenSigSendType" SG_ 1626 UGDO_Function_01 3;
BA_ "Fehlerwert" SG_ 1626 UGDO_Function_01 7;
BA_ "GenSigSendType" SG_ 2527679637 BCM_LTM_Allwetterl_Status 3;
BA_ "GenSigSwitchedByIgnition" SG_ 2527679637 BCM_LTM_Allwetterl_Status 0;
BA_ "GenSigSendType" SG_ 2527679637 BCM_LTM_Nebell_Status 3;
BA_ "GenSigSwitchedByIgnition" SG_ 2527679637 BCM_LTM_Nebell_Status 0;
BA_ "GenSigSendType" SG_ 2527679637 BCM_LTM_Nebelschluss_Status 3;
BA_ "GenSigSwitchedByIgnition" SG_ 2527679637 BCM_LTM_Nebelschluss_Status 0;
BA_ "GenSigSendType" SG_ 2527679637 BCM_LTM_PopUp_Anf 3;
BA_ "GenSigSwitchedByIgnition" SG_ 2527679637 BCM_LTM_PopUp_Anf 0;
BA_ "GenSigSendType" SG_ 2527679637 BCM_LTM_PopUp_Inhalt 3;
BA_ "GenSigSwitchedByIgnition" SG_ 2527679637 BCM_LTM_PopUp_Inhalt 0;
BA_ "GenSigSendType" SG_ 2527679637 BCM_LTM_PopUp_Status 3;
BA_ "GenSigSwitchedByIgnition" SG_ 2527679637 BCM_LTM_PopUp_Status 0;
BA_ "GenSigSendType" SG_ 2527679637 BCM_LTM_PopUp_Texte 3;
BA_ "GenSigSwitchedByIgnition" SG_ 2527679637 BCM_LTM_PopUp_Texte 0;
BA_ "GenSigSendType" SG_ 2527679637 CPD_Warnung 3;
BA_ "GenSigSwitchedByIgnition" SG_ 2527679637 CPD_Warnung 0;
BA_ "GenSigActiveRepetitions" SG_ 961 APS_LED_Status 5;
BA_ "GenSigSendType" SG_ 961 APS_LED_Status 4;
BA_ "GenSigSwitchedByIgnition" SG_ 961 APS_LED_Status 0;
BA_ "Fehlerwert" SG_ 961 APS_LED_Status 3;
BA_ "GenSigActiveRepetitions" SG_ 961 APS_Taster 5;
BA_ "GenSigSendType" SG_ 961 APS_Taster 4;
BA_ "GenSigStartValue" SG_ 961 APS_Taster 2;
BA_ "GenSigSwitchedByIgnition" SG_ 961 APS_Taster 0;
BA_ "Fehlerwert" SG_ 961 APS_Taster 3;
BA_ "GenSigActiveRepetitions" SG_ 961 AVH_LED_Status 5;
BA_ "GenSigSendType" SG_ 961 AVH_LED_Status 4;
BA_ "GenSigSwitchedByIgnition" SG_ 961 AVH_LED_Status 0;
BA_ "Fehlerwert" SG_ 961 AVH_LED_Status 3;
BA_ "GenSigActiveRepetitions" SG_ 961 AVH_Taster 5;
BA_ "GenSigSendType" SG_ 961 AVH_Taster 4;
BA_ "GenSigStartValue" SG_ 961 AVH_Taster 2;
BA_ "GenSigSwitchedByIgnition" SG_ 961 AVH_Taster 0;
BA_ "Fehlerwert" SG_ 961 AVH_Taster 3;
BA_ "GenSigActiveRepetitions" SG_ 961 Display_Taster 5;
BA_ "GenSigSendType" SG_ 961 Display_Taster 4;
BA_ "GenSigStartValue" SG_ 961 Display_Taster 2;
BA_ "GenSigSwitchedByIgnition" SG_ 961 Display_Taster 0;
BA_ "Fehlerwert" SG_ 961 Display_Taster 3;
BA_ "GenSigActiveRepetitions" SG_ 961 Drivesel_1_Taster 5;
BA_ "GenSigSendType" SG_ 961 Drivesel_1_Taster 4;
BA_ "GenSigStartValue" SG_ 961 Drivesel_1_Taster 2;
BA_ "GenSigSwitchedByIgnition" SG_ 961 Drivesel_1_Taster 0;
BA_ "Fehlerwert" SG_ 961 Drivesel_1_Taster 3;
BA_ "GenSigActiveRepetitions" SG_ 961 Drivesel_2_Taster 5;
BA_ "GenSigSendType" SG_ 961 Drivesel_2_Taster 4;
BA_ "GenSigStartValue" SG_ 961 Drivesel_2_Taster 2;
BA_ "GenSigSwitchedByIgnition" SG_ 961 Drivesel_2_Taster 0;
BA_ "Fehlerwert" SG_ 961 Drivesel_2_Taster 3;
BA_ "GenSigActiveRepetitions" SG_ 961 eCall_Taste 5;
BA_ "GenSigSendType" SG_ 961 eCall_Taste 4;
BA_ "GenSigSwitchedByIgnition" SG_ 961 eCall_Taste 0;
BA_ "Fehlerwert" SG_ 961 eCall_Taste 3;
BA_ "GenSigActiveRepetitions" SG_ 961 ESP_Off_Taster 5;
BA_ "GenSigSendType" SG_ 961 ESP_Off_Taster 4;
BA_ "GenSigStartValue" SG_ 961 ESP_Off_Taster 2;
BA_ "GenSigSwitchedByIgnition" SG_ 961 ESP_Off_Taster 0;
BA_ "Fehlerwert" SG_ 961 ESP_Off_Taster 3;
BA_ "GenSigActiveRepetitions" SG_ 961 HDC_LED_Status 5;
BA_ "GenSigSendType" SG_ 961 HDC_LED_Status 4;
BA_ "GenSigSwitchedByIgnition" SG_ 961 HDC_LED_Status 0;
BA_ "Fehlerwert" SG_ 961 HDC_LED_Status 3;
BA_ "GenSigActiveRepetitions" SG_ 961 HDC_Taster 5;
BA_ "GenSigSendType" SG_ 961 HDC_Taster 4;
BA_ "GenSigStartValue" SG_ 961 HDC_Taster 2;
BA_ "GenSigSwitchedByIgnition" SG_ 961 HDC_Taster 0;
BA_ "Fehlerwert" SG_ 961 HDC_Taster 3;
BA_ "GenSigActiveRepetitions" SG_ 961 Heckrollo_2_Taster 5;
BA_ "GenSigSendType" SG_ 961 Heckrollo_2_Taster 4;
BA_ "GenSigStartValue" SG_ 961 Heckrollo_2_Taster 2;
BA_ "GenSigSwitchedByIgnition" SG_ 961 Heckrollo_2_Taster 0;
BA_ "Fehlerwert" SG_ 961 Heckrollo_2_Taster 3;
BA_ "GenSigActiveRepetitions" SG_ 961 Heckrollo_Taster 5;
BA_ "GenSigSendType" SG_ 961 Heckrollo_Taster 4;
BA_ "GenSigStartValue" SG_ 961 Heckrollo_Taster 2;
BA_ "GenSigSwitchedByIgnition" SG_ 961 Heckrollo_Taster 0;
BA_ "Fehlerwert" SG_ 961 Heckrollo_Taster 3;
BA_ "GenSigActiveRepetitions" SG_ 961 LIM_bCall_Taster 5;
BA_ "GenSigSendType" SG_ 961 LIM_bCall_Taster 4;
BA_ "GenSigSwitchedByIgnition" SG_ 961 LIM_bCall_Taster 0;
BA_ "GenSigSendType" SG_ 961 LIM_PAO_Alivesignal 3;
BA_ "GenSigSwitchedByIgnition" SG_ 961 LIM_PAO_Alivesignal 0;
BA_ "GenSigSendType" SG_ 961 LIM_PAO_OFF_Status 3;
BA_ "GenSigSwitchedByIgnition" SG_ 961 LIM_PAO_OFF_Status 0;
BA_ "GenSigSendType" SG_ 961 LIM_PAO_ON_Status 3;
BA_ "GenSigSwitchedByIgnition" SG_ 961 LIM_PAO_ON_Status 0;
BA_ "GenSigSendType" SG_ 961 LIM_PAO_Schriftzug_Status 3;
BA_ "GenSigSwitchedByIgnition" SG_ 961 LIM_PAO_Schriftzug_Status 0;
BA_ "GenSigActiveRepetitions" SG_ 961 LKS_Taster 5;
BA_ "GenSigSendType" SG_ 961 LKS_Taster 4;
BA_ "GenSigStartValue" SG_ 961 LKS_Taster 2;
BA_ "GenSigSwitchedByIgnition" SG_ 961 LKS_Taster 0;
BA_ "Fehlerwert" SG_ 961 LKS_Taster 3;
BA_ "GenSigActiveRepetitions" SG_ 961 PLA_LED_Status 5;
BA_ "GenSigSendType" SG_ 961 PLA_LED_Status 4;
BA_ "GenSigSwitchedByIgnition" SG_ 961 PLA_LED_Status 0;
BA_ "Fehlerwert" SG_ 961 PLA_LED_Status 3;
BA_ "GenSigActiveRepetitions" SG_ 961 PLA_Taster 5;
BA_ "GenSigSendType" SG_ 961 PLA_Taster 4;
BA_ "GenSigStartValue" SG_ 961 PLA_Taster 2;
BA_ "GenSigSwitchedByIgnition" SG_ 961 PLA_Taster 0;
BA_ "Fehlerwert" SG_ 961 PLA_Taster 3;
BA_ "GenSigSendType" SG_ 961 PLA_Taster_Fehler_Roh 3;
BA_ "GenSigSwitchedByIgnition" SG_ 961 PLA_Taster_Fehler_Roh 0;
BA_ "GenSigActiveRepetitions" SG_ 961 Sideview_Taster 5;
BA_ "GenSigSendType" SG_ 961 Sideview_Taster 4;
BA_ "GenSigStartValue" SG_ 961 Sideview_Taster 2;
BA_ "GenSigSwitchedByIgnition" SG_ 961 Sideview_Taster 0;
BA_ "Fehlerwert" SG_ 961 Sideview_Taster 3;
BA_ "GenSigActiveRepetitions" SG_ 961 Spoiler_LED_Status 5;
BA_ "GenSigSendType" SG_ 961 Spoiler_LED_Status 4;
BA_ "GenSigSwitchedByIgnition" SG_ 961 Spoiler_LED_Status 0;
BA_ "Fehlerwert" SG_ 961 Spoiler_LED_Status 3;
BA_ "GenSigActiveRepetitions" SG_ 961 Spoiler_Taster 5;
BA_ "GenSigSendType" SG_ 961 Spoiler_Taster 4;
BA_ "GenSigStartValue" SG_ 961 Spoiler_Taster 2;
BA_ "GenSigSwitchedByIgnition" SG_ 961 Spoiler_Taster 0;
BA_ "Fehlerwert" SG_ 961 Spoiler_Taster 3;
BA_ "GenSigActiveRepetitions" SG_ 961 SWA_Taster 5;
BA_ "GenSigSendType" SG_ 961 SWA_Taster 4;
BA_ "GenSigSwitchedByIgnition" SG_ 961 SWA_Taster 0;
BA_ "Fehlerwert" SG_ 961 SWA_Taster 3;
BA_ "GenSigSendType" SG_ 1432 BCM1_eSound_Taster 3;
BA_ "GenSigStartValue" SG_ 1432 BCM1_eSound_Taster 2;
BA_ "GenSigSwitchedByIgnition" SG_ 1432 BCM1_eSound_Taster 0;
BA_ "Fehlerwert" SG_ 1432 BCM1_eSound_Taster 3;
BA_ "GenSigActiveRepetitions" SG_ 1432 BCM1_NR_Ride_Height_Down_Taster 5;
BA_ "GenSigSendType" SG_ 1432 BCM1_NR_Ride_Height_Down_Taster 4;
BA_ "GenSigStartValue" SG_ 1432 BCM1_NR_Ride_Height_Down_Taster 2;
BA_ "GenSigSwitchedByIgnition" SG_ 1432 BCM1_NR_Ride_Height_Down_Taster 0;
BA_ "Fehlerwert" SG_ 1432 BCM1_NR_Ride_Height_Down_Taster 3;
BA_ "GenSigActiveRepetitions" SG_ 1432 BCM1_NR_Ride_Height_Up_Taster 5;
BA_ "GenSigSendType" SG_ 1432 BCM1_NR_Ride_Height_Up_Taster 4;
BA_ "GenSigStartValue" SG_ 1432 BCM1_NR_Ride_Height_Up_Taster 2;
BA_ "GenSigSwitchedByIgnition" SG_ 1432 BCM1_NR_Ride_Height_Up_Taster 0;
BA_ "Fehlerwert" SG_ 1432 BCM1_NR_Ride_Height_Up_Taster 3;
BA_ "GenSigSendType" SG_ 1432 BCM_BFS_Fernsteuerung_aktiv 3;
BA_ "GenSigSwitchedByIgnition" SG_ 1432 BCM_BFS_Fernsteuerung_aktiv 0;
BA_ "GenSigSendType" SG_ 1432 BCM_BFS_Massage_Taster 3;
BA_ "GenSigSwitchedByIgnition" SG_ 1432 BCM_BFS_Massage_Taster 0;
BA_ "GenSigSendType" SG_ 1432 BCM_BFS_Multif_Taster 3;
BA_ "GenSigSwitchedByIgnition" SG_ 1432 BCM_BFS_Multif_Taster 0;
BA_ "GenSigSendType" SG_ 1432 BCM_BFS_Pneumatik_Verstellung 3;
BA_ "GenSigSwitchedByIgnition" SG_ 1432 BCM_BFS_Pneumatik_Verstellung 0;
BA_ "GenSigSendType" SG_ 1432 BCM_BFS_Programmwippe 3;
BA_ "GenSigSwitchedByIgnition" SG_ 1432 BCM_BFS_Programmwippe 0;
BA_ "GenSigSendType" SG_ 1432 BCM_FS_Massage_Taster 3;
BA_ "GenSigSwitchedByIgnition" SG_ 1432 BCM_FS_Massage_Taster 0;
BA_ "GenSigSendType" SG_ 1432 BCM_FS_Multif_Taster 3;
BA_ "GenSigSwitchedByIgnition" SG_ 1432 BCM_FS_Multif_Taster 0;
BA_ "GenSigSendType" SG_ 1432 BCM_FS_Pneumatik_Verstellung 3;
BA_ "GenSigSwitchedByIgnition" SG_ 1432 BCM_FS_Pneumatik_Verstellung 0;
BA_ "GenSigSendType" SG_ 1432 BCM_FS_Programmwippe 3;
BA_ "GenSigSwitchedByIgnition" SG_ 1432 BCM_FS_Programmwippe 0;
BA_ "GenSigActiveRepetitions" SG_ 1432 BCM_Soundklappe_Taster 5;
BA_ "GenSigSendType" SG_ 1432 BCM_Soundklappe_Taster 4;
BA_ "GenSigSwitchedByIgnition" SG_ 1432 BCM_Soundklappe_Taster 0;
BA_ "GenSigSendType" SG_ 1432 E_Sound_LED_Status 3;
BA_ "GenSigSwitchedByIgnition" SG_ 1432 E_Sound_LED_Status 0;
BA_ "Fehlerwert" SG_ 1432 E_Sound_LED_Status 3;
BA_ "GenSigActiveRepetitions" SG_ 1432 LIM_Rear_Mode 5;
BA_ "GenSigSendType" SG_ 1432 LIM_Rear_Mode 4;
BA_ "GenSigSwitchedByIgnition" SG_ 1432 LIM_Rear_Mode 0;
BA_ "GenSigActiveRepetitions" SG_ 1432 LIM_S_Rollo_hi 5;
BA_ "GenSigSendType" SG_ 1432 LIM_S_Rollo_hi 4;
BA_ "GenSigSwitchedByIgnition" SG_ 1432 LIM_S_Rollo_hi 0;
BA_ "GenSigActiveRepetitions" SG_ 1432 LIM_S_Rollo_vo 5;
BA_ "GenSigSendType" SG_ 1432 LIM_S_Rollo_vo 4;
BA_ "GenSigSwitchedByIgnition" SG_ 1432 LIM_S_Rollo_vo 0;
BA_ "GenSigActiveRepetitions" SG_ 1432 LIM_S_SAD_hi 5;
BA_ "GenSigSendType" SG_ 1432 LIM_S_SAD_hi 4;
BA_ "GenSigSwitchedByIgnition" SG_ 1432 LIM_S_SAD_hi 0;
BA_ "GenSigActiveRepetitions" SG_ 1432 LIM_S_SAD_Vo 5;
BA_ "GenSigSendType" SG_ 1432 LIM_S_SAD_Vo 4;
BA_ "GenSigSwitchedByIgnition" SG_ 1432 LIM_S_SAD_Vo 0;
BA_ "GenSigSendType" SG_ 1432 Pilot_Taster 3;
BA_ "GenSigStartValue" SG_ 1432 Pilot_Taster 2;
BA_ "GenSigSwitchedByIgnition" SG_ 1432 Pilot_Taster 0;
BA_ "Fehlerwert" SG_ 1432 Pilot_Taster 3;
BA_ "GenSigFuncType" SG_ 2617189888 CCP_AGA_CRO_01_Data 9;
BA_ "GenSigSwitchedByIgnition" SG_ 2617189888 CCP_AGA_CRO_01_Data 0;
BA_ "GenSigFuncType" SG_ 2617189889 CCP_AGA_DTO_01_Data 9;
BA_ "GenSigFuncType" SG_ 2617042432 CCP_Soundaktor_CRO_01_Data 9;
BA_ "GenSigSwitchedByIgnition" SG_ 2617042432 CCP_Soundaktor_CRO_01_Data 0;
BA_ "GenSigFuncType" SG_ 2617042433 CCP_Soundaktor_DTO_01_Data 9;
BA_ "GenSigSendType" SG_ 901 CHA_Fahrer_Umschaltung 3;
BA_ "GenSigSwitchedByIgnition" SG_ 901 CHA_Fahrer_Umschaltung 0;
BA_ "GenSigSendType" SG_ 901 CHA_Fahrer_Umschaltung_BMA 3;
BA_ "GenSigSwitchedByIgnition" SG_ 901 CHA_Fahrer_Umschaltung_BMA 0;
BA_ "GenSigSendType" SG_ 901 CHA_Ziel_FahrPr_ACC 3;
BA_ "GenSigSwitchedByIgnition" SG_ 901 CHA_Ziel_FahrPr_ACC 0;
BA_ "GenSigSendType" SG_ 901 CHA_Ziel_FahrPr_AFS 3;
BA_ "GenSigSwitchedByIgnition" SG_ 901 CHA_Ziel_FahrPr_AFS 0;
BA_ "GenSigSendType" SG_ 901 CHA_Ziel_FahrPr_AGA 3;
BA_ "GenSigSwitchedByIgnition" SG_ 901 CHA_Ziel_FahrPr_AGA 0;
BA_ "GenSigSendType" SG_ 901 CHA_Ziel_FahrPr_ALR 3;
BA_ "GenSigSwitchedByIgnition" SG_ 901 CHA_Ziel_FahrPr_ALR 0;
BA_ "GenSigSendType" SG_ 901 CHA_Ziel_FahrPr_DR 3;
BA_ "GenSigSwitchedByIgnition" SG_ 901 CHA_Ziel_FahrPr_DR 0;
BA_ "GenSigSendType" SG_ 901 CHA_Ziel_FahrPr_EPS 3;
BA_ "GenSigSwitchedByIgnition" SG_ 901 CHA_Ziel_FahrPr_EPS 0;
BA_ "GenSigSendType" SG_ 901 CHA_Ziel_FahrPr_ESP 3;
BA_ "GenSigSwitchedByIgnition" SG_ 901 CHA_Ziel_FahrPr_ESP 0;
BA_ "GenSigSendType" SG_ 901 CHA_Ziel_FahrPr_Freilauf 3;
BA_ "GenSigSwitchedByIgnition" SG_ 901 CHA_Ziel_FahrPr_Freilauf 0;
BA_ "GenSigSendType" SG_ 901 CHA_Ziel_FahrPr_GE 3;
BA_ "GenSigSwitchedByIgnition" SG_ 901 CHA_Ziel_FahrPr_GE 0;
BA_ "GenSigSendType" SG_ 901 CHA_Ziel_FahrPr_MO 3;
BA_ "GenSigSwitchedByIgnition" SG_ 901 CHA_Ziel_FahrPr_MO 0;
BA_ "GenSigSendType" SG_ 901 CHA_Ziel_FahrPr_MO_BZS 3;
BA_ "GenSigSwitchedByIgnition" SG_ 901 CHA_Ziel_FahrPr_MO_BZS 0;
BA_ "GenSigSendType" SG_ 901 CHA_Ziel_FahrPr_MO_StSt 3;
BA_ "GenSigSwitchedByIgnition" SG_ 901 CHA_Ziel_FahrPr_MO_StSt 0;
BA_ "GenSigSendType" SG_ 901 CHA_Ziel_FahrPr_PreCrash 3;
BA_ "GenSigSwitchedByIgnition" SG_ 901 CHA_Ziel_FahrPr_PreCrash 0;
BA_ "GenSigSendType" SG_ 901 CHA_Ziel_FahrPr_SAK 3;
BA_ "GenSigSwitchedByIgnition" SG_ 901 CHA_Ziel_FahrPr_SAK 0;
BA_ "GenSigSendType" SG_ 901 CHA_Ziel_FahrPr_VAQ 3;
BA_ "GenSigSwitchedByIgnition" SG_ 901 CHA_Ziel_FahrPr_VAQ 0;
BA_ "GenSigSendType" SG_ 1000 CHA_Fahrer_Umschaltung 3;
BA_ "GenSigSwitchedByIgnition" SG_ 1000 CHA_Fahrer_Umschaltung 0;
BA_ "GenSigSendType" SG_ 1000 CHA_Ziel_FahrPr_AFR 3;
BA_ "GenSigSwitchedByIgnition" SG_ 1000 CHA_Ziel_FahrPr_AFR 0;
BA_ "GenSigSendType" SG_ 1000 CHA_Ziel_FahrPr_AV 3;
BA_ "GenSigSwitchedByIgnition" SG_ 1000 CHA_Ziel_FahrPr_AV 0;
BA_ "GenSigSendType" SG_ 1000 CHA_Ziel_FahrPr_EAR 3;
BA_ "GenSigSwitchedByIgnition" SG_ 1000 CHA_Ziel_FahrPr_EAR 0;
BA_ "GenSigSendType" SG_ 1000 CHA_Ziel_FahrPr_EBKV 3;
BA_ "GenSigSwitchedByIgnition" SG_ 1000 CHA_Ziel_FahrPr_EBKV 0;
BA_ "GenSigSendType" SG_ 1000 CHA_Ziel_FahrPr_FCWO 3;
BA_ "GenSigSwitchedByIgnition" SG_ 1000 CHA_Ziel_FahrPr_FCWO 0;
BA_ "GenSigSendType" SG_ 1000 CHA_Ziel_FahrPr_FCWP 3;
BA_ "GenSigSwitchedByIgnition" SG_ 1000 CHA_Ziel_FahrPr_FCWP 0;
BA_ "GenSigSendType" SG_ 1000 CHA_Ziel_FahrPr_HAL 3;
BA_ "GenSigSwitchedByIgnition" SG_ 1000 CHA_Ziel_FahrPr_HAL 0;
BA_ "GenSigSendType" SG_ 1000 CHA_Ziel_FahrPr_HDC 3;
BA_ "GenSigSwitchedByIgnition" SG_ 1000 CHA_Ziel_FahrPr_HDC 0;
BA_ "GenSigSendType" SG_ 1000 CHA_Ziel_FahrPr_IL 3;
BA_ "GenSigSwitchedByIgnition" SG_ 1000 CHA_Ziel_FahrPr_IL 0;
BA_ "GenSigSendType" SG_ 1000 CHA_Ziel_FahrPr_MXB 3;
BA_ "GenSigSwitchedByIgnition" SG_ 1000 CHA_Ziel_FahrPr_MXB 0;
BA_ "GenSigSendType" SG_ 1000 CHA_Ziel_FahrPr_NR 3;
BA_ "GenSigSwitchedByIgnition" SG_ 1000 CHA_Ziel_FahrPr_NR 0;
BA_ "GenSigSendType" SG_ 1000 CHA_Ziel_FahrPr_QS 3;
BA_ "GenSigSwitchedByIgnition" SG_ 1000 CHA_Ziel_FahrPr_QS 0;
BA_ "GenSigSendType" SG_ 1000 CHA_Ziel_FahrPr_SCU 3;
BA_ "GenSigSwitchedByIgnition" SG_ 1000 CHA_Ziel_FahrPr_SCU 0;
BA_ "GenSigSendType" SG_ 1000 CHA_Ziel_FahrPr_WarnBrems 3;
BA_ "GenSigSwitchedByIgnition" SG_ 1000 CHA_Ziel_FahrPr_WarnBrems 0;
BA_ "GenSigSwitchedByIgnition" SG_ 2617006592 DEV_RDK_Resp_00_Data 0;
BA_ "GenSigSwitchedByIgnition" SG_ 2617006847 DEV_RDK_Resp_FF_Data 0;
BA_ "GenSigSwitchedByIgnition" SG_ 2617199104 DEV_RearView_Resp_00_Data 0;
BA_ "GenSigSwitchedByIgnition" SG_ 2617199359 DEV_RearView_Resp_FF_Data 0;
BA_ "GenSigSwitchedByIgnition" SG_ 2617070080 DEV_SCR_Resp_00_Data 0;
BA_ "GenSigSwitchedByIgnition" SG_ 2617070335 DEV_SCR_Resp_FF_Data 0;
BA_ "GenSigSwitchedByIgnition" SG_ 2617201152 DEV_STH_Resp_00_Data 0;
BA_ "GenSigSwitchedByIgnition" SG_ 2617201407 DEV_STH_Resp_FF_Data 0;
BA_ "GenSigSwitchedByIgnition" SG_ 2617004800 DEV_SWA_2_Resp_00_Data 0;
BA_ "GenSigSwitchedByIgnition" SG_ 2617005055 DEV_SWA_2_Resp_FF_Data 0;
BA_ "GenSigSwitchedByIgnition" SG_ 2617143808 DEV_SWA_Resp_00_Data 0;
BA_ "GenSigSwitchedByIgnition" SG_ 2617144063 DEV_SWA_Resp_FF_Data 0;
BA_ "GenSigSendType" SG_ 1714 DGN_Verlernzaehler 0;
BA_ "GenSigSwitchedByIgnition" SG_ 1714 DGN_Verlernzaehler 0;
BA_ "GenSigSendType" SG_ 1714 KBI_Kilometerstand 0;
BA_ "GenSigStartValue" SG_ 1714 KBI_Kilometerstand 1048574;
BA_ "GenSigSwitchedByIgnition" SG_ 1714 KBI_Kilometerstand 0;
BA_ "Fehlerwert" SG_ 1714 KBI_Kilometerstand 1048575;
BA_ "GenSigSendType" SG_ 1714 Kombi_02_alt 0;
BA_ "GenSigStartValue" SG_ 1714 Kombi_02_alt 1;
BA_ "GenSigFuncType" SG_ 1714 Kombi_02_alt 5;
BA_ "GenSigSwitchedByIgnition" SG_ 1714 Kombi_02_alt 0;
BA_ "GenSigSendType" SG_ 1714 UH_Jahr 0;
BA_ "GenSigSwitchedByIgnition" SG_ 1714 UH_Jahr 0;
BA_ "GenSigSendType" SG_ 1714 UH_Minute 0;
BA_ "GenSigSwitchedByIgnition" SG_ 1714 UH_Minute 0;
BA_ "GenSigSendType" SG_ 1714 UH_Monat 0;
BA_ "GenSigSwitchedByIgnition" SG_ 1714 UH_Monat 0;
BA_ "Fehlerwert" SG_ 1714 UH_Monat 15;
BA_ "GenSigSendType" SG_ 1714 UH_Sekunde 0;
BA_ "GenSigSwitchedByIgnition" SG_ 1714 UH_Sekunde 0;
BA_ "GenSigSendType" SG_ 1714 UH_Stunde 0;
BA_ "GenSigSwitchedByIgnition" SG_ 1714 UH_Stunde 0;
BA_ "GenSigSendType" SG_ 1714 UH_Tag 0;
BA_ "GenSigSwitchedByIgnition" SG_ 1714 UH_Tag 0;
BA_ "GenSigSendType" SG_ 1714 Uhrzeit_01_alt 0;
BA_ "GenSigStartValue" SG_ 1714 Uhrzeit_01_alt 1;
BA_ "GenSigFuncType" SG_ 1714 Uhrzeit_01_alt 5;
BA_ "GenSigSwitchedByIgnition" SG_ 1714 Uhrzeit_01_alt 0;
BA_ "GenSigSendType" SG_ 1520 BCM1_Stellgroesse_Kl_58s 3;
BA_ "GenSigStartValue" SG_ 1520 BCM1_Stellgroesse_Kl_58s 126;
BA_ "GenSigSwitchedByIgnition" SG_ 1520 BCM1_Stellgroesse_Kl_58s 0;
BA_ "Fehlerwert" SG_ 1520 BCM1_Stellgroesse_Kl_58s 127;
BA_ "GenSigSendType" SG_ 1520 DI_Display_Nachtdesign 3;
BA_ "GenSigSwitchedByIgnition" SG_ 1520 DI_Display_Nachtdesign 0;
BA_ "GenSigSendType" SG_ 1520 DI_Fotosensor 3;
BA_ "GenSigSwitchedByIgnition" SG_ 1520 DI_Fotosensor 0;
BA_ "GenSigSendType" SG_ 1520 DI_KL_58xd 3;
BA_ "GenSigStartValue" SG_ 1520 DI_KL_58xd 254;
BA_ "GenSigSwitchedByIgnition" SG_ 1520 DI_KL_58xd 0;
BA_ "Fehlerwert" SG_ 1520 DI_KL_58xd 255;
BA_ "GenSigSendType" SG_ 1520 DI_KL_58xs 3;
BA_ "GenSigStartValue" SG_ 1520 DI_KL_58xs 126;
BA_ "GenSigSwitchedByIgnition" SG_ 1520 DI_KL_58xs 0;
BA_ "Fehlerwert" SG_ 1520 DI_KL_58xs 127;
BA_ "GenSigSendType" SG_ 1520 DI_KL_58xt 3;
BA_ "GenSigStartValue" SG_ 1520 DI_KL_58xt 126;
BA_ "GenSigSwitchedByIgnition" SG_ 1520 DI_KL_58xt 0;
BA_ "Fehlerwert" SG_ 1520 DI_KL_58xt 127;
BA_ "GenSigSendType" SG_ null USSDM_Blindness 0;
BA_ "GenSigStartValue" SG_ null USSDM_Blindness 4;
BA_ "Fehlerwert" SG_ null USSDM_Blindness 7;
BA_ "GenSigSendType" SG_ null USSDM_CalibrationStatus 0;
BA_ "GenSigStartValue" SG_ null USSDM_CalibrationStatus 4;
BA_ "Fehlerwert" SG_ null USSDM_CalibrationStatus 7;
BA_ "GenSigSendType" SG_ null USSDM_DriverPresence 0;
BA_ "GenSigStartValue" SG_ null USSDM_DriverPresence 6;
BA_ "Fehlerwert" SG_ null USSDM_DriverPresence 7;
BA_ "GenSigSendType" SG_ null USSDM_EyesClosed 0;
BA_ "GenSigSendType" SG_ null USSDM_EyesFound 0;
BA_ "GenSigSendType" SG_ null USSDM_EyesOffRoadTime 0;
BA_ "GenSigStartValue" SG_ null USSDM_EyesOffRoadTime 510;
BA_ "Fehlerwert" SG_ null USSDM_EyesOffRoadTime 511;
BA_ "GenSigSendType" SG_ null USSDM_EyesOnRoad 0;
BA_ "Fehlerwert" SG_ null USSDM_EyesOnRoad 5;
BA_ "GenSigSendType" SG_ null USSDM_EyesOnRoadQual 0;
BA_ "GenSigStartValue" SG_ null USSDM_EyesOnRoadQual 14;
BA_ "Fehlerwert" SG_ null USSDM_EyesOnRoadQual 15;
BA_ "GenSigSendType" SG_ null USSDM_EyesOpen 0;
BA_ "GenSigSendType" SG_ null USSDM_FakeDetected 0;
BA_ "GenSigSendType" SG_ null USSDM_HeadBasedMirrorSelection 0;
BA_ "GenSigSendType" SG_ null USSDM_HeadFound 0;
BA_ "GenSigSendType" SG_ null USSDM_Microsleep 0;
BA_ "GenSigStartValue" SG_ null USSDM_Microsleep 2;
BA_ "Fehlerwert" SG_ null USSDM_Microsleep 7;
BA_ "GenSigSendType" SG_ null USSDM_MicrosleepQual 0;
BA_ "GenSigStartValue" SG_ null USSDM_MicrosleepQual 14;
BA_ "Fehlerwert" SG_ null USSDM_MicrosleepQual 15;
BA_ "GenSigSendType" SG_ null USSDM_Status 0;
BA_ "GenSigStartValue" SG_ null USSDM_Status 2;
BA_ "Fehlerwert" SG_ null USSDM_Status 7;
BA_ "GenSigSendType" SG_ null USSDM_VisualDistractionLevel 0;
BA_ "GenSigStartValue" SG_ null USSDM_VisualDistractionLevel 6;
BA_ "Fehlerwert" SG_ null USSDM_VisualDistractionLevel 7;
BA_ "GenSigSendType" SG_ null USSDM_VisualDistractionQual 0;
BA_ "GenSigStartValue" SG_ null USSDM_VisualDistractionQual 14;
BA_ "Fehlerwert" SG_ null USSDM_VisualDistractionQual 15;
BA_ "GenSigSendType" SG_ null USSDM_DetectionMode 0;
BA_ "GenSigStartValue" SG_ null USSDM_DetectionMode 6;
BA_ "Fehlerwert" SG_ null USSDM_DetectionMode 7;
BA_ "GenSigSendType" SG_ null USSDM_DurEyesOffTfc 0;
BA_ "GenSigStartValue" SG_ null USSDM_DurEyesOffTfc 510;
BA_ "Fehlerwert" SG_ null USSDM_DurEyesOffTfc 511;
BA_ "GenSigSendType" SG_ null USSDM_EyesOnTrafficQual 0;
BA_ "GenSigStartValue" SG_ null USSDM_EyesOnTrafficQual 14;
BA_ "Fehlerwert" SG_ null USSDM_EyesOnTrafficQual 15;
BA_ "GenSigSendType" SG_ null USSDM_ProbScndTsk 0;
BA_ "GenSigStartValue" SG_ null USSDM_ProbScndTsk 126;
BA_ "Fehlerwert" SG_ null USSDM_ProbScndTsk 127;
BA_ "GenSigSendType" SG_ null USSDM_SpaAttDstrAr_01 0;
BA_ "GenSigStartValue" SG_ null USSDM_SpaAttDstrAr_01 30;
BA_ "Fehlerwert" SG_ null USSDM_SpaAttDstrAr_01 31;
BA_ "GenSigSendType" SG_ null USSDM_SpaAttDstrAr_02 0;
BA_ "GenSigStartValue" SG_ null USSDM_SpaAttDstrAr_02 30;
BA_ "Fehlerwert" SG_ null USSDM_SpaAttDstrAr_02 31;
BA_ "GenSigSendType" SG_ null USSDM_SpaAttDstrAr_03 0;
BA_ "GenSigStartValue" SG_ null USSDM_SpaAttDstrAr_03 30;
BA_ "Fehlerwert" SG_ null USSDM_SpaAttDstrAr_03 31;
BA_ "GenSigSendType" SG_ null USSDM_SpaAttDstrProb_01 0;
BA_ "GenSigStartValue" SG_ null USSDM_SpaAttDstrProb_01 14;
BA_ "Fehlerwert" SG_ null USSDM_SpaAttDstrProb_01 15;
BA_ "GenSigSendType" SG_ null USSDM_TotDurEyesNotOnTfc 0;
BA_ "GenSigStartValue" SG_ null USSDM_TotDurEyesNotOnTfc 1022;
BA_ "Fehlerwert" SG_ null USSDM_TotDurEyesNotOnTfc 1023;
BA_ "GenSigSendType" SG_ null USSDM_DurEyesCl 0;
BA_ "GenSigStartValue" SG_ null USSDM_DurEyesCl 126;
BA_ "Fehlerwert" SG_ null USSDM_DurEyesCl 127;
BA_ "GenSigSendType" SG_ null USSDM_DurEyesNotOnTfc 0;
BA_ "GenSigStartValue" SG_ null USSDM_DurEyesNotOnTfc 510;
BA_ "Fehlerwert" SG_ null USSDM_DurEyesNotOnTfc 511;
BA_ "GenSigSendType" SG_ null USSDM_PercentageEyesOnTraffic 0;
BA_ "GenSigStartValue" SG_ null USSDM_PercentageEyesOnTraffic 126;
BA_ "Fehlerwert" SG_ null USSDM_PercentageEyesOnTraffic 127;
BA_ "GenSigSendType" SG_ null USSDM_SpaAttDstrProb_02 0;
BA_ "GenSigStartValue" SG_ null USSDM_SpaAttDstrProb_02 14;
BA_ "Fehlerwert" SG_ null USSDM_SpaAttDstrProb_02 15;
BA_ "GenSigSendType" SG_ null USSDM_SpaAttDstrProb_03 0;
BA_ "GenSigStartValue" SG_ null USSDM_SpaAttDstrProb_03 14;
BA_ "Fehlerwert" SG_ null USSDM_SpaAttDstrProb_03 15;
BA_ "GenSigSendType" SG_ null USSDM_ViewingDirectionPitch 0;
BA_ "GenSigStartValue" SG_ null USSDM_ViewingDirectionPitch 126;
BA_ "Fehlerwert" SG_ null USSDM_ViewingDirectionPitch 127;
BA_ "GenSigSendType" SG_ null USSDM_ViewingDirectionQuality 0;
BA_ "GenSigStartValue" SG_ null USSDM_ViewingDirectionQuality 14;
BA_ "Fehlerwert" SG_ null USSDM_ViewingDirectionQuality 15;
BA_ "GenSigSendType" SG_ null USSDM_ViewingDirectionYaw 0;
BA_ "GenSigStartValue" SG_ null USSDM_ViewingDirectionYaw 254;
BA_ "Fehlerwert" SG_ null USSDM_ViewingDirectionYaw 255;
BA_ "GenSigSendType" SG_ null USSDM_BlinkRate 0;
BA_ "GenSigStartValue" SG_ null USSDM_BlinkRate 30;
BA_ "Fehlerwert" SG_ null USSDM_BlinkRate 31;
BA_ "GenSigSendType" SG_ null USSDM_DriverChange 0;
BA_ "GenSigSendType" SG_ null USSDM_DriverPhoneUsage 0;
BA_ "GenSigStartValue" SG_ null USSDM_DriverPhoneUsage 6;
BA_ "Fehlerwert" SG_ null USSDM_DriverPhoneUsage 7;
BA_ "GenSigSendType" SG_ null USSDM_DriverPhoneUsageQual 0;
BA_ "GenSigStartValue" SG_ null USSDM_DriverPhoneUsageQual 14;
BA_ "Fehlerwert" SG_ null USSDM_DriverPhoneUsageQual 15;
BA_ "GenSigSendType" SG_ null USSDM_DriverSmoking 0;
BA_ "GenSigSwitchedByIgnition" SG_ null USSDM_DriverSmoking 0;
BA_ "Fehlerwert" SG_ null USSDM_DriverSmoking 7;
BA_ "GenSigSendType" SG_ null USSDM_DriverSmokingQual 0;
BA_ "GenSigSwitchedByIgnition" SG_ null USSDM_DriverSmokingQual 0;
BA_ "Fehlerwert" SG_ null USSDM_DriverSmokingQual 15;
BA_ "GenSigSendType" SG_ null USSDM_DriverSpeaking 0;
BA_ "GenSigSendType" SG_ null USSDM_DriverYawning 0;
BA_ "GenSigSwitchedByIgnition" SG_ null USSDM_DriverYawning 0;
BA_ "Fehlerwert" SG_ null USSDM_DriverYawning 7;
BA_ "GenSigSendType" SG_ null USSDM_DriverYawningQual 0;
BA_ "GenSigSwitchedByIgnition" SG_ null USSDM_DriverYawningQual 0;
BA_ "Fehlerwert" SG_ null USSDM_DriverYawningQual 15;
BA_ "GenSigSendType" SG_ null USSDM_DrowsinessLevel 0;
BA_ "GenSigStartValue" SG_ null USSDM_DrowsinessLevel 14;
BA_ "Fehlerwert" SG_ null USSDM_DrowsinessLevel 15;
BA_ "GenSigSendType" SG_ null USSDM_DrowsinessQual 0;
BA_ "GenSigStartValue" SG_ null USSDM_DrowsinessQual 14;
BA_ "Fehlerwert" SG_ null USSDM_DrowsinessQual 15;
BA_ "GenSigSendType" SG_ null USSDM_UnusualHeadPose 0;
BA_ "GenSigStartValue" SG_ null USSDM_UnusualHeadPose 6;
BA_ "Fehlerwert" SG_ null USSDM_UnusualHeadPose 7;
BA_ "GenSigSendType" SG_ null USSDM_UnusualHeadPoseQual 0;
BA_ "GenSigSwitchedByIgnition" SG_ null USSDM_UnusualHeadPoseQual 0;
BA_ "Fehlerwert" SG_ null USSDM_UnusualHeadPoseQual 15;
BA_REL_ "GenSigTimeoutTime" BU_SG_REL_ AEM SG_ 1714 DGN_Verlernzaehler 5000;
BA_REL_ "GenSigTimeoutTime" BU_SG_REL_ AEM SG_ 1714 KBI_Kilometerstand 5000;
BA_REL_ "GenSigTimeoutTime" BU_SG_REL_ AEM SG_ 1714 UH_Jahr 5000;
BA_REL_ "GenSigTimeoutTime" BU_SG_REL_ AEM SG_ 1714 UH_Monat 5000;
BA_REL_ "GenSigTimeoutTime" BU_SG_REL_ AEM SG_ 1714 UH_Tag 5000;
BA_REL_ "GenSigTimeoutTime" BU_SG_REL_ AEM SG_ 1714 UH_Stunde 5000;
BA_REL_ "GenSigTimeoutTime" BU_SG_REL_ AEM SG_ 1714 UH_Minute 5000;
BA_REL_ "GenSigTimeoutTime" BU_SG_REL_ AEM SG_ 1714 UH_Sekunde 5000;
BA_REL_ "GenSigTimeoutTime" BU_SG_REL_ E_Sound SG_ 64 AB_Crash_Int 500;
BA_REL_ "GenSigTimeoutTime" BU_SG_REL_ E_Sound SG_ 1432 E_Sound_LED_Status 5000;
BA_REL_ "GenSigTimeoutTime" BU_SG_REL_ E_Sound SG_ 1432 BCM1_eSound_Taster 5000;
BA_REL_ "GenSigTimeoutTime" BU_SG_REL_ E_Sound SG_ 901 CHA_Ziel_FahrPr_AGA 5000;
BA_REL_ "GenSigTimeoutTime" BU_SG_REL_ E_Sound SG_ 901 CHA_Fahrer_Umschaltung 5000;
BA_REL_ "GenSigTimeoutTime" BU_SG_REL_ E_Sound SG_ 1714 DGN_Verlernzaehler 5000;
BA_REL_ "GenSigTimeoutTime" BU_SG_REL_ E_Sound SG_ 1714 KBI_Kilometerstand 5000;
BA_REL_ "GenSigTimeoutTime" BU_SG_REL_ E_Sound SG_ 1714 UH_Jahr 5000;
BA_REL_ "GenSigTimeoutTime" BU_SG_REL_ E_Sound SG_ 1714 UH_Monat 5000;
BA_REL_ "GenSigTimeoutTime" BU_SG_REL_ E_Sound SG_ 1714 UH_Tag 5000;
BA_REL_ "GenSigTimeoutTime" BU_SG_REL_ E_Sound SG_ 1714 UH_Stunde 5000;
BA_REL_ "GenSigTimeoutTime" BU_SG_REL_ E_Sound SG_ 1714 UH_Minute 5000;
BA_REL_ "GenSigTimeoutTime" BU_SG_REL_ E_Sound SG_ 1714 UH_Sekunde 5000;
BA_REL_ "GenSigTimeoutTime" BU_SG_REL_ FBK SG_ 64 AB_Belegung_VF 500;
BA_REL_ "GenSigTimeoutTime" BU_SG_REL_ FBK SG_ 1312 AB_Belegung_VB 2000;
BA_REL_ "GenSigTimeoutTime" BU_SG_REL_ FBK SG_ 1312 AB_Gurtschloss_FA 2000;
BA_REL_ "GenSigTimeoutTime" BU_SG_REL_ FBK SG_ 1312 AB_Gurtschloss_BF 2000;
BA_REL_ "GenSigTimeoutTime" BU_SG_REL_ FBK SG_ 1312 AB_Gurtschloss_Reihe2_FA 2000;
BA_REL_ "GenSigTimeoutTime" BU_SG_REL_ FBK SG_ 1312 AB_Gurtschloss_Reihe2_MI 2000;
BA_REL_ "GenSigTimeoutTime" BU_SG_REL_ FBK SG_ 1312 AB_Gurtschloss_Reihe2_BF 2000;
BA_REL_ "GenSigTimeoutTime" BU_SG_REL_ FBK SG_ 1312 AB_Gurtschloss_Reihe3_FA 2000;
BA_REL_ "GenSigTimeoutTime" BU_SG_REL_ FBK SG_ 1312 AB_Gurtschloss_Reihe3_MI 2000;
BA_REL_ "GenSigTimeoutTime" BU_SG_REL_ FBK SG_ 1312 AB_Gurtschloss_Reihe3_BF 2000;
BA_REL_ "GenSigTimeoutTime" BU_SG_REL_ FBK SG_ 1626 BCM1_Lenksaeule_aktiv 5000;
BA_REL_ "GenSigTimeoutTime" BU_SG_REL_ FBK SG_ 1714 KBI_Kilometerstand 5000;
BA_REL_ "GenSigTimeoutTime" BU_SG_REL_ FBK SG_ 1714 UH_Jahr 5000;
BA_REL_ "GenSigTimeoutTime" BU_SG_REL_ FBK SG_ 1714 UH_Monat 5000;
BA_REL_ "GenSigTimeoutTime" BU_SG_REL_ FBK SG_ 1714 UH_Tag 5000;
BA_REL_ "GenSigTimeoutTime" BU_SG_REL_ FBK SG_ 1714 UH_Stunde 5000;
BA_REL_ "GenSigTimeoutTime" BU_SG_REL_ FBK SG_ 1714 UH_Minute 5000;
BA_REL_ "GenSigTimeoutTime" BU_SG_REL_ FBK SG_ 1714 UH_Sekunde 5000;
BA_REL_ "GenSigTimeoutTime" BU_SG_REL_ FLA SG_ 1714 DGN_Verlernzaehler 5000;
BA_REL_ "GenSigTimeoutTime" BU_SG_REL_ FLA SG_ 1714 KBI_Kilometerstand 5000;
BA_REL_ "GenSigTimeoutTime" BU_SG_REL_ FLA SG_ 1714 UH_Jahr 5000;
BA_REL_ "GenSigTimeoutTime" BU_SG_REL_ FLA SG_ 1714 UH_Monat 5000;
BA_REL_ "GenSigTimeoutTime" BU_SG_REL_ FLA SG_ 1714 UH_Tag 5000;
BA_REL_ "GenSigTimeoutTime" BU_SG_REL_ FLA SG_ 1714 UH_Stunde 5000;
BA_REL_ "GenSigTimeoutTime" BU_SG_REL_ FLA SG_ 1714 UH_Minute 5000;
BA_REL_ "GenSigTimeoutTime" BU_SG_REL_ FLA SG_ 1714 UH_Sekunde 5000;
BA_REL_ "GenSigTimeoutTime" BU_SG_REL_ FLA SG_ 1520 DI_KL_58xd 2000;
BA_REL_ "GenSigTimeoutTime" BU_SG_REL_ Gateway SG_ 1660 AGA_Charisma_FahrPr 5000;
BA_REL_ "GenSigTimeoutTime" BU_SG_REL_ Gateway SG_ 1660 AGA_Charisma_Status 5000;
BA_REL_ "GenSigTimeoutTime" BU_SG_REL_ Gateway_PAG SG_ 1660 AGA_Charisma_FahrPr 5000;
BA_REL_ "GenSigTimeoutTime" BU_SG_REL_ Gateway_PAG SG_ 1660 AGA_Charisma_Status 5000;
BA_REL_ "GenSigTimeoutTime" BU_SG_REL_ ISE SG_ 1660 E_Sound_Texte 5000;
BA_REL_ "GenSigTimeoutTime" BU_SG_REL_ ISE SG_ 64 AB_Crash_Int 500;
BA_REL_ "GenSigTimeoutTime" BU_SG_REL_ ISE SG_ 1432 BCM_Soundklappe_Taster 5000;
BA_REL_ "GenSigTimeoutTime" BU_SG_REL_ ISE SG_ 1432 E_Sound_LED_Status 5000;
BA_REL_ "GenSigTimeoutTime" BU_SG_REL_ ISE SG_ 1432 BCM1_eSound_Taster 5000;
BA_REL_ "GenSigTimeoutTime" BU_SG_REL_ ISE SG_ 901 CHA_Ziel_FahrPr_AGA 5000;
BA_REL_ "GenSigTimeoutTime" BU_SG_REL_ ISE SG_ 901 CHA_Fahrer_Umschaltung 5000;
BA_REL_ "GenSigTimeoutTime" BU_SG_REL_ ISE SG_ 901 CHA_Ziel_FahrPr_SAK 5000;
BA_REL_ "GenSigTimeoutTime" BU_SG_REL_ ISE SG_ 1714 DGN_Verlernzaehler 5000;
BA_REL_ "GenSigTimeoutTime" BU_SG_REL_ ISE SG_ 1714 KBI_Kilometerstand 5000;
BA_REL_ "GenSigTimeoutTime" BU_SG_REL_ ISE SG_ 1714 UH_Jahr 5000;
BA_REL_ "GenSigTimeoutTime" BU_SG_REL_ ISE SG_ 1714 UH_Monat 5000;
BA_REL_ "GenSigTimeoutTime" BU_SG_REL_ ISE SG_ 1714 UH_Tag 5000;
BA_REL_ "GenSigTimeoutTime" BU_SG_REL_ ISE SG_ 1714 UH_Stunde 5000;
BA_REL_ "GenSigTimeoutTime" BU_SG_REL_ ISE SG_ 1714 UH_Minute 5000;
BA_REL_ "GenSigTimeoutTime" BU_SG_REL_ ISE SG_ 1714 UH_Sekunde 5000;
BA_REL_ "GenSigTimeoutTime" BU_SG_REL_ NightVision SG_ 64 SC_Masterzeit 500;
BA_REL_ "GenSigTimeoutTime" BU_SG_REL_ NightVision SG_ 1349 SC_PreSense_Modus_Warnung_NV 2000;
BA_REL_ "GenSigTimeoutTime" BU_SG_REL_ NightVision SG_ 1349 SC_PreSense_Modus_System_NV 2000;
BA_REL_ "GenSigTimeoutTime" BU_SG_REL_ NightVision SG_ 326 Airbag_05_CRC 500;
BA_REL_ "GenSigTimeoutTime" BU_SG_REL_ NightVision SG_ 326 Airbag_05_BZ 500;
BA_REL_ "GenSigTimeoutTime" BU_SG_REL_ NightVision SG_ 326 SC_QBit_FASIS_SyncCounter 500;
BA_REL_ "GenSigTimeoutTime" BU_SG_REL_ NightVision SG_ 326 SC_FASIS_SyncCounter 500;
BA_REL_ "GenSigTimeoutTime" BU_SG_REL_ NightVision SG_ 1626 BCM1_LDS_Stellung 5000;
BA_REL_ "GenSigTimeoutTime" BU_SG_REL_ NightVision SG_ 1626 BCM1_NV_Taster 5000;
BA_REL_ "GenSigTimeoutTime" BU_SG_REL_ NightVision SG_ 2527679637 BCM_LTM_PopUp_Status 5000;
BA_REL_ "GenSigTimeoutTime" BU_SG_REL_ NightVision SG_ 2527679637 BCM_LTM_PopUp_Anf 5000;
BA_REL_ "GenSigTimeoutTime" BU_SG_REL_ NightVision SG_ 1714 DGN_Verlernzaehler 5000;
BA_REL_ "GenSigTimeoutTime" BU_SG_REL_ NightVision SG_ 1714 KBI_Kilometerstand 5000;
BA_REL_ "GenSigTimeoutTime" BU_SG_REL_ NightVision SG_ 1714 UH_Jahr 5000;
BA_REL_ "GenSigTimeoutTime" BU_SG_REL_ NightVision SG_ 1714 UH_Monat 5000;
BA_REL_ "GenSigTimeoutTime" BU_SG_REL_ NightVision SG_ 1714 UH_Tag 5000;
BA_REL_ "GenSigTimeoutTime" BU_SG_REL_ NightVision SG_ 1714 UH_Stunde 5000;
BA_REL_ "GenSigTimeoutTime" BU_SG_REL_ NightVision SG_ 1714 UH_Minute 5000;
BA_REL_ "GenSigTimeoutTime" BU_SG_REL_ NightVision SG_ 1714 UH_Sekunde 5000;
BA_REL_ "GenSigTimeoutTime" BU_SG_REL_ RDK SG_ 1714 DGN_Verlernzaehler 5000;
BA_REL_ "GenSigTimeoutTime" BU_SG_REL_ RDK SG_ 1714 KBI_Kilometerstand 5000;
BA_REL_ "GenSigTimeoutTime" BU_SG_REL_ RDK SG_ 1714 UH_Jahr 5000;
BA_REL_ "GenSigTimeoutTime" BU_SG_REL_ RDK SG_ 1714 UH_Monat 5000;
BA_REL_ "GenSigTimeoutTime" BU_SG_REL_ RDK SG_ 1714 UH_Tag 5000;
BA_REL_ "GenSigTimeoutTime" BU_SG_REL_ RDK SG_ 1714 UH_Stunde 5000;
BA_REL_ "GenSigTimeoutTime" BU_SG_REL_ RDK SG_ 1714 UH_Minute 5000;
BA_REL_ "GenSigTimeoutTime" BU_SG_REL_ RDK SG_ 1714 UH_Sekunde 5000;
BA_REL_ "GenSigTimeoutTime" BU_SG_REL_ SAK SG_ 901 CHA_Fahrer_Umschaltung 5000;
BA_REL_ "GenSigTimeoutTime" BU_SG_REL_ SAK SG_ 901 CHA_Ziel_FahrPr_SAK 5000;
BA_REL_ "GenSigTimeoutTime" BU_SG_REL_ SAK SG_ 1714 DGN_Verlernzaehler 5000;
BA_REL_ "GenSigTimeoutTime" BU_SG_REL_ SAK SG_ 1714 KBI_Kilometerstand 5000;
BA_REL_ "GenSigTimeoutTime" BU_SG_REL_ SAK SG_ 1714 UH_Jahr 5000;
BA_REL_ "GenSigTimeoutTime" BU_SG_REL_ SAK SG_ 1714 UH_Monat 5000;
BA_REL_ "GenSigTimeoutTime" BU_SG_REL_ SAK SG_ 1714 UH_Tag 5000;
BA_REL_ "GenSigTimeoutTime" BU_SG_REL_ SAK SG_ 1714 UH_Stunde 5000;
BA_REL_ "GenSigTimeoutTime" BU_SG_REL_ SAK SG_ 1714 UH_Minute 5000;
BA_REL_ "GenSigTimeoutTime" BU_SG_REL_ SAK SG_ 1714 UH_Sekunde 5000;
BA_REL_ "GenSigTimeoutTime" BU_SG_REL_ SAK2 SG_ 901 CHA_Ziel_FahrPr_AGA 5000;
BA_REL_ "GenSigTimeoutTime" BU_SG_REL_ SAK2 SG_ 901 CHA_Fahrer_Umschaltung 5000;
BA_REL_ "GenSigTimeoutTime" BU_SG_REL_ SAK2 SG_ 1714 DGN_Verlernzaehler 5000;
BA_REL_ "GenSigTimeoutTime" BU_SG_REL_ SAK2 SG_ 1714 KBI_Kilometerstand 5000;
BA_REL_ "GenSigTimeoutTime" BU_SG_REL_ SAK2 SG_ 1714 UH_Jahr 5000;
BA_REL_ "GenSigTimeoutTime" BU_SG_REL_ SAK2 SG_ 1714 UH_Monat 5000;
BA_REL_ "GenSigTimeoutTime" BU_SG_REL_ SAK2 SG_ 1714 UH_Tag 5000;
BA_REL_ "GenSigTimeoutTime" BU_SG_REL_ SAK2 SG_ 1714 UH_Stunde 5000;
BA_REL_ "GenSigTimeoutTime" BU_SG_REL_ SAK2 SG_ 1714 UH_Minute 5000;
BA_REL_ "GenSigTimeoutTime" BU_SG_REL_ SAK2 SG_ 1714 UH_Sekunde 5000;
BA_REL_ "GenSigTimeoutTime" BU_SG_REL_ SCR SG_ 1714 DGN_Verlernzaehler 5000;
BA_REL_ "GenSigTimeoutTime" BU_SG_REL_ SCR SG_ 1714 KBI_Kilometerstand 5000;
BA_REL_ "GenSigTimeoutTime" BU_SG_REL_ SCR SG_ 1714 UH_Jahr 5000;
BA_REL_ "GenSigTimeoutTime" BU_SG_REL_ SCR SG_ 1714 UH_Monat 5000;
BA_REL_ "GenSigTimeoutTime" BU_SG_REL_ SCR SG_ 1714 UH_Tag 5000;
BA_REL_ "GenSigTimeoutTime" BU_SG_REL_ SCR SG_ 1714 UH_Stunde 5000;
BA_REL_ "GenSigTimeoutTime" BU_SG_REL_ SCR SG_ 1714 UH_Minute 5000;
BA_REL_ "GenSigTimeoutTime" BU_SG_REL_ SCR SG_ 1714 UH_Sekunde 5000;
BA_REL_ "GenSigTimeoutTime" BU_SG_REL_ STH_MLBevo SG_ 64 AB_Crash_Int 500;
BA_REL_ "GenSigTimeoutTime" BU_SG_REL_ STH_MLBevo SG_ 64 AB_Stellgliedtest 500;
BA_REL_ "GenSigTimeoutTime" BU_SG_REL_ STH_MLBevo SG_ 1714 DGN_Verlernzaehler 5000;
BA_REL_ "GenSigTimeoutTime" BU_SG_REL_ STH_MLBevo SG_ 1714 KBI_Kilometerstand 5000;
BA_REL_ "GenSigTimeoutTime" BU_SG_REL_ STH_MLBevo SG_ 1714 UH_Jahr 5000;
BA_REL_ "GenSigTimeoutTime" BU_SG_REL_ STH_MLBevo SG_ 1714 UH_Monat 5000;
BA_REL_ "GenSigTimeoutTime" BU_SG_REL_ STH_MLBevo SG_ 1714 UH_Tag 5000;
BA_REL_ "GenSigTimeoutTime" BU_SG_REL_ STH_MLBevo SG_ 1714 UH_Stunde 5000;
BA_REL_ "GenSigTimeoutTime" BU_SG_REL_ STH_MLBevo SG_ 1714 UH_Minute 5000;
BA_REL_ "GenSigTimeoutTime" BU_SG_REL_ STH_MLBevo SG_ 1714 UH_Sekunde 5000;
BA_REL_ "GenSigTimeoutTime" BU_SG_REL_ TopView SG_ 1633 AAG_Anhaenger_erkannt 1000;
BA_REL_ "GenSigTimeoutTime" BU_SG_REL_ TopView SG_ 345 ARA_Knickwinkel_Konfidenz 1000;
BA_REL_ "GenSigTimeoutTime" BU_SG_REL_ TopView SG_ 345 ARA_Deaktivierung_sperren 1000;
BA_REL_ "GenSigTimeoutTime" BU_SG_REL_ TopView SG_ 345 ARA_Sensor_Aktivierung 1000;
BA_REL_ "GenSigTimeoutTime" BU_SG_REL_ TopView SG_ 345 ARA_Knickwinkel_Komfort 1000;
BA_REL_ "GenSigTimeoutTime" BU_SG_REL_ TopView SG_ 345 ARA_Status 1000;
BA_REL_ "GenSigTimeoutTime" BU_SG_REL_ TopView SG_ 345 ARA_Knickwinkel_Max 1000;
BA_REL_ "GenSigTimeoutTime" BU_SG_REL_ TopView SG_ 345 ARA_Knickwinkel_Soll 1000;
BA_REL_ "GenSigTimeoutTime" BU_SG_REL_ TopView SG_ 345 ARA_Knickwinkel_Ist 1000;
BA_REL_ "GenSigTimeoutTime" BU_SG_REL_ TopView SG_ 1013 ARA_Weg_abs 1000;
BA_REL_ "GenSigTimeoutTime" BU_SG_REL_ TopView SG_ 1013 ARA_Verw_Zeitstempel_BV 1000;
BA_REL_ "GenSigTimeoutTime" BU_SG_REL_ TopView SG_ 1013 ARA_Winkel_abs 1000;
BA_REL_ "GenSigTimeoutTime" BU_SG_REL_ TopView SG_ 1013 ARA_Winkel_logVarianz 1000;
BA_REL_ "GenSigTimeoutTime" BU_SG_REL_ TopView SG_ 1013 ARA_Winkel_logInnovation 1000;
BA_REL_ "GenSigTimeoutTime" BU_SG_REL_ TopView SG_ 1626 BCM_Waschwasser_Sensor 5000;
BA_REL_ "GenSigTimeoutTime" BU_SG_REL_ TopView SG_ 1626 BCM1_MH_Schalter 5000;
BA_REL_ "GenSigTimeoutTime" BU_SG_REL_ TopView SG_ 961 Sideview_Taster 2000;
BA_REL_ "GenSigTimeoutTime" BU_SG_REL_ TopView SG_ 1000 CHA_Ziel_FahrPr_AV 5000;
BA_REL_ "GenSigTimeoutTime" BU_SG_REL_ TopView SG_ 1714 DGN_Verlernzaehler 5000;
BA_REL_ "GenSigTimeoutTime" BU_SG_REL_ TopView SG_ 1714 KBI_Kilometerstand 5000;
BA_REL_ "GenSigTimeoutTime" BU_SG_REL_ TopView SG_ 1714 UH_Jahr 5000;
BA_REL_ "GenSigTimeoutTime" BU_SG_REL_ TopView SG_ 1714 UH_Monat 5000;
BA_REL_ "GenSigTimeoutTime" BU_SG_REL_ TopView SG_ 1714 UH_Tag 5000;
BA_REL_ "GenSigTimeoutTime" BU_SG_REL_ TopView SG_ 1714 UH_Stunde 5000;
BA_REL_ "GenSigTimeoutTime" BU_SG_REL_ TopView SG_ 1714 UH_Minute 5000;
BA_REL_ "GenSigTimeoutTime" BU_SG_REL_ TopView SG_ 1714 UH_Sekunde 5000;
BA_REL_ "GenSigTimeoutTime" BU_SG_REL_ TopView SG_ 1520 DI_KL_58xd 2000;
VAL_ 1469 AEM_Temp_Abschaltung 0 "Keine_Abschaltung" 1 "Abschaltung_Stufe_1" 2 "Abschaltung_Stufe_2" 3 "Abschaltung_Vollstaendig" ;
VAL_ 1469 AEM_Status_Regelung 0 "Init" 1 "betriebsbereit_passiv" 2 "Aktiv" 3 "Identifikation_aktiv" 7 "Fehler" ;
VAL_ 1660 E_Sound_Texte 0 "keine_Anzeige" 1 "Aussensound_defekt" 2 "Aussensound_deaktiviert" 3 "Aussensound_deaktiviert_reduziertWarn" 4 "Aussensound_aktiviert" 5 "Aussensound_deaktiviert_KL15" 7 "Fehler" ;
VAL_ 1660 E_Sound_verbaut 0 "nicht_verbaut" 1 "verbaut" ;
VAL_ 1660 AGA_Charisma_FahrPr 0 "keine_Funktion" 1 "Programm_1" 2 "Programm_2" 3 "Programm_3" 4 "Programm_4" 5 "Programm_5" 6 "Programm_6" 7 "Programm_7" 8 "Programm_8" 9 "Programm_9" 10 "Programm_10" 11 "Programm_11" 12 "Programm_12" 13 "Programm_13" 14 "Programm_14" 15 "Programm_15" ;
VAL_ 1660 AGA_Charisma_Status 0 "Init" 1 "verfuegbar" 2 "nicht_verfuegbar" 3 "asynchron_durch_Fahrerwunsch" ;
VAL_ 1660 E_Sound_ohne_Funktion 0 "kein_Fehler" 1 "Fehler" ;
VAL_ 1660 AGA_Verstaerker_Mute 0 "Mute" 1 "Kein_Mute" ;
VAL_ 1660 E_Sound_Mute_Icon 0 "Icon_aus" 1 "Icon_ein" 2 "Icon_blinken" 3 "Init" ;
VAL_ 1660 E_Sound_Mute_LED 0 "LED_aus" 1 "LED_ein" 2 "LED_blinken" 3 "Init" ;
VAL_ 64 AB_RGS_Anst 4 "aktiv_Niveau_1" 5 "aktiv_Niveau_2" 6 "aktiv_Niveau_3" 7 "aktiv_Niveau_4" 8 "deaktiviert" ;
VAL_ 64 AB_Front_Crash 0 "kein_Front_Crash" 1 "Front_Crash" ;
VAL_ 64 AB_Heck_Crash 0 "kein_Heck_Crash" 1 "Heck_Crash" ;
VAL_ 64 AB_SF_Crash 0 "kein_Seiten_Crash_Fahrer" 1 "Seiten_Crash_Fahrer" ;
VAL_ 64 AB_SB_Crash 0 "kein_Seiten_Crash_Beifahrer" 1 "Seiten_Crash_Beifahrer" ;
VAL_ 64 AB_Rollover_Crash 0 "kein_Rollover" 1 "Rollover" ;
VAL_ 64 AB_Crash_Int 0 "kein_Crash" 1 "Crash_Intensitaet_1" 2 "Crash_Intensitaet_2_(nur_Stellgliedtest_MLB_B8)" 3 "Crash_Intensitaet_2_(nur_D4_C7_Colorado_NF_PAG__Crash_im_MLB_B8)" 4 "Crash_Intensitaet_3_(alt_VW/AUDI__Stellgliedtest_MLB_B8)" 5 "Crash_Intensitaet_3_(alt_PAG)" 7 "Crash_Intensitaet_3" ;
VAL_ 64 AB_Lampe 0 "Aus" 1 "Ein" ;
VAL_ 64 AB_Deaktiviert 0 "aktiv" 1 "deaktiviert" ;
VAL_ 64 AB_VB_deaktiviert 0 "Beifahrerairbag_aktiv" 1 "Beifahrerairbag_deaktiviert" ;
VAL_ 64 AB_Systemfehler 0 "kein_Fehler" 1 "Airbag_Systemfehler" ;
VAL_ 64 AB_Diagnose 0 "nicht_in_Diagnose" 1 "in_Diagnose" ;
VAL_ 64 AB_Stellgliedtest 0 "nicht_im_Stellgliedtest" 1 "Airbag_im_Stellgliedtest" ;
VAL_ 64 AB_Erh_Auf_VB 0 "keine_Anzeige" 1 "Beifahrerairbag_deaktiviert" 2 "Beifahrerairbag_aktiviert" 3 "nicht_definiert" ;
VAL_ 64 AB_Gurtwarn_VF 0 "keine_Warnung" 1 "Gurtwarnung_ausloesen" ;
VAL_ 64 AB_Gurtwarn_VB 0 "keine_Warnung" 1 "Gurtwarnung_ausloesen" ;
VAL_ 64 AB_Anzeige_Fussg 0 "keine_FSG_Aktion_ausgeloest" 1 "Motorhaube_offen" 2 "Systemfehler" ;
VAL_ 64 AB_Texte_AKS 0 "keine_AKS_Ausloesung" 1 "AKS_ausgeloest" 2 "AKS_Systemfehler" ;
VAL_ 64 AB_MKB_gueltig 0 "Multikollisionsbremsung_nicht_freigeschaltet" 1 "Multikollisionsbremsung_freigeschaltet" ;
VAL_ 64 AB_MKB_Anforderung 0 "Multikollisionsbremsung_nicht_angefordert" 1 "Multikollisionsbremsung_angefordert" ;
VAL_ 64 AB_Versorgungsspannung 0 "plausibel" 1 "unplausibel" ;
VAL_ 64 AB_Deaktivierung_HV 0 "keine_Deaktivierung" 1 "Deaktivierung_1" 2 "Deaktivierung_2" 3 "Deaktivierung_3" 4 "Deaktivierung_4" 5 "Deaktivierung_5" 6 "Deaktivierung_6" 7 "Fehler" ;
VAL_ 64 AB_EDR_Trigger 0 "No_Event" 1 "Start_Event" 2 "NonDeployment_Event" 3 "Deployment_Event" ;
VAL_ 64 AB_Belegung_VF 0 "nicht_verfuegbar" 1 "Fehler" 2 "nicht_belegt" 3 "belegt" ;
VAL_ 64 SC_LowSpeedCrashErkannt 0 "kein_Crash_erkannt" 1 "Crash_Frontbereich_erkannt" 2 "Crash_Heckbereich_erkannt" 3 "Crash_Front_und_Heckbereich_erkannt" ;
VAL_ 64 SC_Masterzeit 127 "Init" ;
VAL_ 1312 LoGeWa_Event_Kombiwarnung 0 "Init" 1 "Unfall" 2 "Traktionsverlust" 3 "Panne" 4 "Sichtbehinderung" 5 "Aquaplaning" ;
VAL_ 1312 AB_Anforderung_eCall 0 "keine_Anforderung" 1 "Anforderung" ;
VAL_ 1312 AB_Anprall_Seite_Beifahrer 0 "kein_Anprall" 1 "Anprall_erkannt" ;
VAL_ 1312 AB_Anprall_Rollover 0 "kein_Anprall" 1 "Anprall_erkannt" ;
VAL_ 1312 AB_Anprall_FGS 0 "kein_Anprall" 1 "Anprall_erkannt" ;
VAL_ 1312 AB_Anprall_Front_Beifahrer 0 "kein_Anprall" 1 "Anprall_erkannt" ;
VAL_ 1312 AB_Anprall_Front_Fahrer 0 "kein_Anprall" 1 "Anprall_erkannt" ;
VAL_ 1312 AB_Anprall_Heck_Beifahrer 0 "kein_Anprall" 1 "Anprall_erkannt" ;
VAL_ 1312 AB_Anprall_Heck_Fahrer 0 "kein_Anprall" 1 "Anprall_erkannt" ;
VAL_ 1312 AB_Wickelklappung_Reihe2_MI 0 "nicht_verbaut" 1 "nicht_verfuegbar__Fehler_oder_Init" 2 "nicht_verriegelt" 3 "verriegelt" ;
VAL_ 1312 AB_Belegung_VB 0 "nicht_verfuegbar" 1 "Fehler" 2 "nicht_belegt" 3 "belegt" ;
VAL_ 1312 AB_Abschaltanf_SIH_BF 0 "Normalbetrieb" 1 "Abschaltung_angefordert" ;
VAL_ 1312 AB_Anprall_Seite_Fahrer 0 "kein_Anprall" 1 "Anprall_erkannt" ;
VAL_ 1312 SC_PAO_Schriftzug_Anf 0 "LED aus" 1 "LED an" 2 "LED blinken" 3 "reserviert" ;
VAL_ 1312 SC_PAO_ON_Anf 0 "LED aus" 1 "LED an" 2 "LED blinken" 3 "reserviert" ;
VAL_ 1312 SC_PAO_OFF_Anf 0 "LED aus" 1 "LED an" 2 "LED blinken" 3 "reserviert" ;
VAL_ 1312 AB_Crashschwere 0 "kein_Ereignis" 1 "Crashschwere_1" 2 "Crashschwere_2" 3 "Crashschwere_3" 4 "Crashschwere_4" 5 "Crashschwere_5" 6 "Crashschwere_2_bis_5" 7 "Fehler" ;
VAL_ 1312 AB_Anforderung_USM 0 "keine_Anforderung" 1 "Anforderung" ;
VAL_ 1312 AB_Gurtschloss_FA 0 "nicht_verbaut" 1 "nicht_verfügbar (Fehler oder Init)" 2 "nicht_gesteckt" 3 "gesteckt" ;
VAL_ 1312 AB_Gurtschloss_BF 0 "nicht_verbaut" 1 "nicht_verfügbar (Fehler oder Init)" 2 "nicht_gesteckt" 3 "gesteckt" ;
VAL_ 1312 AB_Gurtschloss_Reihe2_FA 0 "nicht_verbaut" 1 "nicht_verfügbar (Fehler oder Init)" 2 "nicht_gesteckt" 3 "gesteckt" ;
VAL_ 1312 AB_Gurtschloss_Reihe2_MI 0 "nicht_verbaut" 1 "nicht_verfügbar (Fehler oder Init)" 2 "nicht_gesteckt" 3 "gesteckt" ;
VAL_ 1312 AB_Gurtschloss_Reihe2_BF 0 "nicht_verbaut" 1 "nicht_verfügbar (Fehler oder Init)" 2 "nicht_gesteckt" 3 "gesteckt" ;
VAL_ 1312 AB_Gurtschloss_Reihe3_FA 0 "nicht_verbaut" 1 "nicht_verfügbar (Fehler oder Init)" 2 "nicht_gesteckt" 3 "gesteckt" ;
VAL_ 1312 AB_Gurtschloss_Reihe3_MI 0 "nicht_verbaut" 1 "nicht_verfügbar (Fehler oder Init)" 2 "nicht_gesteckt" 3 "gesteckt" ;
VAL_ 1312 AB_Gurtschloss_Reihe3_BF 0 "nicht_verbaut" 1 "nicht_verfügbar (Fehler oder Init)" 2 "nicht_gesteckt" 3 "gesteckt" ;
VAL_ 1312 AB_Sitzpos_Sens_FA 0 "nicht verfügbar" 1 "Fehler" 2 "Sitz nicht vorne" 3 "Sitz vorne" ;
VAL_ 1312 AB_Sitzpos_Sens_BF 0 "nicht verfügbar" 1 "Fehler" 2 "Sitz nicht vorne" 3 "Sitz vorne" ;
VAL_ 1312 AB_Wickelklappung_Reihe2_BF 0 "nicht_verbaut" 1 "nicht_verfuegbar__Fehler_oder_Init" 2 "nicht_verriegelt" 3 "verriegelt" ;
VAL_ 1312 AB_Wickelklappung_Reihe2_FA 0 "nicht_verbaut" 1 "nicht_verfuegbar__Fehler_oder_Init" 2 "nicht_verriegelt" 3 "verriegelt" ;
VAL_ 1349 AB_Gurtwarn_Reihe2_FA 0 "nicht_verbaut" 1 "keine_Gurtwarnung_Sitz_leer" 2 "keine_Gurtwarnung_Sitz_belegt" 3 "Gurtwarnung_Sitz_belegt" ;
VAL_ 1349 AB_Gurtwarn_Reihe2_BF 0 "nicht_verbaut" 1 "keine_Gurtwarnung_Sitz_leer" 2 "keine_Gurtwarnung_Sitz_belegt" 3 "Gurtwarnung_Sitz_belegt" ;
VAL_ 1349 AbstWarn_MV_FAS_Fkt_Status 0 "Init" 1 "Funktion_Ist_Ein" 2 "Funktion_Ist_Aus" 3 "Fehler" ;
VAL_ 1349 WarnBrems_Charisma_Status 0 "Init" 1 "verfügbar" 2 "nicht verfügbar" 3 "asynchron durch Fahrerwunsch" ;
VAL_ 1349 WarnBrems_Charisma_FahrPr 0 "keine_Funktion" 1 "Programm_1" 2 "Programm_2" 3 "Programm_3" 4 "Programm_4" 5 "Programm_5" 6 "Programm_6" 7 "Programm_7" 8 "Programm_8" 9 "Programm_9" 10 "Programm_10" 11 "Programm_11" 12 "Programm_12" 13 "Programm_13" 14 "Programm_14" 15 "Programm_15" ;
VAL_ 1349 AB_Gurtwarn_Reihe2_MI 0 "nicht_verbaut" 1 "keine_Gurtwarnung_Sitz_leer" 2 "keine_Gurtwarnung_Sitz_belegt" 3 "Gurtwarnung_Sitz_belegt" ;
VAL_ 1349 AB_Gurtwarn_Reihe3_FA 0 "nicht_verbaut" 1 "keine_Gurtwarnung_Sitz_leer" 2 "keine_Gurtwarnung_Sitz_belegt" 3 "Gurtwarnung_Sitz_belegt" ;
VAL_ 1349 AB_Gurtwarn_Reihe3_MI 0 "nicht_verbaut" 1 "keine_Gurtwarnung_Sitz_leer" 2 "keine_Gurtwarnung_Sitz_belegt" 3 "Gurtwarnung_Sitz_belegt" ;
VAL_ 1349 AB_Gurtwarn_Reihe3_BF 0 "nicht_verbaut" 1 "keine_Gurtwarnung_Sitz_leer" 2 "keine_Gurtwarnung_Sitz_belegt" 3 "Gurtwarnung_Sitz_belegt" ;
VAL_ 1349 LGI_FAS_Fkt_Status 0 "Init" 1 "Funktion_Ist_Ein" 2 "Funktion_Ist_Aus" 3 "Fehler" ;
VAL_ 1349 PreCrash_FAS_Fkt_Status 0 "Init" 1 "Funktion_Ist_Ein" 2 "Funktion_Ist_Aus" 3 "Fehler" ;
VAL_ 1349 AB_SBR_hinten_verbau 0 "ohne_SBR_hinten" 1 "mit_SBR_hinten" 2 "nicht_definiert" 3 "Init" ;
VAL_ 1349 AWV_Einstellung_System_ASG 0 "deaktiviert" 1 "aktiviert" ;
VAL_ 1349 AWV_Einstellung_Warnung_ASG 0 "Aus" 1 "Setting_2" 2 "Setting_3" 3 "Setting_4" 4 "Setting_5" 5 "Ein" ;
VAL_ 1349 SC_PreSense_Modus_Warnung_NV 0 "Aus" 1 "Setting_2" 2 "Setting_3" 3 "Setting_4" 4 "Setting_5" 5 "Ein" ;
VAL_ 1349 SC_PreSense_Modus_Warnung_MV 0 "Aus" 1 "Setting_2" 2 "Setting_3" 3 "Setting_4" 4 "Setting_5" 5 "Ein" ;
VAL_ 1349 SC_PreSense_Modus_System_MV 0 "deaktiviert" 1 "aktiviert" ;
VAL_ 1349 SC_PreSense_Modus_System_NV 0 "deaktiviert" 1 "aktiviert" ;
VAL_ 1349 SC_PreSense_Modus_System_KAS 0 "deaktiviert" 1 "aktiviert" ;
VAL_ 326 SC_QBit_FASIS_SyncCounter 0 "gueltiger_Wert" 1 "Fehler" ;
VAL_ 1633 AAG_AVS_Fehler_02_inv 0 "Fehler" 1 "kein_Fehler" ;
VAL_ 1633 AAG_Bremsl_durch_ECD 0 "Bremslicht_ist_aus" 1 "Bremslicht_durch_ECD_aktiv" ;
VAL_ 1633 AAG_Anhaenger_abgesteckt 1 "Anhaenger_wurde_bei_KL15_aus_abgesteckt" ;
VAL_ 1633 AAG_NSL_aktiv 0 "Init" 1 "Anhaenger_Nebelschusslicht_aktiv" ;
VAL_ 1633 AAG_Anhaenger_erkannt 0 "kein_Anhaenger_erkannt" 1 "AAG_Anhaenger_erkannt" ;
VAL_ 1633 AAG_Blinker_H_aktiv 0 "Init" 1 "Anhaenger_Blinker_aktiv" ;
VAL_ 1633 AAG_Blinker_HL_def 0 "Init" 1 "Anhaenger_Blinker_links_defekt" ;
VAL_ 1633 AAG_Blinker_HR_def 0 "Init" 1 "Anhaenger_Blinker_rechts_defekt" ;
VAL_ 1633 AAG_Bremslicht_H_def 0 "Init" 1 "Anhaenger_Bremslicht_defekt" ;
VAL_ 1633 AAG_Schlusslicht_HL_def 0 "Init" 1 "Anhaenger_Schlusslicht_links_defekt" ;
VAL_ 1633 AAG_Schlusslicht_HR_def 0 "Init" 1 "Anhaenger_Schlusslicht_rechts_defekt" ;
VAL_ 1633 AAG_Bremslicht_Reku 0 "inaktiv" 1 "aktiv" ;
VAL_ 1633 AAG_AVS_Fehler_02 0 "kein_Fehler" 1 "Fehler" ;
VAL_ 1633 AAG_LED_aktiv 0 "Lampen" 1 "LED" ;
VAL_ 1633 AAG_AVS_Stati 0 "endlage_eingefahren_erreicht" 1 "endlage_ausgefahren_erreicht" 2 "ausfahren_automatik" 3 "einfahren_automatik" 4 "ausfahren_manuell" 5 "einfahren_manuell" 6 "zwischenposition" 7 "nicht_initialisiert" ;
VAL_ 348 ARA_Sensor_02_red_cyclic 0 "Langsame_Zykluszeit_aktiv" 1 "Schnelle_Zykluszeit_aktiv" ;
VAL_ 348 ARA_Sensor_Status 0 "Initialisierung" 1 "i_O" 2 "Guetemass_ungenuegend" 3 "interne_Korrektur_des_Winkels" 4 "keine_auswertbaren_Bilddaten" 5 "sonstiger_Fehler" 6 "Kamera_ueberhitzt" ;
VAL_ 348 ARA_Sensor_Qualitaet_Grund 0 "Umweltbedingung" 1 "Verschmutzung_der_Kamera" ;
VAL_ 348 ARA_Sensor_Knickw_Rohwert_BV 65534 "Init" 65535 "Fehler" ;
VAL_ 345 ARA_Knickwinkel_Konfidenz 126 "Init" 127 "Fehler" ;
VAL_ 345 ARA_Texte 0 "kein Text/Akustik" 63 "Fehler" ;
VAL_ 345 ARA_Modus 0 "Knickwinkelmodus" 1 "Trajektorienmodus" ;
VAL_ 345 ARA_Aktiver_Grafikmodus 0 "keine_Grafik" 1 "Grafikmodus_aktiv" ;
VAL_ 345 ARA_Deaktivierung_sperren 0 "nicht_gesperrt" 1 "gesperrt" ;
VAL_ 345 ARA_Modus_Anf 0 "ARA Modus nicht im TSG angefordert" 1 "ARA Modus im TSG angefordert" ;
VAL_ 345 ARA_Bremsfuss 0 "kein Bremsfuss" 1 "Bremsfuss angefordert" ;
VAL_ 345 ARA_Sensor_Aktivierung 0 "Knickwinkelsensor_deaktivieren" 1 "Knickwinkelsensor_aktivieren" ;
VAL_ 345 ARA_Knickwinkel_Komfort 62 "Init" 63 "Fehler" ;
VAL_ 345 ARA_Status 0 "ARA_Status_inaktiv" 1 "ARA_Status_init" 2 "Fehler" 3 "ARA_Status_Start" 4 "ARA_Status_aktiv" 6 "ARA_Status_Regelung_aktiv" 8 "ARA_Status_betriebsbereit" 9 "ARA_Status_Klemmtraeger_erkannt" 10 "ARA_Status_Abbruch" 11 "ARA_Status_nicht_betriebsbereit" ;
VAL_ 345 ARA_Knickwinkel_Max 126 "Init" 127 "Fehler" ;
VAL_ 345 ARA_Knickwinkel_Soll 254 "Init" 255 "Fehler" ;
VAL_ 345 ARA_Knickwinkel_Ist 254 "Init" 255 "Fehler" ;
VAL_ 1013 ARA_StartStopp_Info 0 "Motorlauf_nicht_notwendig_(Stoppfreigabe)" 1 "Motoranlauf_nicht_zwingend_notwendig_(Stoppverbot,keine_Startanforderung)" 2 "Motoranlauf_zwingend_notwendig_(Startanforderung)" 3 "Systemfehler" ;
VAL_ 1013 ARA_nachtr_Stopp_Anf 0 "nicht_angefordert" 1 "angefordert" ;
VAL_ 1626 BCM_Bremsbelag_Sensor 0 "OK" 1 "Bremsbelag_unter_min" ;
VAL_ 1626 BCM_Bremsfluessigkeit_Sensor 0 "OK" 1 "Bremsfluessigkeit_unter_min" ;
VAL_ 1626 BCM1_Licht_Warn 0 "OK" 1 "Lichtwarnung_aktiv" ;
VAL_ 1626 BCM_Waschwasser_Sensor 0 "OK" 1 "Waschwasser_unter_min" ;
VAL_ 1626 BCM_Kuehlmittel_Sensor 0 "OK" 1 "Kuehlmittel_unter_min" ;
VAL_ 1626 BCM1_Kl_15_HW_erkannt 1 "Klemme 15 erkannt" ;
VAL_ 1626 BCM1_Kl_15_Sig_HW_erkannt 0 "KL15_HW_Signal_von_BCM1_nicht_erkannt" 1 "KL15_HW_Signal_von_BCM1_erkannt" ;
VAL_ 1626 BCM_Kuehlmittel_Sensor_02 0 "OK" 1 "Kuehlmittel_unter_min" ;
VAL_ 1626 BCM1_Hinweis_Lichtnachlauf 0 "inaktiv" 1 "aktiv" ;
VAL_ 1626 BCM_Offroad_Taste 0 "Taster_nicht_betaetigt" 1 "Taster_betaetigt" ;
VAL_ 1626 BCM_Hybrid_StSt_Taste_Fehler 0 "kein_Fehler_StSt_Taster" 1 "Fehler_StSt_Taster" ;
VAL_ 1626 BCM_Hybrid_StartStopp_Taste 0 "nicht_betaetigt" 1 "betaetigt" ;
VAL_ 1626 BCM1_Warnblink_Taster 0 "nicht_betaetigt" 1 "betaetigt" ;
VAL_ 1626 BCM1_Valet_Parking_Taster 0 "nicht_betaetigt" 1 "betaetigt" ;
VAL_ 1626 BCM1_LDS_Stellung 0 "Init" 1 "Stellung_0" 2 "Auto" 3 "Standlicht" 4 "Abblendlicht" 7 "Fehler" ;
VAL_ 1626 BCM1_Rueckfahrlicht_Schalter 0 "nicht_betaetigt" 1 "betaetigt" ;
VAL_ 1626 BCM1_MH_Schalter 0 "MH_geschlossen" 1 "MH_offen" ;
VAL_ 1626 BCM1_MH_WIV_Schalter 0 "MH_geschlossen" 1 "MH_offen" ;
VAL_ 1626 BCM_Eco_Charisma_Taste 0 "nicht_betaetigt" 1 "betaetigt" ;
VAL_ 1626 BCM1_NV_Taster 0 "Taster_nicht_betaetigt" 1 "Taster_betaetigt" ;
VAL_ 1626 BCM1_AFS_Lampe 0 "Aus" 1 "Ein" ;
VAL_ 1626 BCM1_Reisemodus_Texte 0 "keine_Anzeige" 1 "Umschaltung_auf_Linksverkehr_aktiv" 2 "Umschaltung_auf_Rechtsverkehr_aktiv" ;
VAL_ 1626 BCM1_Lichtwarn_Texte 0 "keine_Warnung" 1 "Standlichtwarnung" 2 "Parklichtwarnung" 3 "Nebelschlusslichtwarnung" ;
VAL_ 1626 Gong_TFL_Umschaltung 0 "kein_Gong" 1 "Gong_einmalig" ;
VAL_ 1626 UGDO_Function_01 0 "LED Function" 1 "Transceiver locked" 2 "reserviert" 3 "reserviert" 4 "Successful learned" 5 "reserviert" 6 "Timeout learning" 7 "Fehler" ;
VAL_ 1626 APS_Tongeber_defekt 0 "iO" 1 "defekt" ;
VAL_ 1626 BCM1_EasyEntry_Status 0 "Aus" 1 "Ein" ;
VAL_ 1626 BCM1_Lenksaeule_aktiv 0 "Lenksaeulenverstellung nicht aktiv" 1 "Lenksaeulenverstellung aktiv" ;
VAL_ 1626 BCM1_St_SW_Diebstahl_links 0 "Kein DIebstahl erkannt" 1 "Diebstahl erkannt" ;
VAL_ 1626 BCM1_St_SW_Diebstahl_rechts 0 "Kein DIebstahl erkannt" 1 "Diebstahl erkannt" ;
VAL_ 1626 BCM1_Schluesselsuche_Anf 0 "Anforderung_nicht_aktiv" 1 "Anforderung_aktiv" ;
VAL_ 1626 BCM1_Fahrlicht_Hinweis 0 "kein_Fahrlicht_Hinweis" 1 "Fahrlicht_Hinweis" ;
VAL_ 1626 BCM_HDF_betaetigt 0 "nicht_betaetigt" 1 "betaetigt" ;
VAL_ 2527679637 CPD_Warnung 0 "keine_Warnung" 1 "Warnung_mit_Ton" 2 "Warnung_ohne_Ton" ;
VAL_ 2527679637 BCM_LTM_Nebelschluss_Status 0 "nicht_aktiv" 1 "aktiv" ;
VAL_ 2527679637 BCM_LTM_PopUp_Texte 0 "keine_Anzeige" 1 "Ausschalt_Hinweis" 2 "Ausschalt_Quittierung" ;
VAL_ 2527679637 BCM_LTM_Allwetterl_Status 0 "nicht_aktiv" 1 "aktiv" ;
VAL_ 2527679637 BCM_LTM_PopUp_Status 0 "Init" 1 "AUTO" 2 "Abblendlicht" 3 "Standlicht" 4 "OFF" ;
VAL_ 2527679637 BCM_LTM_Nebell_Status 0 "nicht_aktiv" 1 "aktiv" ;
VAL_ 2527679637 BCM_LTM_PopUp_Anf 0 "keine_Anforderung" 1 "Licht_PopUp" 2 "Nebellicht_PopUp" 3 "Allwetterlicht_PopUp" 4 "Nebelschlusslicht_PopUp" ;
VAL_ 2527679637 BCM_LTM_PopUp_Inhalt 0 "Init" 1 "AUTO" 2 "Abblendlicht" 4 "Standlicht" 8 "OFF" ;
VAL_ 961 Heckrollo_2_Taster 0 "Taste_nicht_betaetigt" 1 "Taste_entprellt_betaetigt" 2 "Init_oder_nicht_verbaut" 3 "Fehler" ;
VAL_ 961 APS_Taster 0 "Taste_nicht_betaetigt" 1 "Taste_entprellt_betaetigt" 2 "Init_oder_nicht_verbaut" 3 "Fehler" ;
VAL_ 961 PLA_Taster 0 "Taste_nicht_betaetigt" 1 "Taste_entprellt_betaetigt" 2 "Init_oder_nicht_verbaut" 3 "Fehler" ;
VAL_ 961 ESP_Off_Taster 0 "Taste_nicht_betaetigt" 1 "Taste_entprellt_betaetigt" 2 "Init_oder_nicht_verbaut" 3 "Fehler" ;
VAL_ 961 HDC_Taster 0 "Taste_nicht_betaetigt" 1 "Taste_entprellt_betaetigt" 2 "Init_oder_nicht_verbaut" 3 "Fehler" ;
VAL_ 961 AVH_Taster 0 "Taste_nicht_betaetigt" 1 "Taste_entprellt_betaetigt" 2 "Init_oder_nicht_verbaut" 3 "Fehler" ;
VAL_ 961 Display_Taster 0 "Taste_nicht_betaetigt" 1 "Taste_entprellt_betaetigt" 2 "Init_oder_nicht_verbaut" 3 "Fehler" ;
VAL_ 961 Heckrollo_Taster 0 "Taste_nicht_betaetigt" 1 "Taste_entprellt_betaetigt" 2 "Init_oder_nicht_verbaut" 3 "Fehler" ;
VAL_ 961 Spoiler_Taster 0 "Taste_nicht_betaetigt" 1 "Taste_entprellt_betaetigt" 2 "Init_oder_nicht_verbaut" 3 "Fehler" ;
VAL_ 961 Drivesel_1_Taster 0 "Taste_nicht_betaetigt" 1 "Taste_entprellt_betaetigt" 2 "Init_oder_nicht_verbaut" 3 "Fehler" ;
VAL_ 961 Drivesel_2_Taster 0 "Taste_nicht_betaetigt" 1 "Taste_entprellt_betaetigt" 2 "Init_oder_nicht_verbaut" 3 "Fehler" ;
VAL_ 961 Sideview_Taster 0 "Taste_nicht_betaetigt" 1 "Taste_entprellt_betaetigt" 2 "Init_oder_nicht_verbaut" 3 "Fehler" ;
VAL_ 961 LKS_Taster 0 "Taste_nicht_betaetigt" 1 "Taste_betaetigt" 2 "INIT_Taste_nicht_verbaut" 3 "Fehler" ;
VAL_ 961 SWA_Taster 0 "nicht_betaetigt" 1 "betaetigt" 2 "nicht_vorhanden" 3 "Fehler" ;
VAL_ 961 LIM_bCall_Taster 0 "nicht_betaetigt" 1 "betaetigt" ;
VAL_ 961 eCall_Taste 0 "button_released" 1 "button_pressed" 2 "discrete_line_broken" 3 "Fehler" ;
VAL_ 961 PLA_Taster_Fehler_Roh 0 "kein Fehler vorhanden" 1 "Fehler vorhanden" ;
VAL_ 961 LIM_PAO_ON_Status 0 "LED aus" 1 "LED an" 2 "LED blinkt" 3 "LED defekt" ;
VAL_ 961 LIM_PAO_OFF_Status 0 "LED aus" 1 "LED an" 2 "LED blinkt" 3 "LED defekt" ;
VAL_ 961 LIM_PAO_Schriftzug_Status 0 "LED aus" 1 "LED an" 2 "LED blinkt" 3 "LED defekt" ;
VAL_ 961 Spoiler_LED_Status 0 "LED_aus" 1 "LED_ein" 2 "LED_blinken" 3 "Fehler" ;
VAL_ 961 AVH_LED_Status 0 "LED_aus" 1 "LED_ein" 2 "LED_blinken" 3 "Fehler" ;
VAL_ 961 HDC_LED_Status 0 "LED_aus" 1 "LED_ein" 2 "LED_blinken" 3 "Fehler" ;
VAL_ 961 PLA_LED_Status 0 "LED_aus" 1 "LED_ein" 2 "LED_blinken" 3 "Fehler" ;
VAL_ 961 APS_LED_Status 0 "LED_aus" 1 "LED_ein" 2 "LED_blinken" 3 "Fehler" ;
VAL_ 1432 BCM_BFS_Fernsteuerung_aktiv 0 "inaktiv" 1 "aktiv" ;
VAL_ 1432 BCM_Soundklappe_Taster 0 "Taster_nicht_Betaetigt" 1 "Taster_Betaetigt" ;
VAL_ 1432 E_Sound_LED_Status 0 "LED_aus" 1 "LED_ein" 2 "LED_blinken" 3 "Fehler" ;
VAL_ 1432 Pilot_Taster 0 "Taste_nicht_betaetigt" 1 "Taste_entprellt_betaetigt" 2 "Init_oder_nicht_verbaut" 3 "Fehler" ;
VAL_ 1432 BCM1_eSound_Taster 0 "Taste_nicht_betaetigt" 1 "Taste_entprellt_betaetigt" 2 "Init_oder_nicht_verbaut" 3 "Fehler" ;
VAL_ 1432 BCM_FS_Programmwippe 0 "Taster_unbetaetigt" 1 "Taster_betaetigt" ;
VAL_ 1432 BCM_BFS_Programmwippe 0 "Taster_unbetaetigt" 1 "Taster_betaetigt" ;
VAL_ 1432 BCM_FS_Multif_Taster 0 "Taster_unbetaetigt" 1 "Taster_betaetigt" ;
VAL_ 1432 BCM_BFS_Multif_Taster 0 "Taster_unbetaetigt" 1 "Taster_betaetigt" ;
VAL_ 1432 BCM_FS_Massage_Taster 0 "Taster_unbetaetigt" 1 "Taster_betaetigt" ;
VAL_ 1432 BCM_BFS_Massage_Taster 0 "Taster_unbetaetigt" 1 "Taster_betaetigt" ;
VAL_ 1432 BCM_FS_Pneumatik_Verstellung 0 "keine_Verstellung" 1 "Pneumatikverstellung_aktiv" ;
VAL_ 1432 BCM_BFS_Pneumatik_Verstellung 0 "keine_Verstellung" 1 "Pneumatikverstellung_aktiv" ;
VAL_ 1432 LIM_Rear_Mode 0 "inaktiv" 1 "aktiv" ;
VAL_ 1432 BCM1_NR_Ride_Height_Up_Taster 0 "Taste_nicht_betaetigt" 1 "Taste_entprellt_betaetigt" 2 "Init_oder_nicht_verbaut" 3 "Fehler" ;
VAL_ 1432 BCM1_NR_Ride_Height_Down_Taster 0 "Taste_nicht_betaetigt" 1 "Taste_entprellt_betaetigt" 2 "Init_oder_nicht_verbaut" 3 "Fehler" ;
VAL_ 1432 LIM_S_Rollo_vo 0 "nicht_betaetigt" 1 "man_zu" 2 "auto_zu" 3 "man_auf" 4 "auto_auf" 5 "stop" 6 "fehler_schalter_haengt" 7 "fehler_schalter_unplausibel" ;
VAL_ 1432 LIM_S_Rollo_hi 0 "nicht_betaetigt" 1 "man_zu" 2 "auto_zu" 3 "man_auf" 4 "auto_auf" 5 "stop" 6 "fehler_schalter_haengt" 7 "fehler_schalter_unplausibel" ;
VAL_ 1432 LIM_S_SAD_Vo 0 "nicht_betaetigt" 1 "man_sl_zu" 2 "auto_sl_zu" 3 "man_sl_auf" 4 "auto_sl_auf" 5 "man_al_auf" 6 "auto_al_auf" 7 "man_al_zu" 8 "auto_al_zu" 9 "stop" 10 "Toggle_Taster_AL_betaetigt" 14 "fehler_schalter_haengt" 15 "fehler_schalter_unplausibel" ;
VAL_ 1432 LIM_S_SAD_hi 0 "nicht_betaetigt" 1 "man_sl_zu" 2 "auto_sl_zu" 3 "man_sl_auf" 4 "auto_sl_auf" 5 "man_al_auf" 6 "auto_al_auf" 7 "man_al_zu" 8 "auto_al_zu" 14 "fehler_schalter_haengt" 15 "fehler_schalter_unplausibel" ;
VAL_ 901 CHA_Ziel_FahrPr_AGA 0 "keine_Funktion" 1 "Programm_1" 2 "Programm_2" 3 "Programm_3" 4 "Programm_4" 5 "Programm_5" 6 "Programm_6" 7 "Programm_7" 8 "Programm_8" 9 "Programm_9" 10 "Programm_10" 11 "Programm_11" 12 "Programm_12" 13 "Programm_13" 14 "Programm_14" 15 "Programm_15" ;
VAL_ 901 CHA_Ziel_FahrPr_ESP 0 "keine_Funktion" 1 "Programm_1" 2 "Programm_2" 3 "Programm_3" 4 "Programm_4" 5 "Programm_5" 6 "Programm_6" 7 "Programm_7" 8 "Programm_8" 9 "Programm_9" 10 "Programm_10" 11 "Programm_11" 12 "Programm_12" 13 "Programm_13" 14 "Programm_14" 15 "Programm_15" ;
VAL_ 901 CHA_Ziel_FahrPr_Freilauf 0 "keine_Funktion" 1 "Programm_1" 2 "Programm_2" 3 "Programm_3" 4 "Programm_4" 5 "Programm_5" 6 "Programm_6" 7 "Programm_7" 8 "Programm_8" 9 "Programm_9" 10 "Programm_10" 11 "Programm_11" 12 "Programm_12" 13 "Programm_13" 14 "Programm_14" 15 "Programm_15" ;
VAL_ 901 CHA_Fahrer_Umschaltung 0 "keine_oder_automatische_Umschaltung" 1 "manuelle_Umschaltung" ;
VAL_ 901 CHA_Fahrer_Umschaltung_BMA 0 "keine_oder_autom_Umschaltung" 1 "manuelle_Umschaltung" ;
VAL_ 901 CHA_Ziel_FahrPr_MO 0 "keine_Funktion" 1 "Programm_1" 2 "Programm_2" 3 "Programm_3" 4 "Programm_4" 5 "Programm_5" 6 "Programm_6" 7 "Programm_7" 8 "Programm_8" 9 "Programm_9" 10 "Programm_10" 11 "Programm_11" 12 "Programm_12" 13 "Programm_13" 14 "Programm_14" 15 "Programm_15" ;
VAL_ 901 CHA_Ziel_FahrPr_GE 0 "keine_Funktion" 1 "Programm_1" 2 "Programm_2" 3 "Programm_3" 4 "Programm_4" 5 "Programm_5" 6 "Programm_6" 7 "Programm_7" 8 "Programm_8" 9 "Programm_9" 10 "Programm_10" 11 "Programm_11" 12 "Programm_12" 13 "Programm_13" 14 "Programm_14" 15 "Programm_15" ;
VAL_ 901 CHA_Ziel_FahrPr_ALR 0 "keine_Funktion" 1 "Programm_1" 2 "Programm_2" 3 "Programm_3" 4 "Programm_4" 5 "Programm_5" 6 "Programm_6" 7 "Programm_7" 8 "Programm_8" 9 "Programm_9" 10 "Programm_10" 11 "Programm_11" 12 "Programm_12" 13 "Programm_13" 14 "Programm_14" 15 "Programm_15" ;
VAL_ 901 CHA_Ziel_FahrPr_MO_BZS 0 "keine_Funktion" 1 "Programm_1" 2 "Programm_2" 3 "Programm_3" 4 "Programm_4" 5 "Programm_5" 6 "Programm_6" 7 "Programm_7" 8 "Programm_8" 9 "Programm_9" 10 "Programm_10" 11 "Programm_11" 12 "Programm_12" 13 "Programm_13" 14 "Programm_14" 15 "Programm_15" ;
VAL_ 901 CHA_Ziel_FahrPr_DR 0 "keine_Funktion" 1 "Programm_1" 2 "Programm_2" 3 "Programm_3" 4 "Programm_4" 5 "Programm_5" 6 "Programm_6" 7 "Programm_7" 8 "Programm_8" 9 "Programm_9" 10 "Programm_10" 11 "Programm_11" 12 "Programm_12" 13 "Programm_13" 14 "Programm_14" 15 "Programm_15" ;
VAL_ 901 CHA_Ziel_FahrPr_VAQ 0 "keine_Funktion" 1 "Programm_1" 2 "Programm_2" 3 "Programm_3" 4 "Programm_4" 5 "Programm_5" 6 "Programm_6" 7 "Programm_7" 8 "Programm_8" 9 "Programm_9" 10 "Programm_10" 11 "Programm_11" 12 "Programm_12" 13 "Programm_13" 14 "Programm_14" 15 "Programm_15" ;
VAL_ 901 CHA_Ziel_FahrPr_AFS 0 "keine_Funktion" 1 "Programm_1" 2 "Programm_2" 3 "Programm_3" 4 "Programm_4" 5 "Programm_5" 6 "Programm_6" 7 "Programm_7" 8 "Programm_8" 9 "Programm_9" 10 "Programm_10" 11 "Programm_11" 12 "Programm_12" 13 "Programm_13" 14 "Programm_14" 15 "Programm_15" ;
VAL_ 901 CHA_Ziel_FahrPr_PreCrash 0 "keine_Funktion" 1 "Programm_1" 2 "Programm_2" 3 "Programm_3" 4 "Programm_4" 5 "Programm_5" 6 "Programm_6" 7 "Programm_7" 8 "Programm_8" 9 "Programm_9" 10 "Programm_10" 11 "Programm_11" 12 "Programm_12" 13 "Programm_13" 14 "Programm_14" 15 "Programm_15" ;
VAL_ 901 CHA_Ziel_FahrPr_EPS 0 "keine_Funktion" 1 "Programm_1" 2 "Programm_2" 3 "Programm_3" 4 "Programm_4" 5 "Programm_5" 6 "Programm_6" 7 "Programm_7" 8 "Programm_8" 9 "Programm_9" 10 "Programm_10" 11 "Programm_11" 12 "Programm_12" 13 "Programm_13" 14 "Programm_14" 15 "Programm_15" ;
VAL_ 901 CHA_Ziel_FahrPr_ACC 0 "keine_Funktion" 1 "Programm_1" 2 "Programm_2" 3 "Programm_3" 4 "Programm_4" 5 "Programm_5" 6 "Programm_6" 7 "Programm_7" 8 "Programm_8" 9 "Programm_9" 10 "Programm_10" 11 "Programm_11" 12 "Programm_12" 13 "Programm_13" 14 "Programm_14" 15 "Programm_15" ;
VAL_ 901 CHA_Ziel_FahrPr_SAK 0 "keine_Funktion" 1 "Programm_1" 2 "Programm_2" 3 "Programm_3" 4 "Programm_4" 5 "Programm_5" 6 "Programm_6" 7 "Programm_7" 8 "Programm_8" 9 "Programm_9" 10 "Programm_10" 11 "Programm_11" 12 "Programm_12" 13 "Programm_13" 14 "Programm_14" 15 "Programm_15" ;
VAL_ 901 CHA_Ziel_FahrPr_MO_StSt 0 "keine_Funktion" 1 "Programm_1" 2 "Programm_2" 3 "Programm_3" 4 "Programm_4" 5 "Programm_5" 6 "Programm_6" 7 "Programm_7" 8 "Programm_8" 9 "Programm_9" 10 "Programm_10" 11 "Programm_11" 12 "Programm_12" 13 "Programm_13" 14 "Programm_14" 15 "Programm_15" ;
VAL_ 1000 CHA_Ziel_FahrPr_EBKV 0 "keine_Funktion" 1 "Programm_1" 2 "Programm_2" 3 "Programm_3" 4 "Programm_4" 5 "Programm_5" 6 "Programm_6" 7 "Programm_7" 8 "Programm_8" 9 "Programm_9" 10 "Programm_10" 11 "Programm_11" 12 "Programm_12" 13 "Programm_13" 14 "Programm_14" 15 "Programm_15" ;
VAL_ 1000 CHA_Ziel_FahrPr_IL 0 "keine_Funktion" 1 "Programm_1" 2 "Programm_2" 3 "Programm_3" 4 "Programm_4" 5 "Programm_5" 6 "Programm_6" 7 "Programm_7" 8 "Programm_8" 9 "Programm_9" 10 "Programm_10" 11 "Programm_11" 12 "Programm_12" 13 "Programm_13" 14 "Programm_14" 15 "Programm_15" ;
VAL_ 1000 CHA_Ziel_FahrPr_WarnBrems 0 "keine_Funktion" 1 "Programm_1" 2 "Programm_2" 3 "Programm_3" 4 "Programm_4" 5 "Programm_5" 6 "Programm_6" 7 "Programm_7" 8 "Programm_8" 9 "Programm_9" 10 "Programm_10" 11 "Programm_11" 12 "Programm_12" 13 "Programm_13" 14 "Programm_14" 15 "Programm_15" ;
VAL_ 1000 CHA_Fahrer_Umschaltung 0 "keine_oder_automatische_Umschaltung" 1 "manuelle_Umschaltung" ;
VAL_ 1000 CHA_Ziel_FahrPr_QS 0 "keine_Funktion" 1 "Programm_1" 2 "Programm_2" 3 "Programm_3" 4 "Programm_4" 5 "Programm_5" 6 "Programm_6" 7 "Programm_7" 8 "Programm_8" 9 "Programm_9" 10 "Programm_10" 11 "Programm_11" 12 "Programm_12" 13 "Programm_13" 14 "Programm_14" 15 "Programm_15" ;
VAL_ 1000 CHA_Ziel_FahrPr_SCU 0 "keine_Funktion" 1 "Programm_1" 2 "Programm_2" 3 "Programm_3" 4 "Programm_4" 5 "Programm_5" 6 "Programm_6" 7 "Programm_7" 8 "Programm_8" 9 "Programm_9" 10 "Programm_10" 11 "Programm_11" 12 "Programm_12" 13 "Programm_13" 14 "Programm_14" 15 "Programm_15" ;
VAL_ 1000 CHA_Ziel_FahrPr_HAL 0 "keine_Funktion" 1 "Programm_1" 2 "Programm_2" 3 "Programm_3" 4 "Programm_4" 5 "Programm_5" 6 "Programm_6" 7 "Programm_7" 8 "Programm_8" 9 "Programm_9" 10 "Programm_10" 11 "Programm_11" 12 "Programm_12" 13 "Programm_13" 14 "Programm_14" 15 "Programm_15" ;
VAL_ 1000 CHA_Ziel_FahrPr_NR 0 "keine_Funktion" 1 "Programm_1" 2 "Programm_2" 3 "Programm_3" 4 "Programm_4" 5 "Programm_5" 6 "Programm_6" 7 "Programm_7" 8 "Programm_8" 9 "Programm_9" 10 "Programm_10" 11 "Programm_11" 12 "Programm_12" 13 "Programm_13" 14 "Programm_14" 15 "Programm_15" ;
VAL_ 1000 CHA_Ziel_FahrPr_AV 0 "keine_Funktion" 1 "Programm_1" 2 "Programm_2" 3 "Programm_3" 4 "Programm_4" 5 "Programm_5" 6 "Programm_6" 7 "Programm_7" 8 "Programm_8" 9 "Programm_9" 10 "Programm_10" 11 "Programm_11" 12 "Programm_12" 13 "Programm_13" 14 "Programm_14" 15 "Programm_15" ;
VAL_ 1000 CHA_Ziel_FahrPr_MXB 0 "keine_Funktion" 1 "Programm_1" 2 "Programm_2" 3 "Programm_3" 4 "Programm_4" 5 "Programm_5" 6 "Programm_6" 7 "Programm_7" 8 "Programm_8" 9 "Programm_9" 10 "Programm_10" 11 "Programm_11" 12 "Programm_12" 13 "Programm_13" 14 "Programm_14" 15 "Programm_15" ;
VAL_ 1000 CHA_Ziel_FahrPr_AFR 0 "keine_Funktion" 1 "Programm_1" 2 "Programm_2" 3 "Programm_3" 4 "Programm_4" 5 "Programm_5" 6 "Programm_6" 7 "Programm_7" 8 "Programm_8" 9 "Programm_9" 10 "Programm_10" 11 "Programm_11" 12 "Programm_12" 13 "Programm_13" 14 "Programm_14" 15 "Programm_15" ;
VAL_ 1000 CHA_Ziel_FahrPr_HDC 0 "keine_Funktion" 1 "Programm_1" 2 "Programm_2" 3 "Programm_3" 4 "Programm_4" 5 "Programm_5" 6 "Programm_6" 7 "Programm_7" 8 "Programm_8" 9 "Programm_9" 10 "Programm_10" 11 "Programm_11" 12 "Programm_12" 13 "Programm_13" 14 "Programm_14" 15 "Programm_15" ;
VAL_ 1000 CHA_Ziel_FahrPr_EAR 0 "keine_Funktion" 1 "Programm_1" 2 "Programm_2" 3 "Programm_3" 4 "Programm_4" 5 "Programm_5" 6 "Programm_6" 7 "Programm_7" 8 "Programm_8" 9 "Programm_9" 10 "Programm_10" 11 "Programm_11" 12 "Programm_12" 13 "Programm_13" 14 "Programm_14" 15 "Programm_15" ;
VAL_ 1000 CHA_Ziel_FahrPr_FCWO 0 "keine_Funktion" 1 "Programm_1" 2 "Programm_2" 3 "Programm_3" 4 "Programm_4" 5 "Programm_5" 6 "Programm_6" 7 "Programm_7" 8 "Programm_8" 9 "Programm_9" 10 "Programm_10" 11 "Programm_11" 12 "Programm_12" 13 "Programm_13" 14 "Programm_14" 15 "Programm_15" ;
VAL_ 1000 CHA_Ziel_FahrPr_FCWP 0 "keine_Funktion" 1 "Programm_1" 2 "Programm_2" 3 "Programm_3" 4 "Programm_4" 5 "Programm_5" 6 "Programm_6" 7 "Programm_7" 8 "Programm_8" 9 "Programm_9" 10 "Programm_10" 11 "Programm_11" 12 "Programm_12" 13 "Programm_13" 14 "Programm_14" 15 "Programm_15" ;
VAL_ 1714 DGN_Verlernzaehler 255 "ungültiger Zählerstand oder kein gültiger Fahrzyklus" ;
VAL_ 1714 KBI_Kilometerstand 1048574 "Init" 1048575 "Fehler" ;
VAL_ 1714 UH_Monat 0 "Init" 14 "Relatives_Datum" 15 "Fehler" ;
VAL_ 1714 UH_Tag 0 "Init" ;
VAL_ 1714 Kombi_02_alt 0 "aktuell" 1 "veraltet" ;
VAL_ 1714 Uhrzeit_01_alt 0 "aktuell" 1 "veraltet" ;
VAL_ 1520 DI_KL_58xd 254 "Init" 255 "Fehler" ;
VAL_ 1520 DI_KL_58xs 126 "Init" 127 "Fehler" ;
VAL_ 1520 DI_KL_58xt 126 "Init" 127 "Fehler" ;
VAL_ 1520 BCM1_Stellgroesse_Kl_58s 125 "Nicht_verbaut" 126 "Init" 127 "Fehler" ;
